VERSION ""

NS_ :

BS_:

BU_: LECU25 LECU23 LECU22 LECU21 LECU19 LECU20 LECU18 LECU17 LECU16 LECU15 LECU14 LECU12 LECU11 LECU10 LECU9 LECU8 LECU7 LECU6 LECU5 LECU4 LECU2 LECU31 LECU30 LECU29 LECU28 LECU27 LECU26 LECU24 LECU13 LECU3 LECU1 BMU Tester LECU32 Host IVT_Mod
VAL_TABLE_ Heating_OverTemperature_Flag 1 "High" 0 "Normal" ;
VAL_TABLE_ GeneralTrueFalse_Value_Table 1 "Error" 0 "Normal" ;
VAL_TABLE_ GeneralErr_Value_Table 3 "EPO" 2 "Alarm" 1 "Warning" 0 "Normal" ;
VAL_TABLE_ Balance_Control 1 "on" 0 "off" ;
VAL_TABLE_ Local_CAN_COM_SYN 1 "执行" 0 "停止" ;
VAL_TABLE_ Control_Code 1 "执行" 0 "停止" ;
VAL_TABLE_ ErrorCode_Tem_High 4 "一级" 3 "二级" 2 "三级" 1 "四级" 0 "正常" ;
VAL_TABLE_ ErrorCode_Voltage_High 4 "一级" 3 "二级" 2 "三级" 1 "四级" 0 "正常" ;
VAL_TABLE_ ErrorCode_Voltage_Low 3 "二级" 2 "三级" 1 "四级" 0 "正常" ;
VAL_TABLE_ LECU_ErrorCode 3284 "第12节电池电压差异较大" 3028 "第11节电池电压差异较大" 2772 "第10节电池电压差异较大" 2516 "第9节电池电压差异较大" 2260 "第8节电池电压差异较大" 2004 "第7节电池电压差异较大" 1748 "第6节电池电压差异较大" 1492 "第5节电池电压差异较大" 1236 "第4节电池电压差异较大" 980 "第3节电池电压差异较大" 724 "第2节电池电压差异较大" 468 "第1节电池电压差异较大" 3283 "第12节电池电压差异大" 3282 "第12节电池电压差异很大" 3252 "第12节电池电压较低" 3027 "第11节电池电压差异大" 3026 "第11节电池电压差异很大" 2996 "第11节电池电压较低" 2771 "第10节电池电压差异大" 2770 "第10节电池电压差异很大" 2740 "第10节电池电压较低" 2515 "第9节电池电压差异大" 2514 "第9节电池电压差异很大" 2484 "第9节电池电压较低" 2259 "第8节电池电压差异大" 2258 "第8节电池电压差异很大" 2228 "第8节电池电压较低" 2003 "第7节电池电压差异大" 2002 "第7节电池电压差异很大" 1972 "第7节电池电压较低" 1747 "第6节电池电压差异大" 1746 "第6节电池电压差异很大" 1716 "第6节电池电压较低" 1491 "第5节电池电压差异大" 1490 "第5节电池电压差异很大" 1460 "第5节电池电压较低" 1235 "第4节电池电压差异大" 1234 "第4节电池电压差异很大" 1204 "第4节电池电压较低" 979 "第3节电池电压差异大" 978 "第3节电池电压差异很大" 948 "第3节电池电压较低" 723 "第2节电池电压差异大" 722 "第2节电池电压差异很大" 692 "第2节电池电压较低" 467 "第1节电池电压差异大" 466 "第1节电池电压差异很大" 436 "第1节电池电压较低" 3251 "第12节电池电压低" 3250 "第12节电池电压很低" 3236 "第12节电池电压较高" 3235 "第12节电池电压高" 2995 "第11节电池电压低" 2994 "第11节电池电压很低" 2980 "第11节电池电压较高" 2979 "第11节电池电压高" 2739 "第10节电池电压低" 2738 "第10节电池电压很低" 2724 "第10节电池电压较高" 2723 "第10节电池电压高" 2483 "第9节电池电压低" 2482 "第9节电池电压很低" 2468 "第9节电池电压较高" 2467 "第9节电池电压高" 2227 "第8节电池电压低" 2226 "第8节电池电压很低" 2212 "第8节电池电压较高" 2211 "第8节电池电压高" 1971 "第7节电池电压低" 1970 "第7节电池电压很低" 1956 "第7节电池电压较高" 1955 "第7节电池电压高" 1715 "第6节电池电压低" 1714 "第6节电池电压很低" 1700 "第6节电池电压较高" 1699 "第6节电池电压高" 1459 "第5节电池电压低" 1458 "第5节电池电压很低" 1444 "第5节电池电压较高" 1443 "第5节电池电压高" 1203 "第4节电池电压低" 1202 "第4节电池电压很低" 1188 "第4节电池电压较高" 1187 "第4节电池电压高" 947 "第3节电池电压低" 946 "第3节电池电压很低" 932 "第3节电池电压较高" 931 "第3节电池电压高" 691 "第2节电池电压低" 690 "第2节电池电压很低" 676 "第2节电池电压较高" 675 "第2节电池电压高" 435 "第1节电池电压低" 434 "第1节电池电压很低" 420 "第1节电池电压较高" 419 "第1节电池电压高" 3234 "第12节电池电压很高" 3233 "第12节电池电压极高" 3188 "第12节电池温度较高" 3187 "第12节电池温度高" 3186 "第12节电池温度很高" 3185 "第12节电池温度极高" 3172 "第12节电池温度差异较大 " 2978 "第11节电池电压很高" 2977 "第11节电池电压极高" 2932 "第11节电池温度较高" 2931 "第11节电池温度高" 2930 "第11节电池温度很高" 2929 "第11节电池温度极高" 2916 "第11节电池温度差异较大 " 2722 "第10节电池电压很高" 2721 "第10节电池电压极高" 2676 "第10节电池温度较高" 2675 "第10节电池温度高" 2674 "第10节电池温度很高" 2673 "第10节电池温度极高" 2660 "第10节电池温度差异较大 " 2466 "第9节电池电压很高" 2465 "第9节电池电压极高" 2420 "第9节电池温度较高" 2419 "第9节电池温度高" 2418 "第9节电池温度很高" 2417 "第9节电池温度极高" 2404 "第9节电池温度差异较大 " 2210 "第8节电池电压很高" 2209 "第8节电池电压极高" 2164 "第8节电池温度较高" 2163 "第8节电池温度高" 2162 "第8节电池温度很高" 2161 "第8节电池温度极高" 2148 "第8节电池温度差异较大 " 1954 "第7节电池电压很高" 1953 "第7节电池电压极高" 1908 "第7节电池温度较高" 1907 "第7节电池温度高" 1906 "第7节电池温度很高" 1905 "第7节电池温度极高" 1892 "第7节电池温度差异较大 " 1698 "第6节电池电压很高" 1697 "第6节电池电压极高" 1652 "第6节电池温度较高" 1651 "第6节电池温度高" 1650 "第6节电池温度很高" 1649 "第6节电池温度极高" 1636 "第6节电池温度差异较大 " 1442 "第5节电池电压很高" 1441 "第5节电池电压极高" 1396 "第5节电池温度较高" 1395 "第5节电池温度高" 1394 "第5节电池温度很高" 1393 "第5节电池温度极高" 1380 "第5节电池温度差异较大 " 1186 "第4节电池电压很高" 1185 "第4节电池电压极高" 1140 "第4节电池温度较高" 1139 "第4节电池温度高" 1138 "第4节电池温度很高" 1137 "第4节电池温度极高" 1124 "第4节电池温度差异较大 " 930 "第3节电池电压很高" 929 "第3节电池电压极高" 884 "第3节电池温度较高" 883 "第3节电池温度高" 882 "第3节电池温度很高" 881 "第3节电池温度极高" 868 "第3节电池温度差异较大 " 674 "第2节电池电压很高" 673 "第2节电池电压极高" 628 "第2节电池温度较高" 627 "第2节电池温度高" 626 "第2节电池温度很高" 625 "第2节电池温度极高" 612 "第2节电池温度差异较大 " 418 "第1节电池电压很高" 417 "第1节电池电压极高" 372 "第1节电池温度较高" 371 "第1节电池温度高" 370 "第1节电池温度很高" 369 "第1节电池温度极高" 356 "第1节电池温度差异较大 " 3171 "第12节电池温度差异大 " 2915 "第11节电池温度差异大 " 2659 "第10节电池温度差异大 " 2403 "第9节电池温度差异大 " 2147 "第8节电池温度差异大 " 1891 "第7节电池温度差异大 " 1635 "第6节电池温度差异大 " 1379 "第5节电池温度差异大 " 1123 "第4节电池温度差异大 " 867 "第3节电池温度差异大 " 611 "第2节电池温度差异大 " 3170 "第12节电池温度差异很大" 3169 "第12节电池温度差异极大" 2914 "第11节电池温度差异很大" 2913 "第11节电池温度差异极大" 2658 "第10节电池温度差异很大" 2657 "第10节电池温度差异极大" 2402 "第9节电池温度差异很大" 2401 "第9节电池温度差异极大" 2146 "第8节电池温度差异很大" 2145 "第8节电池温度差异极大" 1890 "第7节电池温度差异很大" 1889 "第7节电池温度差异极大" 1634 "第6节电池温度差异很大" 1633 "第6节电池温度差异极大" 1378 "第5节电池温度差异很大" 1377 "第5节电池温度差异极大" 1122 "第4节电池温度差异很大" 1121 "第4节电池温度差异极大" 866 "第3节电池温度差异很大" 865 "第3节电池温度差异极大" 610 "第2节电池温度差异很大" 609 "第2节电池温度差异极大" 355 "第1节电池温度差异大 " 354 "第1节电池温度差异很大" 353 "第1节电池温度差异极大" ;

BO_ 3221225472 VECTOR__INDEPENDENT_SIG_MSG: 0 Vector__XXX
 SG_ Local_CtrFb_PosConnector : 0|1@0+ (1,0) [0|0] "" Vector__XXX
 SG_ Local_CtrFb_NegConnector : 0|1@0+ (1,0) [0|0] "" Vector__XXX
 SG_ Local_CtrFb_FcgConnector : 0|1@0+ (1,0) [0|0] "" Vector__XXX
 SG_ Local_CtrFb_ChgConnector : 0|1@0+ (1,0) [0|0] "" Vector__XXX
 SG_ Local_CtrFb_PreChgConnector : 0|1@0+ (1,0) [0|0] "" Vector__XXX
 SG_ Local_Res_IsolationPos : 0|16@0+ (1,0) [0|0] "KΩ" Vector__XXX
 SG_ Local_Res_IsolationNeg : 0|16@0+ (1,0) [0|0] "KΩ" Vector__XXX

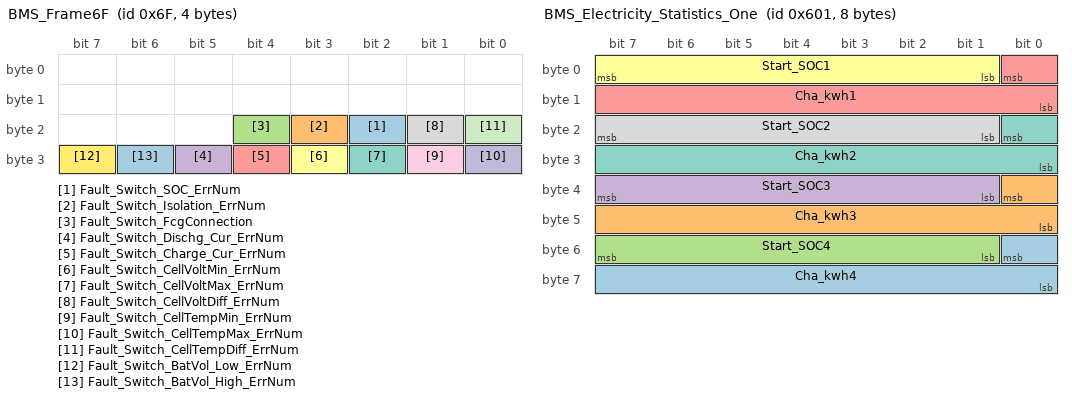
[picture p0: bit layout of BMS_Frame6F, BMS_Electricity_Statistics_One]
BO_ 111 BMS_Frame6F: 4 Vector__XXX
 SG_ Fault_Switch_SOC_ErrNum : 18|1@1+ (1,0) [0|0] "" Vector__XXX
 SG_ Fault_Switch_Isolation_ErrNum : 19|1@1+ (1,0) [0|0] "" Vector__XXX
 SG_ Fault_Switch_FcgConnection : 20|1@1+ (1,0) [0|0] "" Vector__XXX
 SG_ Fault_Switch_Dischg_Cur_ErrNum : 29|1@1+ (1,0) [0|0] "" Vector__XXX
 SG_ Fault_Switch_Charge_Cur_ErrNum : 28|1@1+ (1,0) [0|0] "" Vector__XXX
 SG_ Fault_Switch_CellVoltMin_ErrNum : 27|1@1+ (1,0) [0|0] "" Vector__XXX
 SG_ Fault_Switch_CellVoltMax_ErrNum : 26|1@1+ (1,0) [0|0] "" Vector__XXX
 SG_ Fault_Switch_CellVoltDiff_ErrNum : 17|1@1+ (1,0) [0|0] "" Vector__XXX
 SG_ Fault_Switch_CellTempMin_ErrNum : 25|1@1+ (1,0) [0|0] "" Vector__XXX
 SG_ Fault_Switch_CellTempMax_ErrNum : 24|1@1+ (1,0) [0|0] "" Vector__XXX
 SG_ Fault_Switch_CellTempDiff_ErrNum : 16|1@1+ (1,0) [0|0] "" Vector__XXX
 SG_ Fault_Switch_BatVol_Low_ErrNum : 31|1@1+ (1,0) [0|0] "" Vector__XXX
 SG_ Fault_Switch_BatVol_High_ErrNum : 30|1@1+ (1,0) [0|0] "" Vector__XXX

BO_ 101 BMS_Frame15: 8 Vector__XXX
 SG_ Local_Curr_Bus_Copy_3 : 39|16@0+ (0.1,-3200) [0|0] "A" Vector__XXX
 SG_ Local_Curr_Bus_Copy_2 : 23|16@0+ (0.1,-3200) [0|0] "A" Vector__XXX
 SG_ Local_Curr_Bus_Copy_1 : 7|16@0+ (0.1,-3200) [0|0] "A" Vector__XXX
 SG_ Local_Curr_Bus : 55|16@0+ (0.1,-3200) [0|0] "A" Vector__XXX

BO_ 100 BMS_Frame14: 8 Vector__XXX
 SG_ Local_Curr_Bus_Copy_3 : 39|16@0+ (0.1,-3200) [0|0] "A" Vector__XXX
 SG_ Local_Curr_Bus_Copy_2 : 23|16@0+ (0.1,-3200) [0|0] "A" Vector__XXX
 SG_ Local_Curr_Bus_Copy_1 : 7|16@0+ (0.1,-3200) [0|0] "A" Vector__XXX
 SG_ Local_Curr_Bus : 55|16@0+ (0.1,-3200) [0|0] "A" Vector__XXX

BO_ 261 BMS_External_Cmd: 8 Vector__XXX
 SG_ External_Sleep_Cmd : 15|8@0+ (1,0) [0|0] ""  BMU
 SG_ External_Fcg_Cmd : 7|8@0+ (1,0) [0|0] ""  BMU

BO_ 1520 Local_ShH_IsoMsg: 8 Vector__XXX
 SG_ Local_ShH_Volt : 31|16@0+ (1,0) [0|0] "V"  BMU
 SG_ Local_ShH_LifeSignal : 63|8@0+ (1,0) [0|0] ""  BMU
 SG_ Local_ShH_IsoResistance : 15|16@0+ (1,0) [0|0] "kΩ"  BMU
 SG_ Local_ShH_IsoMonitorState : 3|4@0+ (1,0) [0|0] ""  BMU
 SG_ Local_ShH_IsoFault : 5|2@0- (1,0) [0|0] ""  BMU

BO_ 1320 IVT_Msg_Result_Wh: 6 Vector__XXX
 SG_ IVT_Result_Wh : 23|32@0- (1,0) [0|0] "Wh"  BMU

BO_ 1316 IVT_Msg_Result_U3: 6 Vector__XXX
 SG_ IVT_Result_U3 : 23|32@0- (1,0) [0|0] "mV"  BMU

BO_ 1315 IVT_Msg_Result_U2: 6 Vector__XXX
 SG_ IVT_Result_U2 : 23|32@0- (1,0) [0|0] "mV"  BMU

BO_ 1314 IVT_Msg_Result_U1: 6 Vector__XXX
 SG_ IVT_Result_U1 : 23|32@0- (1,0) [0|0] "mV"  BMU

BO_ 1317 IVT_Msg_Result_T: 6 Vector__XXX
 SG_ IVT_Result_T : 23|32@0- (0.1,0) [0|0] "℃"  BMU

BO_ 1313 IVT_Msg_Result_I: 6 Vector__XXX
 SG_ IVT_Result_I : 23|32@0- (1,0) [0|0] "mA"  BMU

BO_ 260 BMS_LECUTemBlock: 8 Vector__XXX
 SG_ Block_peak2_TemCHN : 23|16@0+ (1,0) [0|0] "" Vector__XXX
 SG_ CellMoreThan5Temp : 34|6@0+ (1,0) [0|0] "" Vector__XXX
 SG_ BlockTemNUM : 39|4@0+ (1,0) [0|0] "" Vector__XXX
 SG_ Block_peak1_TemCHN : 7|16@0+ (1,0) [0|0] "" Vector__XXX

BO_ 259 BMS_Heating_CMD: 8 Vector__XXX
 SG_ DisCharge_Heating_cmd : 7|8@0+ (1,0) [0|0] ""  BMU
 SG_ Charge_Heating_cmd : 15|8@0+ (1,0) [0|0] ""  BMU

BO_ 258 BMS_Emergency_PowerON: 8 Vector__XXX
 SG_ Emergency_Running_Cmd : 15|8@0+ (1,0) [0|255] ""  BMU
 SG_ Emergency_PowerON_Cmd : 7|8@0+ (1,0) [0|0] ""  BMU

BO_ 1537 BMS_Electricity_Statistics_One: 8 BMU
 SG_ Cha_kwh4 : 48|9@0+ (1,0) [0|511] "kwh" Vector__XXX
 SG_ Cha_kwh3 : 32|9@0+ (1,0) [0|511] "kwh" Vector__XXX
 SG_ Start_SOC4 : 55|7@0+ (1,0) [0|127] "%" Vector__XXX
 SG_ Start_SOC3 : 39|7@0+ (1,0) [0|127] "%" Vector__XXX
 SG_ Cha_kwh1 : 0|9@0+ (1,0) [0|511] "kwh" Vector__XXX
 SG_ Start_SOC1 : 7|7@0+ (1,0) [0|127] "%" Vector__XXX
 SG_ Cha_kwh2 : 16|9@0+ (1,0) [0|511] "kwh" Vector__XXX
 SG_ Start_SOC2 : 23|7@0+ (1,0) [0|127] "%" Vector__XXX

BO_ 274 Lecu1MsgB: 8 Vector__XXX
 SG_ M1_Heating_OverTemp_Flag : 27|1@1+ (1,0) [0|0] ""  BMU
 SG_ M1_TempFault : 29|1@1+ (1,0) [0|0] ""  BMU
 SG_ M1_BatteryLost_Error : 28|1@1+ (1,0) [0|0] ""  BMU
 SG_ M1_JumperTemp_Max m1 : 48|11@1+ (0.1,-40) [0|0] "℃"  BMU
 SG_ M1_BalanceTemp_Max m0 : 48|11@1+ (0.1,-40) [0|0] "℃"  BMU
 SG_ M1_BalanceFailure : 30|1@1+ (1,0) [0|0] ""  BMU
 SG_ M1_Tem_Min_Num : 40|3@1+ (1,0) [0|0] ""  BMU
 SG_ M1_Tem_Max_Num : 32|3@1+ (1,0) [0|0] ""  BMU
 SG_ M1_CellVoltageMin_Num : 43|5@1+ (1,0) [0|31] ""  BMU
 SG_ M1_CellVoltageMax_Num : 35|5@1+ (1,0) [0|31] ""  BMU
 SG_ M1_JumperTemp_Max_Valid m1 : 63|1@1+ (1,0) [0|0] ""  BMU
 SG_ M1_BalanceTemp_Max_Valid m0 : 63|1@1+ (1,0) [0|0] ""  BMU
 SG_ M1_Temp_Choice M : 59|4@1+ (1,0) [0|0] ""  BMU
 SG_ M1_Tem_Mean_Valid : 31|1@1+ (1,0) [0|0] ""  BMU
 SG_ M1_CellVoltageMean_Valid : 15|1@1+ (1,0) [0|0] ""  BMU
 SG_ M1_Tem_Mean : 16|11@1+ (0.1,-40) [0|0] "℃"  BMU
 SG_ M1_CellVoltageMean : 0|15@1- (0.001,0) [0|0] "V"  BMU

BO_ 618 Lecu22MsgI: 8 Vector__XXX
 SG_ M22_Time_Cell1Balance : 0|16@1+ (0.5,0) [0|0] "Hour" Vector__XXX
 SG_ M22_Time_Cell2Balance : 16|16@1+ (0.5,0) [0|0] "Hour" Vector__XXX
 SG_ M22_Time_Cell3Balance : 32|16@1+ (0.5,0) [0|0] "Hour" Vector__XXX
 SG_ M22_Time_Cell4Balance : 48|16@1+ (0.5,0) [0|0] "Hour" Vector__XXX

BO_ 684 Lecu26MsgK: 8 Vector__XXX
 SG_ M26_Time_Cell10Balance : 16|16@1+ (0.5,0) [0|0] "Hour" Vector__XXX
 SG_ M26_Time_Cell11Balance : 32|16@1+ (0.5,0) [0|0] "Hour" Vector__XXX
 SG_ M26_Time_Cell12Balance : 48|16@1+ (0.5,0) [0|0] "Hour" Vector__XXX
 SG_ M26_Time_Cell9Balance : 0|16@1+ (0.5,0) [0|0] "Hour" Vector__XXX

BO_ 683 Lecu26MsgJ: 8 Vector__XXX
 SG_ M26_Time_Cell8Balance : 48|16@1+ (0.5,0) [0|0] "Hour" Vector__XXX
 SG_ M26_Time_Cell7Balance : 32|16@1+ (0.5,0) [0|0] "Hour" Vector__XXX
 SG_ M26_Time_Cell6Balance : 16|16@1+ (0.5,0) [0|0] "Hour" Vector__XXX
 SG_ M26_Time_Cell5Balance : 0|16@1+ (0.5,0) [0|0] "Hour" Vector__XXX

BO_ 730 Lecu29MsgI: 8 Vector__XXX
 SG_ M29_Time_Cell4Balance : 48|16@1+ (0.5,0) [0|0] "Hour" Vector__XXX
 SG_ M29_Time_Cell3Balance : 32|16@1+ (0.5,0) [0|0] "Hour" Vector__XXX
 SG_ M29_Time_Cell2Balance : 16|16@1+ (0.5,0) [0|0] "Hour" Vector__XXX
 SG_ M29_Time_Cell1Balance : 0|16@1+ (0.5,0) [0|0] "Hour" Vector__XXX

BO_ 668 Lecu25MsgK: 8 Vector__XXX
 SG_ M25_Time_Cell10Balance : 16|16@1+ (0.5,0) [0|0] "Hour" Vector__XXX
 SG_ M25_Time_Cell11Balance : 32|16@1+ (0.5,0) [0|0] "Hour" Vector__XXX
 SG_ M25_Time_Cell12Balance : 48|16@1+ (0.5,0) [0|0] "Hour" Vector__XXX
 SG_ M25_Time_Cell9Balance : 0|16@1+ (0.5,0) [0|0] "Hour" Vector__XXX

BO_ 667 Lecu25MsgJ: 8 Vector__XXX
 SG_ M25_Time_Cell8Balance : 48|16@1+ (0.5,0) [0|0] "Hour" Vector__XXX
 SG_ M25_Time_Cell7Balance : 32|16@1+ (0.5,0) [0|0] "Hour" Vector__XXX
 SG_ M25_Time_Cell6Balance : 16|16@1+ (0.5,0) [0|0] "Hour" Vector__XXX
 SG_ M25_Time_Cell5Balance : 0|16@1+ (0.5,0) [0|0] "Hour" Vector__XXX

BO_ 746 Lecu30MsgI: 8 Vector__XXX
 SG_ M30_Time_Cell4Balance : 48|16@1+ (0.5,0) [0|0] "Hour" Vector__XXX
 SG_ M30_Time_Cell3Balance : 32|16@1+ (0.5,0) [0|0] "Hour" Vector__XXX
 SG_ M30_Time_Cell2Balance : 16|16@1+ (0.5,0) [0|0] "Hour" Vector__XXX
 SG_ M30_Time_Cell1Balance : 0|16@1+ (0.5,0) [0|0] "Hour" Vector__XXX

BO_ 636 Lecu23MsgK: 8 Vector__XXX
 SG_ M23_Time_Cell10Balance : 16|16@1+ (0.5,0) [0|0] "Hour" Vector__XXX
 SG_ M23_Time_Cell11Balance : 32|16@1+ (0.5,0) [0|0] "Hour" Vector__XXX
 SG_ M23_Time_Cell12Balance : 48|16@1+ (0.5,0) [0|0] "Hour" Vector__XXX
 SG_ M23_Time_Cell9Balance : 0|16@1+ (0.5,0) [0|0] "Hour" Vector__XXX

BO_ 635 Lecu23MsgJ: 8 Vector__XXX
 SG_ M23_Time_Cell8Balance : 48|16@1+ (0.5,0) [0|0] "Hour" Vector__XXX
 SG_ M23_Time_Cell7Balance : 32|16@1+ (0.5,0) [0|0] "Hour" Vector__XXX
 SG_ M23_Time_Cell6Balance : 16|16@1+ (0.5,0) [0|0] "Hour" Vector__XXX
 SG_ M23_Time_Cell5Balance : 0|16@1+ (0.5,0) [0|0] "Hour" Vector__XXX

BO_ 778 Lecu32MsgI: 8 Vector__XXX
 SG_ M32_Time_Cell4Balance : 48|16@1+ (0.5,0) [0|0] "Hour" Vector__XXX
 SG_ M32_Time_Cell3Balance : 32|16@1+ (0.5,0) [0|0] "Hour" Vector__XXX
 SG_ M32_Time_Cell2Balance : 16|16@1+ (0.5,0) [0|0] "Hour" Vector__XXX
 SG_ M32_Time_Cell1Balance : 0|16@1+ (0.5,0) [0|0] "Hour" Vector__XXX

BO_ 620 Lecu22MsgK: 8 Vector__XXX
 SG_ M22_Time_Cell10Balance : 16|16@1+ (0.5,0) [0|0] "Hour" Vector__XXX
 SG_ M22_Time_Cell11Balance : 32|16@1+ (0.5,0) [0|0] "Hour" Vector__XXX
 SG_ M22_Time_Cell12Balance : 48|16@1+ (0.5,0) [0|0] "Hour" Vector__XXX
 SG_ M22_Time_Cell9Balance : 0|16@1+ (0.5,0) [0|0] "Hour" Vector__XXX

BO_ 619 Lecu22MsgJ: 8 Vector__XXX
 SG_ M22_Time_Cell8Balance : 48|16@1+ (0.5,0) [0|0] "Hour" Vector__XXX
 SG_ M22_Time_Cell7Balance : 32|16@1+ (0.5,0) [0|0] "Hour" Vector__XXX
 SG_ M22_Time_Cell6Balance : 16|16@1+ (0.5,0) [0|0] "Hour" Vector__XXX
 SG_ M22_Time_Cell5Balance : 0|16@1+ (0.5,0) [0|0] "Hour" Vector__XXX

BO_ 602 Lecu21MsgI: 8 Vector__XXX
 SG_ M21_Time_Cell4Balance : 48|16@1+ (0.5,0) [0|0] "Hour" Vector__XXX
 SG_ M21_Time_Cell3Balance : 32|16@1+ (0.5,0) [0|0] "Hour" Vector__XXX
 SG_ M21_Time_Cell2Balance : 16|16@1+ (0.5,0) [0|0] "Hour" Vector__XXX
 SG_ M21_Time_Cell1Balance : 0|16@1+ (0.5,0) [0|0] "Hour" Vector__XXX

BO_ 604 Lecu21MsgK: 8 Vector__XXX
 SG_ M21_Time_Cell10Balance : 16|16@1+ (0.5,0) [0|0] "Hour" Vector__XXX
 SG_ M21_Time_Cell11Balance : 32|16@1+ (0.5,0) [0|0] "Hour" Vector__XXX
 SG_ M21_Time_Cell12Balance : 48|16@1+ (0.5,0) [0|0] "Hour" Vector__XXX
 SG_ M21_Time_Cell9Balance : 0|16@1+ (0.5,0) [0|0] "Hour" Vector__XXX

BO_ 603 Lecu21MsgJ: 8 Vector__XXX
 SG_ M21_Time_Cell8Balance : 48|16@1+ (0.5,0) [0|0] "Hour" Vector__XXX
 SG_ M21_Time_Cell7Balance : 32|16@1+ (0.5,0) [0|0] "Hour" Vector__XXX
 SG_ M21_Time_Cell6Balance : 16|16@1+ (0.5,0) [0|0] "Hour" Vector__XXX
 SG_ M21_Time_Cell5Balance : 0|16@1+ (0.5,0) [0|0] "Hour" Vector__XXX

BO_ 586 Lecu20MsgI: 8 Vector__XXX
 SG_ M20_Time_Cell4Balance : 48|16@1+ (0.5,0) [0|0] "Hour" Vector__XXX
 SG_ M20_Time_Cell3Balance : 32|16@1+ (0.5,0) [0|0] "Hour" Vector__XXX
 SG_ M20_Time_Cell2Balance : 16|16@1+ (0.5,0) [0|0] "Hour" Vector__XXX
 SG_ M20_Time_Cell1Balance : 0|16@1+ (0.5,0) [0|0] "Hour" Vector__XXX

BO_ 588 Lecu20MsgK: 8 Vector__XXX
 SG_ M20_Time_Cell10Balance : 16|16@1+ (0.5,0) [0|0] "Hour" Vector__XXX
 SG_ M20_Time_Cell11Balance : 32|16@1+ (0.5,0) [0|0] "Hour" Vector__XXX
 SG_ M20_Time_Cell12Balance : 48|16@1+ (0.5,0) [0|0] "Hour" Vector__XXX
 SG_ M20_Time_Cell9Balance : 0|16@1+ (0.5,0) [0|0] "Hour" Vector__XXX

BO_ 587 Lecu20MsgJ: 8 Vector__XXX
 SG_ M20_Time_Cell8Balance : 48|16@1+ (0.5,0) [0|0] "Hour" Vector__XXX
 SG_ M20_Time_Cell7Balance : 32|16@1+ (0.5,0) [0|0] "Hour" Vector__XXX
 SG_ M20_Time_Cell6Balance : 16|16@1+ (0.5,0) [0|0] "Hour" Vector__XXX
 SG_ M20_Time_Cell5Balance : 0|16@1+ (0.5,0) [0|0] "Hour" Vector__XXX

BO_ 570 Lecu19MsgI: 8 Vector__XXX
 SG_ M19_Time_Cell4Balance : 48|16@1+ (0.5,0) [0|0] "Hour" Vector__XXX
 SG_ M19_Time_Cell3Balance : 32|16@1+ (0.5,0) [0|0] "Hour" Vector__XXX
 SG_ M19_Time_Cell2Balance : 16|16@1+ (0.5,0) [0|0] "Hour" Vector__XXX
 SG_ M19_Time_Cell1Balance : 0|16@1+ (0.5,0) [0|0] "Hour" Vector__XXX

BO_ 572 Lecu19MsgK: 8 Vector__XXX
 SG_ M19_Time_Cell10Balance : 16|16@1+ (0.5,0) [0|0] "Hour" Vector__XXX
 SG_ M19_Time_Cell11Balance : 32|16@1+ (0.5,0) [0|0] "Hour" Vector__XXX
 SG_ M19_Time_Cell12Balance : 48|16@1+ (0.5,0) [0|0] "Hour" Vector__XXX
 SG_ M19_Time_Cell9Balance : 0|16@1+ (0.5,0) [0|0] "Hour" Vector__XXX

BO_ 571 Lecu19MsgJ: 8 Vector__XXX
 SG_ M19_Time_Cell8Balance : 48|16@1+ (0.5,0) [0|0] "Hour" Vector__XXX
 SG_ M19_Time_Cell7Balance : 32|16@1+ (0.5,0) [0|0] "Hour" Vector__XXX
 SG_ M19_Time_Cell6Balance : 16|16@1+ (0.5,0) [0|0] "Hour" Vector__XXX
 SG_ M19_Time_Cell5Balance : 0|16@1+ (0.5,0) [0|0] "Hour" Vector__XXX

BO_ 554 Lecu18MsgI: 8 Vector__XXX
 SG_ M18_Time_Cell4Balance : 48|16@1+ (0.5,0) [0|0] "Hour" Vector__XXX
 SG_ M18_Time_Cell3Balance : 32|16@1+ (0.5,0) [0|0] "Hour" Vector__XXX
 SG_ M18_Time_Cell2Balance : 16|16@1+ (0.5,0) [0|0] "Hour" Vector__XXX
 SG_ M18_Time_Cell1Balance : 0|16@1+ (0.5,0) [0|0] "Hour" Vector__XXX

BO_ 556 Lecu18MsgK: 8 Vector__XXX
 SG_ M18_Time_Cell10Balance : 16|16@1+ (0.5,0) [0|0] "Hour" Vector__XXX
 SG_ M18_Time_Cell11Balance : 32|16@1+ (0.5,0) [0|0] "Hour" Vector__XXX
 SG_ M18_Time_Cell12Balance : 48|16@1+ (0.5,0) [0|0] "Hour" Vector__XXX
 SG_ M18_Time_Cell9Balance : 0|16@1+ (0.5,0) [0|0] "Hour" Vector__XXX

BO_ 555 Lecu18MsgJ: 8 Vector__XXX
 SG_ M18_Time_Cell8Balance : 48|16@1+ (0.5,0) [0|0] "Hour" Vector__XXX
 SG_ M18_Time_Cell7Balance : 32|16@1+ (0.5,0) [0|0] "Hour" Vector__XXX
 SG_ M18_Time_Cell6Balance : 16|16@1+ (0.5,0) [0|0] "Hour" Vector__XXX
 SG_ M18_Time_Cell5Balance : 0|16@1+ (0.5,0) [0|0] "Hour" Vector__XXX

BO_ 538 Lecu17MsgI: 8 Vector__XXX
 SG_ M17_Time_Cell4Balance : 48|16@1+ (0.5,0) [0|0] "Hour" Vector__XXX
 SG_ M17_Time_Cell3Balance : 32|16@1+ (0.5,0) [0|0] "Hour" Vector__XXX
 SG_ M17_Time_Cell2Balance : 16|16@1+ (0.5,0) [0|0] "Hour" Vector__XXX
 SG_ M17_Time_Cell1Balance : 0|16@1+ (0.5,0) [0|0] "Hour" Vector__XXX

BO_ 540 Lecu17MsgK: 8 Vector__XXX
 SG_ M17_Time_Cell10Balance : 16|16@1+ (0.5,0) [0|0] "Hour" Vector__XXX
 SG_ M17_Time_Cell11Balance : 32|16@1+ (0.5,0) [0|0] "Hour" Vector__XXX
 SG_ M17_Time_Cell12Balance : 48|16@1+ (0.5,0) [0|0] "Hour" Vector__XXX
 SG_ M17_Time_Cell9Balance : 0|16@1+ (0.5,0) [0|0] "Hour" Vector__XXX

BO_ 539 Lecu17MsgJ: 8 Vector__XXX
 SG_ M17_Time_Cell8Balance : 48|16@1+ (0.5,0) [0|0] "Hour" Vector__XXX
 SG_ M17_Time_Cell7Balance : 32|16@1+ (0.5,0) [0|0] "Hour" Vector__XXX
 SG_ M17_Time_Cell6Balance : 16|16@1+ (0.5,0) [0|0] "Hour" Vector__XXX
 SG_ M17_Time_Cell5Balance : 0|16@1+ (0.5,0) [0|0] "Hour" Vector__XXX

BO_ 522 Lecu16MsgI: 8 Vector__XXX
 SG_ M16_Time_Cell4Balance : 48|16@1+ (0.5,0) [0|0] "Hour" Vector__XXX
 SG_ M16_Time_Cell3Balance : 32|16@1+ (0.5,0) [0|0] "Hour" Vector__XXX
 SG_ M16_Time_Cell2Balance : 16|16@1+ (0.5,0) [0|0] "Hour" Vector__XXX
 SG_ M16_Time_Cell1Balance : 0|16@1+ (0.5,0) [0|0] "Hour" Vector__XXX

BO_ 524 Lecu16MsgK: 8 Vector__XXX
 SG_ M16_Time_Cell10Balance : 16|16@1+ (0.5,0) [0|0] "Hour" Vector__XXX
 SG_ M16_Time_Cell11Balance : 32|16@1+ (0.5,0) [0|0] "Hour" Vector__XXX
 SG_ M16_Time_Cell12Balance : 48|16@1+ (0.5,0) [0|0] "Hour" Vector__XXX
 SG_ M16_Time_Cell9Balance : 0|16@1+ (0.5,0) [0|0] "Hour" Vector__XXX

BO_ 523 Lecu16MsgJ: 8 Vector__XXX
 SG_ M16_Time_Cell8Balance : 48|16@1+ (0.5,0) [0|0] "Hour" Vector__XXX
 SG_ M16_Time_Cell7Balance : 32|16@1+ (0.5,0) [0|0] "Hour" Vector__XXX
 SG_ M16_Time_Cell6Balance : 16|16@1+ (0.5,0) [0|0] "Hour" Vector__XXX
 SG_ M16_Time_Cell5Balance : 0|16@1+ (0.5,0) [0|0] "Hour" Vector__XXX

BO_ 506 Lecu15MsgI: 8 Vector__XXX
 SG_ M15_Time_Cell4Balance : 48|16@1+ (0.5,0) [0|0] "Hour" Vector__XXX
 SG_ M15_Time_Cell3Balance : 32|16@1+ (0.5,0) [0|0] "Hour" Vector__XXX
 SG_ M15_Time_Cell2Balance : 16|16@1+ (0.5,0) [0|0] "Hour" Vector__XXX
 SG_ M15_Time_Cell1Balance : 0|16@1+ (0.5,0) [0|0] "Hour" Vector__XXX

BO_ 508 Lecu15MsgK: 8 Vector__XXX
 SG_ M15_Time_Cell10Balance : 16|16@1+ (0.5,0) [0|0] "Hour" Vector__XXX
 SG_ M15_Time_Cell11Balance : 32|16@1+ (0.5,0) [0|0] "Hour" Vector__XXX
 SG_ M15_Time_Cell12Balance : 48|16@1+ (0.5,0) [0|0] "Hour" Vector__XXX
 SG_ M15_Time_Cell9Balance : 0|16@1+ (0.5,0) [0|0] "Hour" Vector__XXX

BO_ 507 Lecu15MsgJ: 8 Vector__XXX
 SG_ M15_Time_Cell8Balance : 48|16@1+ (0.5,0) [0|0] "Hour" Vector__XXX
 SG_ M15_Time_Cell7Balance : 32|16@1+ (0.5,0) [0|0] "Hour" Vector__XXX
 SG_ M15_Time_Cell6Balance : 16|16@1+ (0.5,0) [0|0] "Hour" Vector__XXX
 SG_ M15_Time_Cell5Balance : 0|16@1+ (0.5,0) [0|0] "Hour" Vector__XXX

BO_ 490 Lecu14MsgI: 8 Vector__XXX
 SG_ M14_Time_Cell4Balance : 48|16@1+ (0.5,0) [0|0] "Hour" Vector__XXX
 SG_ M14_Time_Cell3Balance : 32|16@1+ (0.5,0) [0|0] "Hour" Vector__XXX
 SG_ M14_Time_Cell2Balance : 16|16@1+ (0.5,0) [0|0] "Hour" Vector__XXX
 SG_ M14_Time_Cell1Balance : 0|16@1+ (0.5,0) [0|0] "Hour" Vector__XXX

BO_ 492 Lecu14MsgK: 8 Vector__XXX
 SG_ M14_Time_Cell10Balance : 16|16@1+ (0.5,0) [0|0] "Hour" Vector__XXX
 SG_ M14_Time_Cell11Balance : 32|16@1+ (0.5,0) [0|0] "Hour" Vector__XXX
 SG_ M14_Time_Cell12Balance : 48|16@1+ (0.5,0) [0|0] "Hour" Vector__XXX
 SG_ M14_Time_Cell9Balance : 0|16@1+ (0.5,0) [0|0] "Hour" Vector__XXX

BO_ 491 Lecu14MsgJ: 8 Vector__XXX
 SG_ M14_Time_Cell8Balance : 48|16@1+ (0.5,0) [0|0] "Hour" Vector__XXX
 SG_ M14_Time_Cell7Balance : 32|16@1+ (0.5,0) [0|0] "Hour" Vector__XXX
 SG_ M14_Time_Cell6Balance : 16|16@1+ (0.5,0) [0|0] "Hour" Vector__XXX
 SG_ M14_Time_Cell5Balance : 0|16@1+ (0.5,0) [0|0] "Hour" Vector__XXX

BO_ 474 Lecu13MsgI: 8 Vector__XXX
 SG_ M13_Time_Cell4Balance : 48|16@1+ (0.5,0) [0|0] "Hour" Vector__XXX
 SG_ M13_Time_Cell3Balance : 32|16@1+ (0.5,0) [0|0] "Hour" Vector__XXX
 SG_ M13_Time_Cell2Balance : 16|16@1+ (0.5,0) [0|0] "Hour" Vector__XXX
 SG_ M13_Time_Cell1Balance : 0|16@1+ (0.5,0) [0|0] "Hour" Vector__XXX

BO_ 460 Lecu12MsgK: 8 Vector__XXX
 SG_ M12_Time_Cell10Balance : 16|16@1+ (0.5,0) [0|0] "Hour" Vector__XXX
 SG_ M12_Time_Cell11Balance : 32|16@1+ (0.5,0) [0|0] "Hour" Vector__XXX
 SG_ M12_Time_Cell12Balance : 48|16@1+ (0.5,0) [0|0] "Hour" Vector__XXX
 SG_ M12_Time_Cell9Balance : 0|16@1+ (0.5,0) [0|0] "Hour" Vector__XXX

BO_ 459 Lecu12MsgJ: 8 Vector__XXX
 SG_ M12_Time_Cell8Balance : 48|16@1+ (0.5,0) [0|0] "Hour" Vector__XXX
 SG_ M12_Time_Cell7Balance : 32|16@1+ (0.5,0) [0|0] "Hour" Vector__XXX
 SG_ M12_Time_Cell6Balance : 16|16@1+ (0.5,0) [0|0] "Hour" Vector__XXX
 SG_ M12_Time_Cell5Balance : 0|16@1+ (0.5,0) [0|0] "Hour" Vector__XXX

BO_ 442 Lecu11MsgI: 8 Vector__XXX
 SG_ M11_Time_Cell4Balance : 48|16@1+ (0.5,0) [0|0] "Hour" Vector__XXX
 SG_ M11_Time_Cell3Balance : 32|16@1+ (0.5,0) [0|0] "Hour" Vector__XXX
 SG_ M11_Time_Cell2Balance : 16|16@1+ (0.5,0) [0|0] "Hour" Vector__XXX
 SG_ M11_Time_Cell1Balance : 0|16@1+ (0.5,0) [0|0] "Hour" Vector__XXX

BO_ 444 Lecu11MsgK: 8 Vector__XXX
 SG_ M11_Time_Cell10Balance : 16|16@1+ (0.5,0) [0|0] "Hour" Vector__XXX
 SG_ M11_Time_Cell11Balance : 32|16@1+ (0.5,0) [0|0] "Hour" Vector__XXX
 SG_ M11_Time_Cell12Balance : 48|16@1+ (0.5,0) [0|0] "Hour" Vector__XXX
 SG_ M11_Time_Cell9Balance : 0|16@1+ (0.5,0) [0|0] "Hour" Vector__XXX

BO_ 443 Lecu11MsgJ: 8 Vector__XXX
 SG_ M11_Time_Cell8Balance : 48|16@1+ (0.5,0) [0|0] "Hour" Vector__XXX
 SG_ M11_Time_Cell7Balance : 32|16@1+ (0.5,0) [0|0] "Hour" Vector__XXX
 SG_ M11_Time_Cell6Balance : 16|16@1+ (0.5,0) [0|0] "Hour" Vector__XXX
 SG_ M11_Time_Cell5Balance : 0|16@1+ (0.5,0) [0|0] "Hour" Vector__XXX

BO_ 426 Lecu10MsgI: 8 Vector__XXX
 SG_ M10_Time_Cell4Balance : 48|16@1+ (0.5,0) [0|0] "Hour" Vector__XXX
 SG_ M10_Time_Cell3Balance : 32|16@1+ (0.5,0) [0|0] "Hour" Vector__XXX
 SG_ M10_Time_Cell2Balance : 16|16@1+ (0.5,0) [0|0] "Hour" Vector__XXX
 SG_ M10_Time_Cell1Balance : 0|16@1+ (0.5,0) [0|0] "Hour" Vector__XXX

BO_ 428 Lecu10MsgK: 8 Vector__XXX
 SG_ M10_Time_Cell10Balance : 16|16@1+ (0.5,0) [0|0] "Hour" Vector__XXX
 SG_ M10_Time_Cell11Balance : 32|16@1+ (0.5,0) [0|0] "Hour" Vector__XXX
 SG_ M10_Time_Cell12Balance : 48|16@1+ (0.5,0) [0|0] "Hour" Vector__XXX
 SG_ M10_Time_Cell9Balance : 0|16@1+ (0.5,0) [0|0] "Hour" Vector__XXX

BO_ 427 Lecu10MsgJ: 8 Vector__XXX
 SG_ M10_Time_Cell8Balance : 48|16@1+ (0.5,0) [0|0] "Hour" Vector__XXX
 SG_ M10_Time_Cell7Balance : 32|16@1+ (0.5,0) [0|0] "Hour" Vector__XXX
 SG_ M10_Time_Cell6Balance : 16|16@1+ (0.5,0) [0|0] "Hour" Vector__XXX
 SG_ M10_Time_Cell5Balance : 0|16@1+ (0.5,0) [0|0] "Hour" Vector__XXX

BO_ 412 Lecu9MsgK: 8 Vector__XXX
 SG_ M9_Time_Cell10Balance : 16|16@1+ (0.5,0) [0|0] "Hour" Vector__XXX
 SG_ M9_Time_Cell11Balance : 32|16@1+ (0.5,0) [0|0] "Hour" Vector__XXX
 SG_ M9_Time_Cell12Balance : 48|16@1+ (0.5,0) [0|0] "Hour" Vector__XXX
 SG_ M9_Time_Cell9Balance : 0|16@1+ (0.5,0) [0|0] "Hour" Vector__XXX

BO_ 411 Lecu9MsgJ: 8 Vector__XXX
 SG_ M9_Time_Cell8Balance : 48|16@1+ (0.5,0) [0|0] "Hour" Vector__XXX
 SG_ M9_Time_Cell7Balance : 32|16@1+ (0.5,0) [0|0] "Hour" Vector__XXX
 SG_ M9_Time_Cell6Balance : 16|16@1+ (0.5,0) [0|0] "Hour" Vector__XXX
 SG_ M9_Time_Cell5Balance : 0|16@1+ (0.5,0) [0|0] "Hour" Vector__XXX

BO_ 410 Lecu9MsgI: 8 Vector__XXX
 SG_ M9_Time_Cell4Balance : 48|16@1+ (0.5,0) [0|0] "Hour" Vector__XXX
 SG_ M9_Time_Cell3Balance : 32|16@1+ (0.5,0) [0|0] "Hour" Vector__XXX
 SG_ M9_Time_Cell2Balance : 16|16@1+ (0.5,0) [0|0] "Hour" Vector__XXX
 SG_ M9_Time_Cell1Balance : 0|16@1+ (0.5,0) [0|0] "Hour" Vector__XXX

BO_ 396 Lecu8MsgK: 8 Vector__XXX
 SG_ M8_Time_Cell10Balance : 16|16@1+ (0.5,0) [0|0] "Hour" Vector__XXX
 SG_ M8_Time_Cell11Balance : 32|16@1+ (0.5,0) [0|0] "Hour" Vector__XXX
 SG_ M8_Time_Cell12Balance : 48|16@1+ (0.5,0) [0|0] "Hour" Vector__XXX
 SG_ M8_Time_Cell9Balance : 0|16@1+ (0.5,0) [0|0] "Hour" Vector__XXX

BO_ 395 Lecu8MsgJ: 8 Vector__XXX
 SG_ M8_Time_Cell8Balance : 48|16@1+ (0.5,0) [0|0] "Hour" Vector__XXX
 SG_ M8_Time_Cell7Balance : 32|16@1+ (0.5,0) [0|0] "Hour" Vector__XXX
 SG_ M8_Time_Cell6Balance : 16|16@1+ (0.5,0) [0|0] "Hour" Vector__XXX
 SG_ M8_Time_Cell5Balance : 0|16@1+ (0.5,0) [0|0] "Hour" Vector__XXX

BO_ 394 Lecu8MsgI: 8 Vector__XXX
 SG_ M8_Time_Cell4Balance : 48|16@1+ (0.5,0) [0|0] "Hour" Vector__XXX
 SG_ M8_Time_Cell3Balance : 32|16@1+ (0.5,0) [0|0] "Hour" Vector__XXX
 SG_ M8_Time_Cell2Balance : 16|16@1+ (0.5,0) [0|0] "Hour" Vector__XXX
 SG_ M8_Time_Cell1Balance : 0|16@1+ (0.5,0) [0|0] "Hour" Vector__XXX

BO_ 380 Lecu7MsgK: 8 Vector__XXX
 SG_ M7_Time_Cell10Balance : 16|16@1+ (0.5,0) [0|0] "Hour" Vector__XXX
 SG_ M7_Time_Cell11Balance : 32|16@1+ (0.5,0) [0|0] "Hour" Vector__XXX
 SG_ M7_Time_Cell12Balance : 48|16@1+ (0.5,0) [0|0] "Hour" Vector__XXX
 SG_ M7_Time_Cell9Balance : 0|16@1+ (0.5,0) [0|0] "Hour" Vector__XXX

BO_ 379 Lecu7MsgJ: 8 Vector__XXX
 SG_ M7_Time_Cell8Balance : 48|16@1+ (0.5,0) [0|0] "Hour" Vector__XXX
 SG_ M7_Time_Cell7Balance : 32|16@1+ (0.5,0) [0|0] "Hour" Vector__XXX
 SG_ M7_Time_Cell6Balance : 16|16@1+ (0.5,0) [0|0] "Hour" Vector__XXX
 SG_ M7_Time_Cell5Balance : 0|16@1+ (0.5,0) [0|0] "Hour" Vector__XXX

BO_ 378 Lecu7MsgI: 8 Vector__XXX
 SG_ M7_Time_Cell4Balance : 48|16@1+ (0.5,0) [0|0] "Hour" Vector__XXX
 SG_ M7_Time_Cell3Balance : 32|16@1+ (0.5,0) [0|0] "Hour" Vector__XXX
 SG_ M7_Time_Cell2Balance : 16|16@1+ (0.5,0) [0|0] "Hour" Vector__XXX
 SG_ M7_Time_Cell1Balance : 0|16@1+ (0.5,0) [0|0] "Hour" Vector__XXX

BO_ 364 Lecu6MsgK: 8 Vector__XXX
 SG_ M6_Time_Cell10Balance : 16|16@1+ (0.5,0) [0|0] "Hour" Vector__XXX
 SG_ M6_Time_Cell11Balance : 32|16@1+ (0.5,0) [0|0] "Hour" Vector__XXX
 SG_ M6_Time_Cell12Balance : 48|16@1+ (0.5,0) [0|0] "Hour" Vector__XXX
 SG_ M6_Time_Cell9Balance : 0|16@1+ (0.5,0) [0|0] "Hour" Vector__XXX

BO_ 363 Lecu6MsgJ: 8 Vector__XXX
 SG_ M6_Time_Cell8Balance : 48|16@1+ (0.5,0) [0|0] "Hour" Vector__XXX
 SG_ M6_Time_Cell7Balance : 32|16@1+ (0.5,0) [0|0] "Hour" Vector__XXX
 SG_ M6_Time_Cell6Balance : 16|16@1+ (0.5,0) [0|0] "Hour" Vector__XXX
 SG_ M6_Time_Cell5Balance : 0|16@1+ (0.5,0) [0|0] "Hour" Vector__XXX

BO_ 362 Lecu6MsgI: 8 Vector__XXX
 SG_ M6_Time_Cell4Balance : 48|16@1+ (0.5,0) [0|0] "Hour" Vector__XXX
 SG_ M6_Time_Cell3Balance : 32|16@1+ (0.5,0) [0|0] "Hour" Vector__XXX
 SG_ M6_Time_Cell2Balance : 16|16@1+ (0.5,0) [0|0] "Hour" Vector__XXX
 SG_ M6_Time_Cell1Balance : 0|16@1+ (0.5,0) [0|0] "Hour" Vector__XXX

BO_ 348 Lecu5MsgK: 8 Vector__XXX
 SG_ M5_Time_Cell10Balance : 16|16@1+ (0.5,0) [0|0] "Hour" Vector__XXX
 SG_ M5_Time_Cell11Balance : 32|16@1+ (0.5,0) [0|0] "Hour" Vector__XXX
 SG_ M5_Time_Cell12Balance : 48|16@1+ (0.5,0) [0|0] "Hour" Vector__XXX
 SG_ M5_Time_Cell9Balance : 0|16@1+ (0.5,0) [0|0] "Hour" Vector__XXX

BO_ 347 Lecu5MsgJ: 8 Vector__XXX
 SG_ M5_Time_Cell8Balance : 48|16@1+ (0.5,0) [0|0] "Hour" Vector__XXX
 SG_ M5_Time_Cell7Balance : 32|16@1+ (0.5,0) [0|0] "Hour" Vector__XXX
 SG_ M5_Time_Cell6Balance : 16|16@1+ (0.5,0) [0|0] "Hour" Vector__XXX
 SG_ M5_Time_Cell5Balance : 0|16@1+ (0.5,0) [0|0] "Hour" Vector__XXX

BO_ 346 Lecu5MsgI: 8 Vector__XXX
 SG_ M5_Time_Cell4Balance : 48|16@1+ (0.5,0) [0|0] "Hour" Vector__XXX
 SG_ M5_Time_Cell3Balance : 32|16@1+ (0.5,0) [0|0] "Hour" Vector__XXX
 SG_ M5_Time_Cell2Balance : 16|16@1+ (0.5,0) [0|0] "Hour" Vector__XXX
 SG_ M5_Time_Cell1Balance : 0|16@1+ (0.5,0) [0|0] "Hour" Vector__XXX

BO_ 332 Lecu4MsgK: 8 Vector__XXX
 SG_ M4_Time_Cell10Balance : 16|16@1+ (0.5,0) [0|0] "Hour" Vector__XXX
 SG_ M4_Time_Cell11Balance : 32|16@1+ (0.5,0) [0|0] "Hour" Vector__XXX
 SG_ M4_Time_Cell12Balance : 48|16@1+ (0.5,0) [0|0] "Hour" Vector__XXX
 SG_ M4_Time_Cell9Balance : 0|16@1+ (0.5,0) [0|0] "Hour" Vector__XXX

BO_ 331 Lecu4MsgJ: 8 Vector__XXX
 SG_ M4_Time_Cell8Balance : 48|16@1+ (0.5,0) [0|0] "Hour" Vector__XXX
 SG_ M4_Time_Cell7Balance : 32|16@1+ (0.5,0) [0|0] "Hour" Vector__XXX
 SG_ M4_Time_Cell6Balance : 16|16@1+ (0.5,0) [0|0] "Hour" Vector__XXX
 SG_ M4_Time_Cell5Balance : 0|16@1+ (0.5,0) [0|0] "Hour" Vector__XXX

BO_ 330 Lecu4MsgI: 8 Vector__XXX
 SG_ M4_Time_Cell4Balance : 48|16@1+ (0.5,0) [0|0] "Hour" Vector__XXX
 SG_ M4_Time_Cell3Balance : 32|16@1+ (0.5,0) [0|0] "Hour" Vector__XXX
 SG_ M4_Time_Cell2Balance : 16|16@1+ (0.5,0) [0|0] "Hour" Vector__XXX
 SG_ M4_Time_Cell1Balance : 0|16@1+ (0.5,0) [0|0] "Hour" Vector__XXX

BO_ 316 Lecu3MsgK: 8 Vector__XXX
 SG_ M3_Time_Cell10Balance : 16|16@1+ (0.5,0) [0|0] "Hour" Vector__XXX
 SG_ M3_Time_Cell11Balance : 32|16@1+ (0.5,0) [0|0] "Hour" Vector__XXX
 SG_ M3_Time_Cell12Balance : 48|16@1+ (0.5,0) [0|0] "Hour" Vector__XXX
 SG_ M3_Time_Cell9Balance : 0|16@1+ (0.5,0) [0|0] "Hour" Vector__XXX

BO_ 315 Lecu3MsgJ: 8 Vector__XXX
 SG_ M3_Time_Cell8Balance : 48|16@1+ (0.5,0) [0|0] "Hour" Vector__XXX
 SG_ M3_Time_Cell7Balance : 32|16@1+ (0.5,0) [0|0] "Hour" Vector__XXX
 SG_ M3_Time_Cell6Balance : 16|16@1+ (0.5,0) [0|0] "Hour" Vector__XXX
 SG_ M3_Time_Cell5Balance : 0|16@1+ (0.5,0) [0|0] "Hour" Vector__XXX

BO_ 314 Lecu3MsgI: 8 Vector__XXX
 SG_ M3_Time_Cell4Balance : 48|16@1+ (0.5,0) [0|0] "Hour" Vector__XXX
 SG_ M3_Time_Cell3Balance : 32|16@1+ (0.5,0) [0|0] "Hour" Vector__XXX
 SG_ M3_Time_Cell2Balance : 16|16@1+ (0.5,0) [0|0] "Hour" Vector__XXX
 SG_ M3_Time_Cell1Balance : 0|16@1+ (0.5,0) [0|0] "Hour" Vector__XXX

BO_ 700 Lecu27MsgK: 8 Vector__XXX
 SG_ M27_Time_Cell10Balance : 16|16@1+ (0.5,0) [0|0] "Hour" Vector__XXX
 SG_ M27_Time_Cell11Balance : 32|16@1+ (0.5,0) [0|0] "Hour" Vector__XXX
 SG_ M27_Time_Cell12Balance : 48|16@1+ (0.5,0) [0|0] "Hour" Vector__XXX
 SG_ M27_Time_Cell9Balance : 0|16@1+ (0.5,0) [0|0] "Hour" Vector__XXX

BO_ 699 Lecu27MsgJ: 8 Vector__XXX
 SG_ M27_Time_Cell8Balance : 48|16@1+ (0.5,0) [0|0] "Hour" Vector__XXX
 SG_ M27_Time_Cell7Balance : 32|16@1+ (0.5,0) [0|0] "Hour" Vector__XXX
 SG_ M27_Time_Cell6Balance : 16|16@1+ (0.5,0) [0|0] "Hour" Vector__XXX
 SG_ M27_Time_Cell5Balance : 0|16@1+ (0.5,0) [0|0] "Hour" Vector__XXX

BO_ 634 Lecu23MsgI: 8 Vector__XXX
 SG_ M23_Time_Cell4Balance : 48|16@1+ (0.5,0) [0|0] "Hour" Vector__XXX
 SG_ M23_Time_Cell3Balance : 32|16@1+ (0.5,0) [0|0] "Hour" Vector__XXX
 SG_ M23_Time_Cell2Balance : 16|16@1+ (0.5,0) [0|0] "Hour" Vector__XXX
 SG_ M23_Time_Cell1Balance : 0|16@1+ (0.5,0) [0|0] "Hour" Vector__XXX

BO_ 716 Lecu28MsgK: 8 Vector__XXX
 SG_ M28_Time_Cell10Balance : 16|16@1+ (0.5,0) [0|0] "Hour" Vector__XXX
 SG_ M28_Time_Cell11Balance : 32|16@1+ (0.5,0) [0|0] "Hour" Vector__XXX
 SG_ M28_Time_Cell12Balance : 48|16@1+ (0.5,0) [0|0] "Hour" Vector__XXX
 SG_ M28_Time_Cell9Balance : 0|16@1+ (0.5,0) [0|0] "Hour" Vector__XXX

BO_ 715 Lecu28MsgJ: 8 Vector__XXX
 SG_ M28_Time_Cell8Balance : 48|16@1+ (0.5,0) [0|0] "Hour" Vector__XXX
 SG_ M28_Time_Cell7Balance : 32|16@1+ (0.5,0) [0|0] "Hour" Vector__XXX
 SG_ M28_Time_Cell6Balance : 16|16@1+ (0.5,0) [0|0] "Hour" Vector__XXX
 SG_ M28_Time_Cell5Balance : 0|16@1+ (0.5,0) [0|0] "Hour" Vector__XXX

BO_ 650 Lecu24MsgI: 8 Vector__XXX
 SG_ M24_Time_Cell4Balance : 48|16@1+ (0.5,0) [0|0] "Hour" Vector__XXX
 SG_ M24_Time_Cell3Balance : 32|16@1+ (0.5,0) [0|0] "Hour" Vector__XXX
 SG_ M24_Time_Cell2Balance : 16|16@1+ (0.5,0) [0|0] "Hour" Vector__XXX
 SG_ M24_Time_Cell1Balance : 0|16@1+ (0.5,0) [0|0] "Hour" Vector__XXX

BO_ 732 Lecu29MsgK: 8 Vector__XXX
 SG_ M29_Time_Cell10Balance : 16|16@1+ (0.5,0) [0|0] "Hour" Vector__XXX
 SG_ M29_Time_Cell11Balance : 32|16@1+ (0.5,0) [0|0] "Hour" Vector__XXX
 SG_ M29_Time_Cell12Balance : 48|16@1+ (0.5,0) [0|0] "Hour" Vector__XXX
 SG_ M29_Time_Cell9Balance : 0|16@1+ (0.5,0) [0|0] "Hour" Vector__XXX

BO_ 731 Lecu29MsgJ: 8 Vector__XXX
 SG_ M29_Time_Cell8Balance : 48|16@1+ (0.5,0) [0|0] "Hour" Vector__XXX
 SG_ M29_Time_Cell7Balance : 32|16@1+ (0.5,0) [0|0] "Hour" Vector__XXX
 SG_ M29_Time_Cell6Balance : 16|16@1+ (0.5,0) [0|0] "Hour" Vector__XXX
 SG_ M29_Time_Cell5Balance : 0|16@1+ (0.5,0) [0|0] "Hour" Vector__XXX

BO_ 666 Lecu25MsgI: 8 Vector__XXX
 SG_ M25_Time_Cell4Balance : 48|16@1+ (0.5,0) [0|0] "Hour" Vector__XXX
 SG_ M25_Time_Cell3Balance : 32|16@1+ (0.5,0) [0|0] "Hour" Vector__XXX
 SG_ M25_Time_Cell2Balance : 16|16@1+ (0.5,0) [0|0] "Hour" Vector__XXX
 SG_ M25_Time_Cell1Balance : 0|16@1+ (0.5,0) [0|0] "Hour" Vector__XXX

BO_ 748 Lecu30MsgK: 8 Vector__XXX
 SG_ M30_Time_Cell10Balance : 16|16@1+ (0.5,0) [0|0] "Hour" Vector__XXX
 SG_ M30_Time_Cell11Balance : 32|16@1+ (0.5,0) [0|0] "Hour" Vector__XXX
 SG_ M30_Time_Cell12Balance : 48|16@1+ (0.5,0) [0|0] "Hour" Vector__XXX
 SG_ M30_Time_Cell9Balance : 0|16@1+ (0.5,0) [0|0] "Hour" Vector__XXX

BO_ 747 Lecu30MsgJ: 8 Vector__XXX
 SG_ M30_Time_Cell8Balance : 48|16@1+ (0.5,0) [0|0] "Hour" Vector__XXX
 SG_ M30_Time_Cell7Balance : 32|16@1+ (0.5,0) [0|0] "Hour" Vector__XXX
 SG_ M30_Time_Cell6Balance : 16|16@1+ (0.5,0) [0|0] "Hour" Vector__XXX
 SG_ M30_Time_Cell5Balance : 0|16@1+ (0.5,0) [0|0] "Hour" Vector__XXX

BO_ 682 Lecu26MsgI: 8 Vector__XXX
 SG_ M26_Time_Cell4Balance : 48|16@1+ (0.5,0) [0|0] "Hour" Vector__XXX
 SG_ M26_Time_Cell3Balance : 32|16@1+ (0.5,0) [0|0] "Hour" Vector__XXX
 SG_ M26_Time_Cell2Balance : 16|16@1+ (0.5,0) [0|0] "Hour" Vector__XXX
 SG_ M26_Time_Cell1Balance : 0|16@1+ (0.5,0) [0|0] "Hour" Vector__XXX

BO_ 764 Lecu31MsgK: 8 Vector__XXX
 SG_ M31_Time_Cell10Balance : 16|16@1+ (0.5,0) [0|0] "Hour" Vector__XXX
 SG_ M31_Time_Cell11Balance : 32|16@1+ (0.5,0) [0|0] "Hour" Vector__XXX
 SG_ M31_Time_Cell12Balance : 48|16@1+ (0.5,0) [0|0] "Hour" Vector__XXX
 SG_ M31_Time_Cell9Balance : 0|16@1+ (0.5,0) [0|0] "Hour" Vector__XXX

BO_ 763 Lecu31MsgJ: 8 Vector__XXX
 SG_ M31_Time_Cell8Balance : 48|16@1+ (0.5,0) [0|0] "Hour" Vector__XXX
 SG_ M31_Time_Cell7Balance : 32|16@1+ (0.5,0) [0|0] "Hour" Vector__XXX
 SG_ M31_Time_Cell6Balance : 16|16@1+ (0.5,0) [0|0] "Hour" Vector__XXX
 SG_ M31_Time_Cell5Balance : 0|16@1+ (0.5,0) [0|0] "Hour" Vector__XXX

BO_ 698 Lecu27MsgI: 8 Vector__XXX
 SG_ M27_Time_Cell4Balance : 48|16@1+ (0.5,0) [0|0] "Hour" Vector__XXX
 SG_ M27_Time_Cell3Balance : 32|16@1+ (0.5,0) [0|0] "Hour" Vector__XXX
 SG_ M27_Time_Cell2Balance : 16|16@1+ (0.5,0) [0|0] "Hour" Vector__XXX
 SG_ M27_Time_Cell1Balance : 0|16@1+ (0.5,0) [0|0] "Hour" Vector__XXX

BO_ 780 Lecu32MsgK: 8 Vector__XXX
 SG_ M32_Time_Cell10Balance : 16|16@1+ (0.5,0) [0|0] "Hour" Vector__XXX
 SG_ M32_Time_Cell11Balance : 32|16@1+ (0.5,0) [0|0] "Hour" Vector__XXX
 SG_ M32_Time_Cell12Balance : 48|16@1+ (0.5,0) [0|0] "Hour" Vector__XXX
 SG_ M32_Time_Cell9Balance : 0|16@1+ (0.5,0) [0|0] "Hour" Vector__XXX

BO_ 779 Lecu32MsgJ: 8 Vector__XXX
 SG_ M32_Time_Cell8Balance : 48|16@1+ (0.5,0) [0|0] "Hour" Vector__XXX
 SG_ M32_Time_Cell7Balance : 32|16@1+ (0.5,0) [0|0] "Hour" Vector__XXX
 SG_ M32_Time_Cell6Balance : 16|16@1+ (0.5,0) [0|0] "Hour" Vector__XXX
 SG_ M32_Time_Cell5Balance : 0|16@1+ (0.5,0) [0|0] "Hour" Vector__XXX

BO_ 714 Lecu28MsgI: 8 Vector__XXX
 SG_ M28_Time_Cell4Balance : 48|16@1+ (0.5,0) [0|0] "Hour" Vector__XXX
 SG_ M28_Time_Cell3Balance : 32|16@1+ (0.5,0) [0|0] "Hour" Vector__XXX
 SG_ M28_Time_Cell2Balance : 16|16@1+ (0.5,0) [0|0] "Hour" Vector__XXX
 SG_ M28_Time_Cell1Balance : 0|16@1+ (0.5,0) [0|0] "Hour" Vector__XXX

BO_ 652 Lecu24MsgK: 8 Vector__XXX
 SG_ M24_Time_Cell10Balance : 16|16@1+ (0.5,0) [0|0] "Hour" Vector__XXX
 SG_ M24_Time_Cell11Balance : 32|16@1+ (0.5,0) [0|0] "Hour" Vector__XXX
 SG_ M24_Time_Cell12Balance : 48|16@1+ (0.5,0) [0|0] "Hour" Vector__XXX
 SG_ M24_Time_Cell9Balance : 0|16@1+ (0.5,0) [0|0] "Hour" Vector__XXX

BO_ 651 Lecu24MsgJ: 8 Vector__XXX
 SG_ M24_Time_Cell8Balance : 48|16@1+ (0.5,0) [0|0] "Hour" Vector__XXX
 SG_ M24_Time_Cell7Balance : 32|16@1+ (0.5,0) [0|0] "Hour" Vector__XXX
 SG_ M24_Time_Cell6Balance : 16|16@1+ (0.5,0) [0|0] "Hour" Vector__XXX
 SG_ M24_Time_Cell5Balance : 0|16@1+ (0.5,0) [0|0] "Hour" Vector__XXX

BO_ 762 Lecu31MsgI: 8 Vector__XXX
 SG_ M31_Time_Cell4Balance : 48|16@1+ (0.5,0) [0|0] "Hour" Vector__XXX
 SG_ M31_Time_Cell3Balance : 32|16@1+ (0.5,0) [0|0] "Hour" Vector__XXX
 SG_ M31_Time_Cell2Balance : 16|16@1+ (0.5,0) [0|0] "Hour" Vector__XXX
 SG_ M31_Time_Cell1Balance : 0|16@1+ (0.5,0) [0|0] "Hour" Vector__XXX

BO_ 476 Lecu13MsgK: 8 Vector__XXX
 SG_ M13_Time_Cell10Balance : 16|16@1+ (0.5,0) [0|0] "Hour" Vector__XXX
 SG_ M13_Time_Cell11Balance : 32|16@1+ (0.5,0) [0|0] "Hour" Vector__XXX
 SG_ M13_Time_Cell12Balance : 48|16@1+ (0.5,0) [0|0] "Hour" Vector__XXX
 SG_ M13_Time_Cell9Balance : 0|16@1+ (0.5,0) [0|0] "Hour" Vector__XXX

BO_ 475 Lecu13MsgJ: 8 Vector__XXX
 SG_ M13_Time_Cell8Balance : 48|16@1+ (0.5,0) [0|0] "Hour" Vector__XXX
 SG_ M13_Time_Cell7Balance : 32|16@1+ (0.5,0) [0|0] "Hour" Vector__XXX
 SG_ M13_Time_Cell6Balance : 16|16@1+ (0.5,0) [0|0] "Hour" Vector__XXX
 SG_ M13_Time_Cell5Balance : 0|16@1+ (0.5,0) [0|0] "Hour" Vector__XXX

BO_ 458 Lecu12MsgI: 8 Vector__XXX
 SG_ M12_Time_Cell4Balance : 48|16@1+ (0.5,0) [0|0] "Hour" Vector__XXX
 SG_ M12_Time_Cell3Balance : 32|16@1+ (0.5,0) [0|0] "Hour" Vector__XXX
 SG_ M12_Time_Cell2Balance : 16|16@1+ (0.5,0) [0|0] "Hour" Vector__XXX
 SG_ M12_Time_Cell1Balance : 0|16@1+ (0.5,0) [0|0] "Hour" Vector__XXX

BO_ 300 Lecu2MsgK: 8 Vector__XXX
 SG_ M2_Time_Cell10Balance : 16|16@1+ (0.5,0) [0|0] "Hour" Vector__XXX
 SG_ M2_Time_Cell11Balance : 32|16@1+ (0.5,0) [0|0] "Hour" Vector__XXX
 SG_ M2_Time_Cell12Balance : 48|16@1+ (0.5,0) [0|0] "Hour" Vector__XXX
 SG_ M2_Time_Cell9Balance : 0|16@1+ (0.5,0) [0|0] "Hour" Vector__XXX

BO_ 299 Lecu2MsgJ: 8 Vector__XXX
 SG_ M2_Time_Cell8Balance : 48|16@1+ (0.5,0) [0|0] "Hour" Vector__XXX
 SG_ M2_Time_Cell7Balance : 32|16@1+ (0.5,0) [0|0] "Hour" Vector__XXX
 SG_ M2_Time_Cell6Balance : 16|16@1+ (0.5,0) [0|0] "Hour" Vector__XXX
 SG_ M2_Time_Cell5Balance : 0|16@1+ (0.5,0) [0|0] "Hour" Vector__XXX

BO_ 298 Lecu2MsgI: 8 Vector__XXX
 SG_ M2_Time_Cell4Balance : 48|16@1+ (0.5,0) [0|0] "Hour" Vector__XXX
 SG_ M2_Time_Cell3Balance : 32|16@1+ (0.5,0) [0|0] "Hour" Vector__XXX
 SG_ M2_Time_Cell2Balance : 16|16@1+ (0.5,0) [0|0] "Hour" Vector__XXX
 SG_ M2_Time_Cell1Balance : 0|16@1+ (0.5,0) [0|0] "Hour" Vector__XXX

BO_ 770 Lecu32MsgB: 8 Vector__XXX
 SG_ M32_Heating_OverTemp_Flag : 27|1@1+ (1,0) [0|0] ""  BMU
 SG_ M32_TempFault : 29|1@1+ (1,0) [0|0] ""  BMU
 SG_ M32_BatteryLost_Error : 28|1@1+ (1,0) [0|0] ""  BMU
 SG_ M32_JumperTemp_Max m1 : 48|11@1+ (0.1,-40) [0|0] "℃"  BMU
 SG_ M32_BalanceTemp_Max m0 : 48|11@1+ (0.1,-40) [0|0] "℃"  BMU
 SG_ M32_BalanceFailure : 30|1@1+ (1,0) [0|0] ""  BMU
 SG_ M32_Tem_Min_Num : 40|3@1+ (1,0) [0|0] ""  BMU
 SG_ M32_Tem_Max_Num : 32|3@1+ (1,0) [0|0] ""  BMU
 SG_ M32_CellVoltageMin_Num : 43|5@1+ (1,0) [0|31] ""  BMU
 SG_ M32_CellVoltageMax_Num : 35|5@1+ (1,0) [0|31] ""  BMU
 SG_ M32_JumperTemp_Max_Valid m1 : 63|1@1+ (1,0) [0|0] ""  BMU
 SG_ M32_BalanceTemp_Max_Valid m0 : 63|1@1+ (1,0) [0|0] ""  BMU
 SG_ M32_Temp_Choice M : 59|4@1+ (1,0) [0|0] ""  BMU
 SG_ M32_Tem_Mean_Valid : 31|1@1+ (1,0) [0|0] ""  BMU
 SG_ M32_CellVoltageMean_Valid : 15|1@1+ (1,0) [0|0] ""  BMU
 SG_ M32_Tem_Mean : 16|11@1+ (0.1,-40) [0|0] "℃"  BMU
 SG_ M32_CellVoltageMean : 0|15@1- (0.001,0) [0|0] "V"  BMU

BO_ 754 Lecu31MsgB: 8 Vector__XXX
 SG_ M31_Heating_OverTemp_Flag : 27|1@1+ (1,0) [0|0] ""  BMU
 SG_ M31_TempFault : 29|1@1+ (1,0) [0|0] ""  BMU
 SG_ M31_BatteryLost_Error : 28|1@1+ (1,0) [0|0] ""  BMU
 SG_ M31_JumperTemp_Max m1 : 48|11@1+ (0.1,-40) [0|0] "℃"  BMU
 SG_ M31_BalanceTemp_Max m0 : 48|11@1+ (0.1,-40) [0|0] "℃"  BMU
 SG_ M31_BalanceFailure : 30|1@1+ (1,0) [0|0] ""  BMU
 SG_ M31_Tem_Min_Num : 40|3@1+ (1,0) [0|0] ""  BMU
 SG_ M31_Tem_Max_Num : 32|3@1+ (1,0) [0|0] ""  BMU
 SG_ M31_CellVoltageMin_Num : 43|5@1+ (1,0) [0|31] ""  BMU
 SG_ M31_CellVoltageMax_Num : 35|5@1+ (1,0) [0|31] ""  BMU
 SG_ M31_JumperTemp_Max_Valid m1 : 63|1@1+ (1,0) [0|0] ""  BMU
 SG_ M31_BalanceTemp_Max_Valid m0 : 63|1@1+ (1,0) [0|0] ""  BMU
 SG_ M31_Temp_Choice M : 59|4@1+ (1,0) [0|0] ""  BMU
 SG_ M31_Tem_Mean_Valid : 31|1@1+ (1,0) [0|0] ""  BMU
 SG_ M31_CellVoltageMean_Valid : 15|1@1+ (1,0) [0|0] ""  BMU
 SG_ M31_Tem_Mean : 16|11@1+ (0.1,-40) [0|0] "℃"  BMU
 SG_ M31_CellVoltageMean : 0|15@1- (0.001,0) [0|0] "V"  BMU

BO_ 738 Lecu30MsgB: 8 Vector__XXX
 SG_ M30_Heating_OverTemp_Flag : 27|1@1+ (1,0) [0|0] ""  BMU
 SG_ M30_TempFault : 29|1@1+ (1,0) [0|0] ""  BMU
 SG_ M30_BatteryLost_Error : 28|1@1+ (1,0) [0|0] ""  BMU
 SG_ M30_JumperTemp_Max m1 : 48|11@1+ (0.1,-40) [0|0] "℃"  BMU
 SG_ M30_BalanceTemp_Max m0 : 48|11@1+ (0.1,-40) [0|0] "℃"  BMU
 SG_ M30_BalanceFailure : 30|1@1+ (1,0) [0|0] ""  BMU
 SG_ M30_Tem_Min_Num : 40|3@1+ (1,0) [0|0] ""  BMU
 SG_ M30_Tem_Max_Num : 32|3@1+ (1,0) [0|0] ""  BMU
 SG_ M30_CellVoltageMin_Num : 43|5@1+ (1,0) [0|31] ""  BMU
 SG_ M30_CellVoltageMax_Num : 35|5@1+ (1,0) [0|31] ""  BMU
 SG_ M30_JumperTemp_Max_Valid m1 : 63|1@1+ (1,0) [0|0] ""  BMU
 SG_ M30_BalanceTemp_Max_Valid m0 : 63|1@1+ (1,0) [0|0] ""  BMU
 SG_ M30_Temp_Choice M : 59|4@1+ (1,0) [0|0] ""  BMU
 SG_ M30_Tem_Mean_Valid : 31|1@1+ (1,0) [0|0] ""  BMU
 SG_ M30_CellVoltageMean_Valid : 15|1@1+ (1,0) [0|0] ""  BMU
 SG_ M30_Tem_Mean : 16|11@1+ (0.1,-40) [0|0] "℃"  BMU
 SG_ M30_CellVoltageMean : 0|15@1- (0.001,0) [0|0] "V"  BMU

BO_ 722 Lecu29MsgB: 8 Vector__XXX
 SG_ M29_Heating_OverTemp_Flag : 27|1@1+ (1,0) [0|0] ""  BMU
 SG_ M29_TempFault : 29|1@1+ (1,0) [0|0] ""  BMU
 SG_ M29_BatteryLost_Error : 28|1@1+ (1,0) [0|0] ""  BMU
 SG_ M29_JumperTemp_Max m1 : 48|11@1+ (0.1,-40) [0|0] "℃"  BMU
 SG_ M29_BalanceTemp_Max m0 : 48|11@1+ (0.1,-40) [0|0] "℃"  BMU
 SG_ M29_BalanceFailure : 30|1@1+ (1,0) [0|0] ""  BMU
 SG_ M29_Tem_Min_Num : 40|3@1+ (1,0) [0|0] ""  BMU
 SG_ M29_Tem_Max_Num : 32|3@1+ (1,0) [0|0] ""  BMU
 SG_ M29_CellVoltageMin_Num : 43|5@1+ (1,0) [0|31] ""  BMU
 SG_ M29_CellVoltageMax_Num : 35|5@1+ (1,0) [0|31] ""  BMU
 SG_ M29_JumperTemp_Max_Valid m1 : 63|1@1+ (1,0) [0|0] ""  BMU
 SG_ M29_BalanceTemp_Max_Valid m0 : 63|1@1+ (1,0) [0|0] ""  BMU
 SG_ M29_Temp_Choice M : 59|4@1+ (1,0) [0|0] ""  BMU
 SG_ M29_Tem_Mean_Valid : 31|1@1+ (1,0) [0|0] ""  BMU
 SG_ M29_CellVoltageMean_Valid : 15|1@1+ (1,0) [0|0] ""  BMU
 SG_ M29_Tem_Mean : 16|11@1+ (0.1,-40) [0|0] "℃"  BMU
 SG_ M29_CellVoltageMean : 0|15@1- (0.001,0) [0|0] "V"  BMU

BO_ 706 Lecu28MsgB: 8 Vector__XXX
 SG_ M28_Heating_OverTemp_Flag : 27|1@1+ (1,0) [0|0] ""  BMU
 SG_ M28_TempFault : 29|1@1+ (1,0) [0|0] ""  BMU
 SG_ M28_BatteryLost_Error : 28|1@1+ (1,0) [0|0] ""  BMU
 SG_ M28_JumperTemp_Max m1 : 48|11@1+ (0.1,-40) [0|0] "℃"  BMU
 SG_ M28_BalanceTemp_Max m0 : 48|11@1+ (0.1,-40) [0|0] "℃"  BMU
 SG_ M28_BalanceFailure : 30|1@1+ (1,0) [0|0] ""  BMU
 SG_ M28_Tem_Min_Num : 40|3@1+ (1,0) [0|0] ""  BMU
 SG_ M28_Tem_Max_Num : 32|3@1+ (1,0) [0|0] ""  BMU
 SG_ M28_CellVoltageMin_Num : 43|5@1+ (1,0) [0|31] ""  BMU
 SG_ M28_CellVoltageMax_Num : 35|5@1+ (1,0) [0|31] ""  BMU
 SG_ M28_JumperTemp_Max_Valid m1 : 63|1@1+ (1,0) [0|0] ""  BMU
 SG_ M28_BalanceTemp_Max_Valid m0 : 63|1@1+ (1,0) [0|0] ""  BMU
 SG_ M28_Temp_Choice M : 59|4@1+ (1,0) [0|0] ""  BMU
 SG_ M28_Tem_Mean_Valid : 31|1@1+ (1,0) [0|0] ""  BMU
 SG_ M28_CellVoltageMean_Valid : 15|1@1+ (1,0) [0|0] ""  BMU
 SG_ M28_Tem_Mean : 16|11@1+ (0.1,-40) [0|0] "℃"  BMU
 SG_ M28_CellVoltageMean : 0|15@1- (0.001,0) [0|0] "V"  BMU

BO_ 690 Lecu27MsgB: 8 Vector__XXX
 SG_ M27_Heating_OverTemp_Flag : 27|1@1+ (1,0) [0|0] ""  BMU
 SG_ M27_TempFault : 29|1@1+ (1,0) [0|0] ""  BMU
 SG_ M27_BatteryLost_Error : 28|1@1+ (1,0) [0|0] ""  BMU
 SG_ M27_JumperTemp_Max m1 : 48|11@1+ (0.1,-40) [0|0] "℃"  BMU
 SG_ M27_BalanceTemp_Max m0 : 48|11@1+ (0.1,-40) [0|0] "℃"  BMU
 SG_ M27_BalanceFailure : 30|1@1+ (1,0) [0|0] ""  BMU
 SG_ M27_Tem_Min_Num : 40|3@1+ (1,0) [0|0] ""  BMU
 SG_ M27_Tem_Max_Num : 32|3@1+ (1,0) [0|0] ""  BMU
 SG_ M27_CellVoltageMin_Num : 43|5@1+ (1,0) [0|31] ""  BMU
 SG_ M27_CellVoltageMax_Num : 35|5@1+ (1,0) [0|31] ""  BMU
 SG_ M27_JumperTemp_Max_Valid m1 : 63|1@1+ (1,0) [0|0] ""  BMU
 SG_ M27_BalanceTemp_Max_Valid m0 : 63|1@1+ (1,0) [0|0] ""  BMU
 SG_ M27_Temp_Choice M : 59|4@1+ (1,0) [0|0] ""  BMU
 SG_ M27_Tem_Mean_Valid : 31|1@1+ (1,0) [0|0] ""  BMU
 SG_ M27_CellVoltageMean_Valid : 15|1@1+ (1,0) [0|0] ""  BMU
 SG_ M27_Tem_Mean : 16|11@1+ (0.1,-40) [0|0] "℃"  BMU
 SG_ M27_CellVoltageMean : 0|15@1- (0.001,0) [0|0] "V"  BMU

BO_ 674 Lecu26MsgB: 8 Vector__XXX
 SG_ M26_Heating_OverTemp_Flag : 27|1@1+ (1,0) [0|0] ""  BMU
 SG_ M26_TempFault : 29|1@1+ (1,0) [0|0] ""  BMU
 SG_ M26_BatteryLost_Error : 28|1@1+ (1,0) [0|0] ""  BMU
 SG_ M26_JumperTemp_Max m1 : 48|11@1+ (0.1,-40) [0|0] "℃"  BMU
 SG_ M26_BalanceTemp_Max m0 : 48|11@1+ (0.1,-40) [0|0] "℃"  BMU
 SG_ M26_BalanceFailure : 30|1@1+ (1,0) [0|0] ""  BMU
 SG_ M26_Tem_Min_Num : 40|3@1+ (1,0) [0|0] ""  BMU
 SG_ M26_Tem_Max_Num : 32|3@1+ (1,0) [0|0] ""  BMU
 SG_ M26_CellVoltageMin_Num : 43|5@1+ (1,0) [0|31] ""  BMU
 SG_ M26_CellVoltageMax_Num : 35|5@1+ (1,0) [0|31] ""  BMU
 SG_ M26_JumperTemp_Max_Valid m1 : 63|1@1+ (1,0) [0|0] ""  BMU
 SG_ M26_BalanceTemp_Max_Valid m0 : 63|1@1+ (1,0) [0|0] ""  BMU
 SG_ M26_Temp_Choice M : 59|4@1+ (1,0) [0|0] ""  BMU
 SG_ M26_Tem_Mean_Valid : 31|1@1+ (1,0) [0|0] ""  BMU
 SG_ M26_CellVoltageMean_Valid : 15|1@1+ (1,0) [0|0] ""  BMU
 SG_ M26_Tem_Mean : 16|11@1+ (0.1,-40) [0|0] "℃"  BMU
 SG_ M26_CellVoltageMean : 0|15@1- (0.001,0) [0|0] "V"  BMU

BO_ 658 Lecu25MsgB: 8 Vector__XXX
 SG_ M25_Heating_OverTemp_Flag : 27|1@1+ (1,0) [0|0] ""  BMU
 SG_ M25_TempFault : 29|1@1+ (1,0) [0|0] ""  BMU
 SG_ M25_BatteryLost_Error : 28|1@1+ (1,0) [0|0] ""  BMU
 SG_ M25_JumperTemp_Max m1 : 48|11@1+ (0.1,-40) [0|0] "℃"  BMU
 SG_ M25_BalanceTemp_Max m0 : 48|11@1+ (0.1,-40) [0|0] "℃"  BMU
 SG_ M25_BalanceFailure : 30|1@1+ (1,0) [0|0] ""  BMU
 SG_ M25_Tem_Min_Num : 40|3@1+ (1,0) [0|0] ""  BMU
 SG_ M25_Tem_Max_Num : 32|3@1+ (1,0) [0|0] ""  BMU
 SG_ M25_CellVoltageMin_Num : 43|5@1+ (1,0) [0|31] ""  BMU
 SG_ M25_CellVoltageMax_Num : 35|5@1+ (1,0) [0|31] ""  BMU
 SG_ M25_JumperTemp_Max_Valid m1 : 63|1@1+ (1,0) [0|0] ""  BMU
 SG_ M25_BalanceTemp_Max_Valid m0 : 63|1@1+ (1,0) [0|0] ""  BMU
 SG_ M25_Temp_Choice M : 59|4@1+ (1,0) [0|0] ""  BMU
 SG_ M25_Tem_Mean_Valid : 31|1@1+ (1,0) [0|0] ""  BMU
 SG_ M25_CellVoltageMean_Valid : 15|1@1+ (1,0) [0|0] ""  BMU
 SG_ M25_Tem_Mean : 16|11@1+ (0.1,-40) [0|0] "℃"  BMU
 SG_ M25_CellVoltageMean : 0|15@1- (0.001,0) [0|0] "V"  BMU

BO_ 642 Lecu24MsgB: 8 Vector__XXX
 SG_ M24_Heating_OverTemp_Flag : 27|1@1+ (1,0) [0|0] ""  BMU
 SG_ M24_TempFault : 29|1@1+ (1,0) [0|0] ""  BMU
 SG_ M24_BatteryLost_Error : 28|1@1+ (1,0) [0|0] ""  BMU
 SG_ M24_JumperTemp_Max m1 : 48|11@1+ (0.1,-40) [0|0] "℃"  BMU
 SG_ M24_BalanceTemp_Max m0 : 48|11@1+ (0.1,-40) [0|0] "℃"  BMU
 SG_ M24_BalanceFailure : 30|1@1+ (1,0) [0|0] ""  BMU
 SG_ M24_Tem_Min_Num : 40|3@1+ (1,0) [0|0] ""  BMU
 SG_ M24_Tem_Max_Num : 32|3@1+ (1,0) [0|0] ""  BMU
 SG_ M24_CellVoltageMin_Num : 43|5@1+ (1,0) [0|31] ""  BMU
 SG_ M24_CellVoltageMax_Num : 35|5@1+ (1,0) [0|31] ""  BMU
 SG_ M24_JumperTemp_Max_Valid m1 : 63|1@1+ (1,0) [0|0] ""  BMU
 SG_ M24_BalanceTemp_Max_Valid m0 : 63|1@1+ (1,0) [0|0] ""  BMU
 SG_ M24_Temp_Choice M : 59|4@1+ (1,0) [0|0] ""  BMU
 SG_ M24_Tem_Mean_Valid : 31|1@1+ (1,0) [0|0] ""  BMU
 SG_ M24_CellVoltageMean_Valid : 15|1@1+ (1,0) [0|0] ""  BMU
 SG_ M24_Tem_Mean : 16|11@1+ (0.1,-40) [0|0] "℃"  BMU
 SG_ M24_CellVoltageMean : 0|15@1- (0.001,0) [0|0] "V"  BMU

BO_ 626 Lecu23MsgB: 8 Vector__XXX
 SG_ M23_Heating_OverTemp_Flag : 27|1@1+ (1,0) [0|0] ""  BMU
 SG_ M23_TempFault : 29|1@1+ (1,0) [0|0] ""  BMU
 SG_ M23_BatteryLost_Error : 28|1@1+ (1,0) [0|0] ""  BMU
 SG_ M23_JumperTemp_Max m1 : 48|11@1+ (0.1,-40) [0|0] "℃"  BMU
 SG_ M23_BalanceTemp_Max m0 : 48|11@1+ (0.1,-40) [0|0] "℃"  BMU
 SG_ M23_BalanceFailure : 30|1@1+ (1,0) [0|0] ""  BMU
 SG_ M23_Tem_Min_Num : 40|3@1+ (1,0) [0|0] ""  BMU
 SG_ M23_Tem_Max_Num : 32|3@1+ (1,0) [0|0] ""  BMU
 SG_ M23_CellVoltageMin_Num : 43|5@1+ (1,0) [0|31] ""  BMU
 SG_ M23_CellVoltageMax_Num : 35|5@1+ (1,0) [0|31] ""  BMU
 SG_ M23_JumperTemp_Max_Valid m1 : 63|1@1+ (1,0) [0|0] ""  BMU
 SG_ M23_BalanceTemp_Max_Valid m0 : 63|1@1+ (1,0) [0|0] ""  BMU
 SG_ M23_Temp_Choice M : 59|4@1+ (1,0) [0|0] ""  BMU
 SG_ M23_Tem_Mean_Valid : 31|1@1+ (1,0) [0|0] ""  BMU
 SG_ M23_CellVoltageMean_Valid : 15|1@1+ (1,0) [0|0] ""  BMU
 SG_ M23_Tem_Mean : 16|11@1+ (0.1,-40) [0|0] "℃"  BMU
 SG_ M23_CellVoltageMean : 0|15@1- (0.001,0) [0|0] "V"  BMU

BO_ 610 Lecu22MsgB: 8 Vector__XXX
 SG_ M22_Heating_OverTemp_Flag : 27|1@1+ (1,0) [0|0] ""  BMU
 SG_ M22_TempFault : 29|1@1+ (1,0) [0|0] ""  BMU
 SG_ M22_BatteryLost_Error : 28|1@1+ (1,0) [0|0] ""  BMU
 SG_ M22_JumperTemp_Max m1 : 48|11@1+ (0.1,-40) [0|0] "℃"  BMU
 SG_ M22_BalanceTemp_Max m0 : 48|11@1+ (0.1,-40) [0|0] "℃"  BMU
 SG_ M22_BalanceFailure : 30|1@1+ (1,0) [0|0] ""  BMU
 SG_ M22_Tem_Min_Num : 40|3@1+ (1,0) [0|0] ""  BMU
 SG_ M22_Tem_Max_Num : 32|3@1+ (1,0) [0|0] ""  BMU
 SG_ M22_CellVoltageMin_Num : 43|5@1+ (1,0) [0|31] ""  BMU
 SG_ M22_CellVoltageMax_Num : 35|5@1+ (1,0) [0|31] ""  BMU
 SG_ M22_JumperTemp_Max_Valid m1 : 63|1@1+ (1,0) [0|0] ""  BMU
 SG_ M22_BalanceTemp_Max_Valid m0 : 63|1@1+ (1,0) [0|0] ""  BMU
 SG_ M22_Temp_Choice M : 59|4@1+ (1,0) [0|0] ""  BMU
 SG_ M22_Tem_Mean_Valid : 31|1@1+ (1,0) [0|0] ""  BMU
 SG_ M22_CellVoltageMean_Valid : 15|1@1+ (1,0) [0|0] ""  BMU
 SG_ M22_Tem_Mean : 16|11@1+ (0.1,-40) [0|0] "℃"  BMU
 SG_ M22_CellVoltageMean : 0|15@1- (0.001,0) [0|0] "V"  BMU

BO_ 594 Lecu21MsgB: 8 Vector__XXX
 SG_ M21_Heating_OverTemp_Flag : 27|1@1+ (1,0) [0|0] ""  BMU
 SG_ M21_TempFault : 29|1@1+ (1,0) [0|0] ""  BMU
 SG_ M21_BatteryLost_Error : 28|1@1+ (1,0) [0|0] ""  BMU
 SG_ M21_JumperTemp_Max m1 : 48|11@1+ (0.1,-40) [0|0] "℃"  BMU
 SG_ M21_BalanceTemp_Max m0 : 48|11@1+ (0.1,-40) [0|0] "℃"  BMU
 SG_ M21_BalanceFailure : 30|1@1+ (1,0) [0|0] ""  BMU
 SG_ M21_Tem_Min_Num : 40|3@1+ (1,0) [0|0] ""  BMU
 SG_ M21_Tem_Max_Num : 32|3@1+ (1,0) [0|0] ""  BMU
 SG_ M21_CellVoltageMin_Num : 43|5@1+ (1,0) [0|31] ""  BMU
 SG_ M21_CellVoltageMax_Num : 35|5@1+ (1,0) [0|31] ""  BMU
 SG_ M21_JumperTemp_Max_Valid m1 : 63|1@1+ (1,0) [0|0] ""  BMU
 SG_ M21_BalanceTemp_Max_Valid m0 : 63|1@1+ (1,0) [0|0] ""  BMU
 SG_ M21_Temp_Choice M : 59|4@1+ (1,0) [0|0] ""  BMU
 SG_ M21_Tem_Mean_Valid : 31|1@1+ (1,0) [0|0] ""  BMU
 SG_ M21_CellVoltageMean_Valid : 15|1@1+ (1,0) [0|0] ""  BMU
 SG_ M21_Tem_Mean : 16|11@1+ (0.1,-40) [0|0] "℃"  BMU
 SG_ M21_CellVoltageMean : 0|15@1- (0.001,0) [0|0] "V"  BMU

BO_ 578 Lecu20MsgB: 8 Vector__XXX
 SG_ M20_Heating_OverTemp_Flag : 27|1@1+ (1,0) [0|0] ""  BMU
 SG_ M20_TempFault : 29|1@1+ (1,0) [0|0] ""  BMU
 SG_ M20_BatteryLost_Error : 28|1@1+ (1,0) [0|0] ""  BMU
 SG_ M20_JumperTemp_Max m1 : 48|11@1+ (0.1,-40) [0|0] "℃"  BMU
 SG_ M20_BalanceTemp_Max m0 : 48|11@1+ (0.1,-40) [0|0] "℃"  BMU
 SG_ M20_BalanceFailure : 30|1@1+ (1,0) [0|0] ""  BMU
 SG_ M20_Tem_Min_Num : 40|3@1+ (1,0) [0|0] ""  BMU
 SG_ M20_Tem_Max_Num : 32|3@1+ (1,0) [0|0] ""  BMU
 SG_ M20_CellVoltageMin_Num : 43|5@1+ (1,0) [0|31] ""  BMU
 SG_ M20_CellVoltageMax_Num : 35|5@1+ (1,0) [0|31] ""  BMU
 SG_ M20_JumperTemp_Max_Valid m1 : 63|1@1+ (1,0) [0|0] ""  BMU
 SG_ M20_BalanceTemp_Max_Valid m0 : 63|1@1+ (1,0) [0|0] ""  BMU
 SG_ M20_Temp_Choice M : 59|4@1+ (1,0) [0|0] ""  BMU
 SG_ M20_Tem_Mean_Valid : 31|1@1+ (1,0) [0|0] ""  BMU
 SG_ M20_CellVoltageMean_Valid : 15|1@1+ (1,0) [0|0] ""  BMU
 SG_ M20_Tem_Mean : 16|11@1+ (0.1,-40) [0|0] "℃"  BMU
 SG_ M20_CellVoltageMean : 0|15@1- (0.001,0) [0|0] "V"  BMU

BO_ 562 Lecu19MsgB: 8 Vector__XXX
 SG_ M19_Heating_OverTemp_Flag : 27|1@1+ (1,0) [0|0] ""  BMU
 SG_ M19_TempFault : 29|1@1+ (1,0) [0|0] ""  BMU
 SG_ M19_BatteryLost_Error : 28|1@1+ (1,0) [0|0] ""  BMU
 SG_ M19_JumperTemp_Max m1 : 48|11@1+ (0.1,-40) [0|0] "℃"  BMU
 SG_ M19_BalanceTemp_Max m0 : 48|11@1+ (0.1,-40) [0|0] "℃"  BMU
 SG_ M19_BalanceFailure : 30|1@1+ (1,0) [0|0] ""  BMU
 SG_ M19_Tem_Min_Num : 40|3@1+ (1,0) [0|0] ""  BMU
 SG_ M19_Tem_Max_Num : 32|3@1+ (1,0) [0|0] ""  BMU
 SG_ M19_CellVoltageMin_Num : 43|5@1+ (1,0) [0|31] ""  BMU
 SG_ M19_CellVoltageMax_Num : 35|5@1+ (1,0) [0|31] ""  BMU
 SG_ M19_JumperTemp_Max_Valid m1 : 63|1@1+ (1,0) [0|0] ""  BMU
 SG_ M19_BalanceTemp_Max_Valid m0 : 63|1@1+ (1,0) [0|0] ""  BMU
 SG_ M19_Temp_Choice M : 59|4@1+ (1,0) [0|0] ""  BMU
 SG_ M19_Tem_Mean_Valid : 31|1@1+ (1,0) [0|0] ""  BMU
 SG_ M19_CellVoltageMean_Valid : 15|1@1+ (1,0) [0|0] ""  BMU
 SG_ M19_Tem_Mean : 16|11@1+ (0.1,-40) [0|0] "℃"  BMU
 SG_ M19_CellVoltageMean : 0|15@1- (0.001,0) [0|0] "V"  BMU

BO_ 546 Lecu18MsgB: 8 Vector__XXX
 SG_ M18_Heating_OverTemp_Flag : 27|1@1+ (1,0) [0|0] ""  BMU
 SG_ M18_TempFault : 29|1@1+ (1,0) [0|0] ""  BMU
 SG_ M18_BatteryLost_Error : 28|1@1+ (1,0) [0|0] ""  BMU
 SG_ M18_JumperTemp_Max m1 : 48|11@1+ (0.1,-40) [0|0] "℃"  BMU
 SG_ M18_BalanceTemp_Max m0 : 48|11@1+ (0.1,-40) [0|0] "℃"  BMU
 SG_ M18_BalanceFailure : 30|1@1+ (1,0) [0|0] ""  BMU
 SG_ M18_Tem_Min_Num : 40|3@1+ (1,0) [0|0] ""  BMU
 SG_ M18_Tem_Max_Num : 32|3@1+ (1,0) [0|0] ""  BMU
 SG_ M18_CellVoltageMin_Num : 43|5@1+ (1,0) [0|31] ""  BMU
 SG_ M18_CellVoltageMax_Num : 35|5@1+ (1,0) [0|31] ""  BMU
 SG_ M18_JumperTemp_Max_Valid m1 : 63|1@1+ (1,0) [0|0] ""  BMU
 SG_ M18_BalanceTemp_Max_Valid m0 : 63|1@1+ (1,0) [0|0] ""  BMU
 SG_ M18_Temp_Choice M : 59|4@1+ (1,0) [0|0] ""  BMU
 SG_ M18_Tem_Mean_Valid : 31|1@1+ (1,0) [0|0] ""  BMU
 SG_ M18_CellVoltageMean_Valid : 15|1@1+ (1,0) [0|0] ""  BMU
 SG_ M18_Tem_Mean : 16|11@1+ (0.1,-40) [0|0] "℃"  BMU
 SG_ M18_CellVoltageMean : 0|15@1- (0.001,0) [0|0] "V"  BMU

BO_ 530 Lecu17MsgB: 8 Vector__XXX
 SG_ M17_Heating_OverTemp_Flag : 27|1@1+ (1,0) [0|0] ""  BMU
 SG_ M17_TempFault : 29|1@1+ (1,0) [0|0] ""  BMU
 SG_ M17_BatteryLost_Error : 28|1@1+ (1,0) [0|0] ""  BMU
 SG_ M17_JumperTemp_Max m1 : 48|11@1+ (0.1,-40) [0|0] "℃"  BMU
 SG_ M17_BalanceTemp_Max m0 : 48|11@1+ (0.1,-40) [0|0] "℃"  BMU
 SG_ M17_BalanceFailure : 30|1@1+ (1,0) [0|0] ""  BMU
 SG_ M17_Tem_Min_Num : 40|3@1+ (1,0) [0|0] ""  BMU
 SG_ M17_Tem_Max_Num : 32|3@1+ (1,0) [0|0] ""  BMU
 SG_ M17_CellVoltageMin_Num : 43|5@1+ (1,0) [0|31] ""  BMU
 SG_ M17_CellVoltageMax_Num : 35|5@1+ (1,0) [0|31] ""  BMU
 SG_ M17_JumperTemp_Max_Valid m1 : 63|1@1+ (1,0) [0|0] ""  BMU
 SG_ M17_BalanceTemp_Max_Valid m0 : 63|1@1+ (1,0) [0|0] ""  BMU
 SG_ M17_Temp_Choice M : 59|4@1+ (1,0) [0|0] ""  BMU
 SG_ M17_Tem_Mean_Valid : 31|1@1+ (1,0) [0|0] ""  BMU
 SG_ M17_CellVoltageMean_Valid : 15|1@1+ (1,0) [0|0] ""  BMU
 SG_ M17_Tem_Mean : 16|11@1+ (0.1,-40) [0|0] "℃"  BMU
 SG_ M17_CellVoltageMean : 0|15@1- (0.001,0) [0|0] "V"  BMU

BO_ 514 Lecu16MsgB: 8 Vector__XXX
 SG_ M16_Heating_OverTemp_Flag : 27|1@1+ (1,0) [0|0] ""  BMU
 SG_ M16_TempFault : 29|1@1+ (1,0) [0|0] ""  BMU
 SG_ M16_BatteryLost_Error : 28|1@1+ (1,0) [0|0] ""  BMU
 SG_ M16_JumperTemp_Max m1 : 48|11@1+ (0.1,-40) [0|0] "℃"  BMU
 SG_ M16_BalanceTemp_Max m0 : 48|11@1+ (0.1,-40) [0|0] "℃"  BMU
 SG_ M16_BalanceFailure : 30|1@1+ (1,0) [0|0] ""  BMU
 SG_ M16_Tem_Min_Num : 40|3@1+ (1,0) [0|0] ""  BMU
 SG_ M16_Tem_Max_Num : 32|3@1+ (1,0) [0|0] ""  BMU
 SG_ M16_CellVoltageMin_Num : 43|5@1+ (1,0) [0|31] ""  BMU
 SG_ M16_CellVoltageMax_Num : 35|5@1+ (1,0) [0|31] ""  BMU
 SG_ M16_JumperTemp_Max_Valid m1 : 63|1@1+ (1,0) [0|0] ""  BMU
 SG_ M16_BalanceTemp_Max_Valid m0 : 63|1@1+ (1,0) [0|0] ""  BMU
 SG_ M16_Temp_Choice M : 59|4@1+ (1,0) [0|0] ""  BMU
 SG_ M16_Tem_Mean_Valid : 31|1@1+ (1,0) [0|0] ""  BMU
 SG_ M16_CellVoltageMean_Valid : 15|1@1+ (1,0) [0|0] ""  BMU
 SG_ M16_Tem_Mean : 16|11@1+ (0.1,-40) [0|0] "℃"  BMU
 SG_ M16_CellVoltageMean : 0|15@1- (0.001,0) [0|0] "V"  BMU

BO_ 498 Lecu15MsgB: 8 Vector__XXX
 SG_ M15_Heating_OverTemp_Flag : 27|1@1+ (1,0) [0|0] ""  BMU
 SG_ M15_TempFault : 29|1@1+ (1,0) [0|0] ""  BMU
 SG_ M15_BatteryLost_Error : 28|1@1+ (1,0) [0|0] ""  BMU
 SG_ M15_JumperTemp_Max m1 : 48|11@1+ (0.1,-40) [0|0] "℃"  BMU
 SG_ M15_BalanceTemp_Max m0 : 48|11@1+ (0.1,-40) [0|0] "℃"  BMU
 SG_ M15_BalanceFailure : 30|1@1+ (1,0) [0|0] ""  BMU
 SG_ M15_Tem_Min_Num : 40|3@1+ (1,0) [0|0] ""  BMU
 SG_ M15_Tem_Max_Num : 32|3@1+ (1,0) [0|0] ""  BMU
 SG_ M15_CellVoltageMin_Num : 43|5@1+ (1,0) [0|31] ""  BMU
 SG_ M15_CellVoltageMax_Num : 35|5@1+ (1,0) [0|31] ""  BMU
 SG_ M15_JumperTemp_Max_Valid m1 : 63|1@1+ (1,0) [0|0] ""  BMU
 SG_ M15_BalanceTemp_Max_Valid m0 : 63|1@1+ (1,0) [0|0] ""  BMU
 SG_ M15_Temp_Choice M : 59|4@1+ (1,0) [0|0] ""  BMU
 SG_ M15_Tem_Mean_Valid : 31|1@1+ (1,0) [0|0] ""  BMU
 SG_ M15_CellVoltageMean_Valid : 15|1@1+ (1,0) [0|0] ""  BMU
 SG_ M15_Tem_Mean : 16|11@1+ (0.1,-40) [0|0] "℃"  BMU
 SG_ M15_CellVoltageMean : 0|15@1- (0.001,0) [0|0] "V"  BMU

BO_ 482 Lecu14MsgB: 8 Vector__XXX
 SG_ M14_Heating_OverTemp_Flag : 27|1@1+ (1,0) [0|0] ""  BMU
 SG_ M14_TempFault : 29|1@1+ (1,0) [0|0] ""  BMU
 SG_ M14_BatteryLost_Error : 28|1@1+ (1,0) [0|0] ""  BMU
 SG_ M14_JumperTemp_Max m1 : 48|11@1+ (0.1,-40) [0|0] "℃"  BMU
 SG_ M14_BalanceTemp_Max m0 : 48|11@1+ (0.1,-40) [0|0] "℃"  BMU
 SG_ M14_BalanceFailure : 30|1@1+ (1,0) [0|0] ""  BMU
 SG_ M14_Tem_Min_Num : 40|3@1+ (1,0) [0|0] ""  BMU
 SG_ M14_Tem_Max_Num : 32|3@1+ (1,0) [0|0] ""  BMU
 SG_ M14_CellVoltageMin_Num : 43|5@1+ (1,0) [0|31] ""  BMU
 SG_ M14_CellVoltageMax_Num : 35|5@1+ (1,0) [0|31] ""  BMU
 SG_ M14_JumperTemp_Max_Valid m1 : 63|1@1+ (1,0) [0|0] ""  BMU
 SG_ M14_BalanceTemp_Max_Valid m0 : 63|1@1+ (1,0) [0|0] ""  BMU
 SG_ M14_Temp_Choice M : 59|4@1+ (1,0) [0|0] ""  BMU
 SG_ M14_Tem_Mean_Valid : 31|1@1+ (1,0) [0|0] ""  BMU
 SG_ M14_CellVoltageMean_Valid : 15|1@1+ (1,0) [0|0] ""  BMU
 SG_ M14_Tem_Mean : 16|11@1+ (0.1,-40) [0|0] "℃"  BMU
 SG_ M14_CellVoltageMean : 0|15@1- (0.001,0) [0|0] "V"  BMU

BO_ 466 Lecu13MsgB: 8 Vector__XXX
 SG_ M13_Heating_OverTemp_Flag : 27|1@1+ (1,0) [0|0] ""  BMU
 SG_ M13_TempFault : 29|1@1+ (1,0) [0|0] ""  BMU
 SG_ M13_BatteryLost_Error : 28|1@1+ (1,0) [0|0] ""  BMU
 SG_ M13_JumperTemp_Max m1 : 48|11@1+ (0.1,-40) [0|0] "℃"  BMU
 SG_ M13_BalanceTemp_Max m0 : 48|11@1+ (0.1,-40) [0|0] "℃"  BMU
 SG_ M13_BalanceFailure : 30|1@1+ (1,0) [0|0] ""  BMU
 SG_ M13_Tem_Min_Num : 40|3@1+ (1,0) [0|0] ""  BMU
 SG_ M13_Tem_Max_Num : 32|3@1+ (1,0) [0|0] ""  BMU
 SG_ M13_CellVoltageMin_Num : 43|5@1+ (1,0) [0|31] ""  BMU
 SG_ M13_CellVoltageMax_Num : 35|5@1+ (1,0) [0|31] ""  BMU
 SG_ M13_JumperTemp_Max_Valid m1 : 63|1@1+ (1,0) [0|0] ""  BMU
 SG_ M13_BalanceTemp_Max_Valid m0 : 63|1@1+ (1,0) [0|0] ""  BMU
 SG_ M13_Temp_Choice M : 59|4@1+ (1,0) [0|0] ""  BMU
 SG_ M13_Tem_Mean_Valid : 31|1@1+ (1,0) [0|0] ""  BMU
 SG_ M13_CellVoltageMean_Valid : 15|1@1+ (1,0) [0|0] ""  BMU
 SG_ M13_Tem_Mean : 16|11@1+ (0.1,-40) [0|0] "℃"  BMU
 SG_ M13_CellVoltageMean : 0|15@1- (0.001,0) [0|0] "V"  BMU

BO_ 450 Lecu12MsgB: 8 Vector__XXX
 SG_ M12_Heating_OverTemp_Flag : 27|1@1+ (1,0) [0|0] ""  BMU
 SG_ M12_TempFault : 29|1@1+ (1,0) [0|0] ""  BMU
 SG_ M12_BatteryLost_Error : 28|1@1+ (1,0) [0|0] ""  BMU
 SG_ M12_JumperTemp_Max m1 : 48|11@1+ (0.1,-40) [0|0] "℃"  BMU
 SG_ M12_BalanceTemp_Max m0 : 48|11@1+ (0.1,-40) [0|0] "℃"  BMU
 SG_ M12_BalanceFailure : 30|1@1+ (1,0) [0|0] ""  BMU
 SG_ M12_Tem_Min_Num : 40|3@1+ (1,0) [0|0] ""  BMU
 SG_ M12_Tem_Max_Num : 32|3@1+ (1,0) [0|0] ""  BMU
 SG_ M12_CellVoltageMin_Num : 43|5@1+ (1,0) [0|31] ""  BMU
 SG_ M12_CellVoltageMax_Num : 35|5@1+ (1,0) [0|31] ""  BMU
 SG_ M12_JumperTemp_Max_Valid m1 : 63|1@1+ (1,0) [0|0] ""  BMU
 SG_ M12_BalanceTemp_Max_Valid m0 : 63|1@1+ (1,0) [0|0] ""  BMU
 SG_ M12_Temp_Choice M : 59|4@1+ (1,0) [0|0] ""  BMU
 SG_ M12_Tem_Mean_Valid : 31|1@1+ (1,0) [0|0] ""  BMU
 SG_ M12_CellVoltageMean_Valid : 15|1@1+ (1,0) [0|0] ""  BMU
 SG_ M12_Tem_Mean : 16|11@1+ (0.1,-40) [0|0] "℃"  BMU
 SG_ M12_CellVoltageMean : 0|15@1- (0.001,0) [0|0] "V"  BMU

BO_ 434 Lecu11MsgB: 8 Vector__XXX
 SG_ M11_Heating_OverTemp_Flag : 27|1@1+ (1,0) [0|0] ""  BMU
 SG_ M11_TempFault : 29|1@1+ (1,0) [0|0] ""  BMU
 SG_ M11_BatteryLost_Error : 28|1@1+ (1,0) [0|0] ""  BMU
 SG_ M11_JumperTemp_Max m1 : 48|11@1+ (0.1,-40) [0|0] "℃"  BMU
 SG_ M11_BalanceTemp_Max m0 : 48|11@1+ (0.1,-40) [0|0] "℃"  BMU
 SG_ M11_BalanceFailure : 30|1@1+ (1,0) [0|0] ""  BMU
 SG_ M11_Tem_Min_Num : 40|3@1+ (1,0) [0|0] ""  BMU
 SG_ M11_Tem_Max_Num : 32|3@1+ (1,0) [0|0] ""  BMU
 SG_ M11_CellVoltageMin_Num : 43|5@1+ (1,0) [0|31] ""  BMU
 SG_ M11_CellVoltageMax_Num : 35|5@1+ (1,0) [0|31] ""  BMU
 SG_ M11_JumperTemp_Max_Valid m1 : 63|1@1+ (1,0) [0|0] ""  BMU
 SG_ M11_BalanceTemp_Max_Valid m0 : 63|1@1+ (1,0) [0|0] ""  BMU
 SG_ M11_Temp_Choice M : 59|4@1+ (1,0) [0|0] ""  BMU
 SG_ M11_Tem_Mean_Valid : 31|1@1+ (1,0) [0|0] ""  BMU
 SG_ M11_CellVoltageMean_Valid : 15|1@1+ (1,0) [0|0] ""  BMU
 SG_ M11_Tem_Mean : 16|11@1+ (0.1,-40) [0|0] "℃"  BMU
 SG_ M11_CellVoltageMean : 0|15@1- (0.001,0) [0|0] "V"  BMU

BO_ 418 Lecu10MsgB: 8 Vector__XXX
 SG_ M10_Heating_OverTemp_Flag : 27|1@1+ (1,0) [0|0] ""  BMU
 SG_ M10_TempFault : 29|1@1+ (1,0) [0|0] ""  BMU
 SG_ M10_BatteryLost_Error : 28|1@1+ (1,0) [0|0] ""  BMU
 SG_ M10_JumperTemp_Max m1 : 48|11@1+ (0.1,-40) [0|0] "℃"  BMU
 SG_ M10_BalanceTemp_Max m0 : 48|11@1+ (0.1,-40) [0|0] "℃"  BMU
 SG_ M10_BalanceFailure : 30|1@1+ (1,0) [0|0] ""  BMU
 SG_ M10_Tem_Min_Num : 40|3@1+ (1,0) [0|0] ""  BMU
 SG_ M10_Tem_Max_Num : 32|3@1+ (1,0) [0|0] ""  BMU
 SG_ M10_CellVoltageMin_Num : 43|5@1+ (1,0) [0|31] ""  BMU
 SG_ M10_CellVoltageMax_Num : 35|5@1+ (1,0) [0|31] ""  BMU
 SG_ M10_JumperTemp_Max_Valid m1 : 63|1@1+ (1,0) [0|0] ""  BMU
 SG_ M10_BalanceTemp_Max_Valid m0 : 63|1@1+ (1,0) [0|0] ""  BMU
 SG_ M10_Temp_Choice M : 59|4@1+ (1,0) [0|0] ""  BMU
 SG_ M10_Tem_Mean_Valid : 31|1@1+ (1,0) [0|0] ""  BMU
 SG_ M10_CellVoltageMean_Valid : 15|1@1+ (1,0) [0|0] ""  BMU
 SG_ M10_Tem_Mean : 16|11@1+ (0.1,-40) [0|0] "℃"  BMU
 SG_ M10_CellVoltageMean : 0|15@1- (0.001,0) [0|0] "V"  BMU

BO_ 402 Lecu9MsgB: 8 Vector__XXX
 SG_ M9_Heating_OverTemp_Flag : 27|1@1+ (1,0) [0|0] ""  BMU
 SG_ M9_TempFault : 29|1@1+ (1,0) [0|0] ""  BMU
 SG_ M9_BatteryLost_Error : 28|1@1+ (1,0) [0|0] ""  BMU
 SG_ M9_JumperTemp_Max m1 : 48|11@1+ (0.1,-40) [0|0] "℃"  BMU
 SG_ M9_BalanceTemp_Max m0 : 48|11@1+ (0.1,-40) [0|0] "℃"  BMU
 SG_ M9_BalanceFailure : 30|1@1+ (1,0) [0|0] ""  BMU
 SG_ M9_Tem_Min_Num : 40|3@1+ (1,0) [0|0] ""  BMU
 SG_ M9_Tem_Max_Num : 32|3@1+ (1,0) [0|0] ""  BMU
 SG_ M9_CellVoltageMin_Num : 43|5@1+ (1,0) [0|31] ""  BMU
 SG_ M9_CellVoltageMax_Num : 35|5@1+ (1,0) [0|31] ""  BMU
 SG_ M9_JumperTemp_Max_Valid m1 : 63|1@1+ (1,0) [0|0] ""  BMU
 SG_ M9_BalanceTemp_Max_Valid m0 : 63|1@1+ (1,0) [0|0] ""  BMU
 SG_ M9_Temp_Choice M : 59|4@1+ (1,0) [0|0] ""  BMU
 SG_ M9_Tem_Mean_Valid : 31|1@1+ (1,0) [0|0] ""  BMU
 SG_ M9_CellVoltageMean_Valid : 15|1@1+ (1,0) [0|0] ""  BMU
 SG_ M9_Tem_Mean : 16|11@1+ (0.1,-40) [0|0] "℃"  BMU
 SG_ M9_CellVoltageMean : 0|15@1- (0.001,0) [0|0] "V"  BMU

BO_ 386 Lecu8MsgB: 8 Vector__XXX
 SG_ M8_Heating_OverTemp_Flag : 27|1@1+ (1,0) [0|0] ""  BMU
 SG_ M8_TempFault : 29|1@1+ (1,0) [0|0] ""  BMU
 SG_ M8_BatteryLost_Error : 28|1@1+ (1,0) [0|0] ""  BMU
 SG_ M8_JumperTemp_Max m1 : 48|11@1+ (0.1,-40) [0|0] "℃"  BMU
 SG_ M8_BalanceTemp_Max m0 : 48|11@1+ (0.1,-40) [0|0] "℃"  BMU
 SG_ M8_BalanceFailure : 30|1@1+ (1,0) [0|0] ""  BMU
 SG_ M8_Tem_Min_Num : 40|3@1+ (1,0) [0|0] ""  BMU
 SG_ M8_Tem_Max_Num : 32|3@1+ (1,0) [0|0] ""  BMU
 SG_ M8_CellVoltageMin_Num : 43|5@1+ (1,0) [0|31] ""  BMU
 SG_ M8_CellVoltageMax_Num : 35|5@1+ (1,0) [0|31] ""  BMU
 SG_ M8_JumperTemp_Max_Valid m1 : 63|1@1+ (1,0) [0|0] ""  BMU
 SG_ M8_BalanceTemp_Max_Valid m0 : 63|1@1+ (1,0) [0|0] ""  BMU
 SG_ M8_Temp_Choice M : 59|4@1+ (1,0) [0|0] ""  BMU
 SG_ M8_Tem_Mean_Valid : 31|1@1+ (1,0) [0|0] ""  BMU
 SG_ M8_CellVoltageMean_Valid : 15|1@1+ (1,0) [0|0] ""  BMU
 SG_ M8_Tem_Mean : 16|11@1+ (0.1,-40) [0|0] "℃"  BMU
 SG_ M8_CellVoltageMean : 0|15@1- (0.001,0) [0|0] "V"  BMU

BO_ 370 Lecu7MsgB: 8 Vector__XXX
 SG_ M7_Heating_OverTemp_Flag : 27|1@1+ (1,0) [0|0] ""  BMU
 SG_ M7_TempFault : 29|1@1+ (1,0) [0|0] ""  BMU
 SG_ M7_BatteryLost_Error : 28|1@1+ (1,0) [0|0] ""  BMU
 SG_ M7_JumperTemp_Max m1 : 48|11@1+ (0.1,-40) [0|0] "℃"  BMU
 SG_ M7_BalanceTemp_Max m0 : 48|11@1+ (0.1,-40) [0|0] "℃"  BMU
 SG_ M7_BalanceFailure : 30|1@1+ (1,0) [0|0] ""  BMU
 SG_ M7_Tem_Min_Num : 40|3@1+ (1,0) [0|0] ""  BMU
 SG_ M7_Tem_Max_Num : 32|3@1+ (1,0) [0|0] ""  BMU
 SG_ M7_CellVoltageMin_Num : 43|5@1+ (1,0) [0|31] ""  BMU
 SG_ M7_CellVoltageMax_Num : 35|5@1+ (1,0) [0|31] ""  BMU
 SG_ M7_JumperTemp_Max_Valid m1 : 63|1@1+ (1,0) [0|0] ""  BMU
 SG_ M7_BalanceTemp_Max_Valid m0 : 63|1@1+ (1,0) [0|0] ""  BMU
 SG_ M7_Temp_Choice M : 59|4@1+ (1,0) [0|0] ""  BMU
 SG_ M7_Tem_Mean_Valid : 31|1@1+ (1,0) [0|0] ""  BMU
 SG_ M7_CellVoltageMean_Valid : 15|1@1+ (1,0) [0|0] ""  BMU
 SG_ M7_Tem_Mean : 16|11@1+ (0.1,-40) [0|0] "℃"  BMU
 SG_ M7_CellVoltageMean : 0|15@1- (0.001,0) [0|0] "V"  BMU

BO_ 354 Lecu6MsgB: 8 Vector__XXX
 SG_ M6_Heating_OverTemp_Flag : 27|1@1+ (1,0) [0|0] ""  BMU
 SG_ M6_TempFault : 29|1@1+ (1,0) [0|0] ""  BMU
 SG_ M6_BatteryLost_Error : 28|1@1+ (1,0) [0|0] ""  BMU
 SG_ M6_JumperTemp_Max m1 : 48|11@1+ (0.1,-40) [0|0] "℃"  BMU
 SG_ M6_BalanceTemp_Max m0 : 48|11@1+ (0.1,-40) [0|0] "℃"  BMU
 SG_ M6_BalanceFailure : 30|1@1+ (1,0) [0|0] ""  BMU
 SG_ M6_Tem_Min_Num : 40|3@1+ (1,0) [0|0] ""  BMU
 SG_ M6_Tem_Max_Num : 32|3@1+ (1,0) [0|0] ""  BMU
 SG_ M6_CellVoltageMin_Num : 43|5@1+ (1,0) [0|31] ""  BMU
 SG_ M6_CellVoltageMax_Num : 35|5@1+ (1,0) [0|31] ""  BMU
 SG_ M6_JumperTemp_Max_Valid m1 : 63|1@1+ (1,0) [0|0] ""  BMU
 SG_ M6_BalanceTemp_Max_Valid m0 : 63|1@1+ (1,0) [0|0] ""  BMU
 SG_ M6_Temp_Choice M : 59|4@1+ (1,0) [0|0] ""  BMU
 SG_ M6_Tem_Mean_Valid : 31|1@1+ (1,0) [0|0] ""  BMU
 SG_ M6_CellVoltageMean_Valid : 15|1@1+ (1,0) [0|0] ""  BMU
 SG_ M6_Tem_Mean : 16|11@1+ (0.1,-40) [0|0] "℃"  BMU
 SG_ M6_CellVoltageMean : 0|15@1- (0.001,0) [0|0] "V"  BMU

BO_ 338 Lecu5MsgB: 8 Vector__XXX
 SG_ M5_Heating_OverTemp_Flag : 27|1@1+ (1,0) [0|0] ""  BMU
 SG_ M5_TempFault : 29|1@1+ (1,0) [0|0] ""  BMU
 SG_ M5_BatteryLost_Error : 28|1@1+ (1,0) [0|0] ""  BMU
 SG_ M5_JumperTemp_Max m1 : 48|11@1+ (0.1,-40) [0|0] "℃"  BMU
 SG_ M5_BalanceTemp_Max m0 : 48|11@1+ (0.1,-40) [0|0] "℃"  BMU
 SG_ M5_BalanceFailure : 30|1@1+ (1,0) [0|0] ""  BMU
 SG_ M5_Tem_Min_Num : 40|3@1+ (1,0) [0|0] ""  BMU
 SG_ M5_Tem_Max_Num : 32|3@1+ (1,0) [0|0] ""  BMU
 SG_ M5_CellVoltageMin_Num : 43|5@1+ (1,0) [0|31] ""  BMU
 SG_ M5_CellVoltageMax_Num : 35|5@1+ (1,0) [0|31] ""  BMU
 SG_ M5_JumperTemp_Max_Valid m1 : 63|1@1+ (1,0) [0|0] ""  BMU
 SG_ M5_BalanceTemp_Max_Valid m0 : 63|1@1+ (1,0) [0|0] ""  BMU
 SG_ M5_Temp_Choice M : 59|4@1+ (1,0) [0|0] ""  BMU
 SG_ M5_Tem_Mean_Valid : 31|1@1+ (1,0) [0|0] ""  BMU
 SG_ M5_CellVoltageMean_Valid : 15|1@1+ (1,0) [0|0] ""  BMU
 SG_ M5_Tem_Mean : 16|11@1+ (0.1,-40) [0|0] "℃"  BMU
 SG_ M5_CellVoltageMean : 0|15@1- (0.001,0) [0|0] "V"  BMU

BO_ 322 Lecu4MsgB: 8 Vector__XXX
 SG_ M4_Heating_OverTemp_Flag : 27|1@1+ (1,0) [0|0] ""  BMU
 SG_ M4_TempFault : 29|1@1+ (1,0) [0|0] ""  BMU
 SG_ M4_BatteryLost_Error : 28|1@1+ (1,0) [0|0] ""  BMU
 SG_ M4_JumperTemp_Max m1 : 48|11@1+ (0.1,-40) [0|0] "℃"  BMU
 SG_ M4_BalanceTemp_Max m0 : 48|11@1+ (0.1,-40) [0|0] "℃"  BMU
 SG_ M4_BalanceFailure : 30|1@1+ (1,0) [0|0] ""  BMU
 SG_ M4_Tem_Min_Num : 40|3@1+ (1,0) [0|0] ""  BMU
 SG_ M4_Tem_Max_Num : 32|3@1+ (1,0) [0|0] ""  BMU
 SG_ M4_CellVoltageMin_Num : 43|5@1+ (1,0) [0|31] ""  BMU
 SG_ M4_CellVoltageMax_Num : 35|5@1+ (1,0) [0|31] ""  BMU
 SG_ M4_JumperTemp_Max_Valid m1 : 63|1@1+ (1,0) [0|0] ""  BMU
 SG_ M4_BalanceTemp_Max_Valid m0 : 63|1@1+ (1,0) [0|0] ""  BMU
 SG_ M4_Temp_Choice M : 59|4@1+ (1,0) [0|0] ""  BMU
 SG_ M4_Tem_Mean_Valid : 31|1@1+ (1,0) [0|0] ""  BMU
 SG_ M4_CellVoltageMean_Valid : 15|1@1+ (1,0) [0|0] ""  BMU
 SG_ M4_Tem_Mean : 16|11@1+ (0.1,-40) [0|0] "℃"  BMU
 SG_ M4_CellVoltageMean : 0|15@1- (0.001,0) [0|0] "V"  BMU

BO_ 306 Lecu3MsgB: 8 Vector__XXX
 SG_ M3_Heating_OverTemp_Flag : 27|1@1+ (1,0) [0|0] ""  BMU
 SG_ M3_TempFault : 29|1@1+ (1,0) [0|0] ""  BMU
 SG_ M3_BatteryLost_Error : 28|1@1+ (1,0) [0|0] ""  BMU
 SG_ M3_JumperTemp_Max m1 : 48|11@1+ (0.1,-40) [0|0] "℃"  BMU
 SG_ M3_BalanceTemp_Max m0 : 48|11@1+ (0.1,-40) [0|0] "℃"  BMU
 SG_ M3_BalanceFailure : 30|1@1+ (1,0) [0|0] ""  BMU
 SG_ M3_Tem_Min_Num : 40|3@1+ (1,0) [0|0] ""  BMU
 SG_ M3_Tem_Max_Num : 32|3@1+ (1,0) [0|0] ""  BMU
 SG_ M3_CellVoltageMin_Num : 43|5@1+ (1,0) [0|31] ""  BMU
 SG_ M3_CellVoltageMax_Num : 35|5@1+ (1,0) [0|31] ""  BMU
 SG_ M3_JumperTemp_Max_Valid m1 : 63|1@1+ (1,0) [0|0] ""  BMU
 SG_ M3_BalanceTemp_Max_Valid m0 : 63|1@1+ (1,0) [0|0] ""  BMU
 SG_ M3_Temp_Choice M : 59|4@1+ (1,0) [0|0] ""  BMU
 SG_ M3_Tem_Mean_Valid : 31|1@1+ (1,0) [0|0] ""  BMU
 SG_ M3_CellVoltageMean_Valid : 15|1@1+ (1,0) [0|0] ""  BMU
 SG_ M3_Tem_Mean : 16|11@1+ (0.1,-40) [0|0] "℃"  BMU
 SG_ M3_CellVoltageMean : 0|15@1- (0.001,0) [0|0] "V"  BMU

BO_ 290 Lecu2MsgB: 8 Vector__XXX
 SG_ M2_Heating_OverTemp_Flag : 27|1@1+ (1,0) [0|0] ""  BMU
 SG_ M2_TempFault : 29|1@1+ (1,0) [0|0] ""  BMU
 SG_ M2_BatteryLost_Error : 28|1@1+ (1,0) [0|0] ""  BMU
 SG_ M2_JumperTemp_Max m1 : 48|11@1+ (0.1,-40) [0|0] "℃"  BMU
 SG_ M2_BalanceTemp_Max m0 : 48|11@1+ (0.1,-40) [0|0] "℃"  BMU
 SG_ M2_BalanceFailure : 30|1@1+ (1,0) [0|0] ""  BMU
 SG_ M2_Tem_Min_Num : 40|3@1+ (1,0) [0|0] ""  BMU
 SG_ M2_Tem_Max_Num : 32|3@1+ (1,0) [0|0] ""  BMU
 SG_ M2_CellVoltageMin_Num : 43|5@1+ (1,0) [0|31] ""  BMU
 SG_ M2_CellVoltageMax_Num : 35|5@1+ (1,0) [0|31] ""  BMU
 SG_ M2_JumperTemp_Max_Valid m1 : 63|1@1+ (1,0) [0|0] ""  BMU
 SG_ M2_BalanceTemp_Max_Valid m0 : 63|1@1+ (1,0) [0|0] ""  BMU
 SG_ M2_Temp_Choice M : 59|4@1+ (1,0) [0|0] ""  BMU
 SG_ M2_Tem_Mean_Valid : 31|1@1+ (1,0) [0|0] ""  BMU
 SG_ M2_CellVoltageMean_Valid : 15|1@1+ (1,0) [0|0] ""  BMU
 SG_ M2_Tem_Mean : 16|11@1+ (0.1,-40) [0|0] "℃"  BMU
 SG_ M2_CellVoltageMean : 0|15@1- (0.001,0) [0|0] "V"  BMU

BO_ 284 Lecu1MsgK: 8 Vector__XXX
 SG_ M1_Time_Cell10Balance : 16|16@1+ (0.5,0) [0|0] "Hour" Vector__XXX
 SG_ M1_Time_Cell11Balance : 32|16@1+ (0.5,0) [0|0] "Hour" Vector__XXX
 SG_ M1_Time_Cell12Balance : 48|16@1+ (0.5,0) [0|0] "Hour" Vector__XXX
 SG_ M1_Time_Cell9Balance : 0|16@1+ (0.5,0) [0|0] "Hour" Vector__XXX

BO_ 781 Lecu32MsgL: 8 Vector__XXX
 SG_ M32_Volt_Min_History : 16|15@1- (0.001,0) [0|0] "℃" Vector__XXX
 SG_ M32_Volt_Max_History : 0|15@1- (0.001,0) [0|0] "V" Vector__XXX
 SG_ M32_Tem_BoardMax_History : 32|11@1+ (0.1,-40) [0|0] "℃" Vector__XXX

BO_ 749 Lecu30MsgL: 8 Vector__XXX
 SG_ M30_Volt_Min_History : 16|15@1- (0.001,0) [0|0] "℃" Vector__XXX
 SG_ M30_Volt_Max_History : 0|15@1- (0.001,0) [0|0] "V" Vector__XXX
 SG_ M30_Tem_BoardMax_History : 32|11@1+ (0.1,-40) [0|0] "℃" Vector__XXX

BO_ 733 Lecu29MsgL: 8 Vector__XXX
 SG_ M29_Volt_Min_History : 16|15@1- (0.001,0) [0|0] "℃" Vector__XXX
 SG_ M29_Volt_Max_History : 0|15@1- (0.001,0) [0|0] "V" Vector__XXX
 SG_ M29_Tem_BoardMax_History : 32|11@1+ (0.1,-40) [0|0] "℃" Vector__XXX

BO_ 717 Lecu28MsgL: 8 Vector__XXX
 SG_ M28_Volt_Min_History : 16|15@1- (0.001,0) [0|0] "℃" Vector__XXX
 SG_ M28_Volt_Max_History : 0|15@1- (0.001,0) [0|0] "V" Vector__XXX
 SG_ M28_Tem_BoardMax_History : 32|11@1+ (0.1,-40) [0|0] "℃" Vector__XXX

BO_ 701 Lecu27MsgL: 8 Vector__XXX
 SG_ M27_Volt_Min_History : 16|15@1- (0.001,0) [0|0] "℃" Vector__XXX
 SG_ M27_Volt_Max_History : 0|15@1- (0.001,0) [0|0] "V" Vector__XXX
 SG_ M27_Tem_BoardMax_History : 32|11@1+ (0.1,-40) [0|0] "℃" Vector__XXX

BO_ 413 Lecu9MsgL: 8 Vector__XXX
 SG_ M9_Volt_Min_History : 16|15@1- (0.001,0) [0|0] "℃" Vector__XXX
 SG_ M9_Volt_Max_History : 0|15@1- (0.001,0) [0|0] "V" Vector__XXX
 SG_ M9_Tem_BoardMax_History : 32|11@1+ (0.1,-40) [0|0] "℃" Vector__XXX

BO_ 685 Lecu26MsgL: 8 Vector__XXX
 SG_ M26_Volt_Min_History : 16|15@1- (0.001,0) [0|0] "℃" Vector__XXX
 SG_ M26_Volt_Max_History : 0|15@1- (0.001,0) [0|0] "V" Vector__XXX
 SG_ M26_Tem_BoardMax_History : 32|11@1+ (0.1,-40) [0|0] "℃" Vector__XXX

BO_ 669 Lecu25MsgL: 8 Vector__XXX
 SG_ M25_Volt_Min_History : 16|15@1- (0.001,0) [0|0] "℃" Vector__XXX
 SG_ M25_Volt_Max_History : 0|15@1- (0.001,0) [0|0] "V" Vector__XXX
 SG_ M25_Tem_BoardMax_History : 32|11@1+ (0.1,-40) [0|0] "℃" Vector__XXX

BO_ 653 Lecu24MsgL: 8 Vector__XXX
 SG_ M24_Volt_Min_History : 16|15@1- (0.001,0) [0|0] "℃" Vector__XXX
 SG_ M24_Volt_Max_History : 0|15@1- (0.001,0) [0|0] "V" Vector__XXX
 SG_ M24_Tem_BoardMax_History : 32|11@1+ (0.1,-40) [0|0] "℃" Vector__XXX

BO_ 637 Lecu23MsgL: 8 Vector__XXX
 SG_ M23_Volt_Min_History : 16|15@1- (0.001,0) [0|0] "℃" Vector__XXX
 SG_ M23_Volt_Max_History : 0|15@1- (0.001,0) [0|0] "V" Vector__XXX
 SG_ M23_Tem_BoardMax_History : 32|11@1+ (0.1,-40) [0|0] "℃" Vector__XXX

BO_ 621 Lecu22MsgL: 8 Vector__XXX
 SG_ M22_Volt_Min_History : 16|15@1- (0.001,0) [0|0] "℃" Vector__XXX
 SG_ M22_Volt_Max_History : 0|15@1- (0.001,0) [0|0] "V" Vector__XXX
 SG_ M22_Tem_BoardMax_History : 32|11@1+ (0.1,-40) [0|0] "℃" Vector__XXX

BO_ 605 Lecu21MsgL: 8 Vector__XXX
 SG_ M21_Volt_Min_History : 16|15@1- (0.001,0) [0|0] "℃" Vector__XXX
 SG_ M21_Volt_Max_History : 0|15@1- (0.001,0) [0|0] "V" Vector__XXX
 SG_ M21_Tem_BoardMax_History : 32|11@1+ (0.1,-40) [0|0] "℃" Vector__XXX

BO_ 589 Lecu20MsgL: 8 Vector__XXX
 SG_ M20_Volt_Min_History : 16|15@1- (0.001,0) [0|0] "℃" Vector__XXX
 SG_ M20_Volt_Max_History : 0|15@1- (0.001,0) [0|0] "V" Vector__XXX
 SG_ M20_Tem_BoardMax_History : 32|11@1+ (0.1,-40) [0|0] "℃" Vector__XXX

BO_ 573 Lecu19MsgL: 8 Vector__XXX
 SG_ M19_Volt_Min_History : 16|15@1- (0.001,0) [0|0] "℃" Vector__XXX
 SG_ M19_Volt_Max_History : 0|15@1- (0.001,0) [0|0] "V" Vector__XXX
 SG_ M19_Tem_BoardMax_History : 32|11@1+ (0.1,-40) [0|0] "℃" Vector__XXX

BO_ 557 Lecu18MsgL: 8 Vector__XXX
 SG_ M18_Volt_Min_History : 16|15@1- (0.001,0) [0|0] "℃" Vector__XXX
 SG_ M18_Volt_Max_History : 0|15@1- (0.001,0) [0|0] "V" Vector__XXX
 SG_ M18_Tem_BoardMax_History : 32|11@1+ (0.1,-40) [0|0] "℃" Vector__XXX

BO_ 541 Lecu17MsgL: 8 Vector__XXX
 SG_ M17_Volt_Min_History : 16|15@1- (0.001,0) [0|0] "℃" Vector__XXX
 SG_ M17_Volt_Max_History : 0|15@1- (0.001,0) [0|0] "V" Vector__XXX
 SG_ M17_Tem_BoardMax_History : 32|11@1+ (0.1,-40) [0|0] "℃" Vector__XXX

BO_ 525 Lecu16MsgL: 8 Vector__XXX
 SG_ M16_Volt_Min_History : 16|15@1- (0.001,0) [0|0] "℃" Vector__XXX
 SG_ M16_Volt_Max_History : 0|15@1- (0.001,0) [0|0] "V" Vector__XXX
 SG_ M16_Tem_BoardMax_History : 32|11@1+ (0.1,-40) [0|0] "℃" Vector__XXX

BO_ 509 Lecu15MsgL: 8 Vector__XXX
 SG_ M15_Volt_Min_History : 16|15@1- (0.001,0) [0|0] "℃" Vector__XXX
 SG_ M15_Volt_Max_History : 0|15@1- (0.001,0) [0|0] "V" Vector__XXX
 SG_ M15_Tem_BoardMax_History : 32|11@1+ (0.1,-40) [0|0] "℃" Vector__XXX

BO_ 493 Lecu14MsgL: 8 Vector__XXX
 SG_ M14_Volt_Min_History : 16|15@1- (0.001,0) [0|0] "℃" Vector__XXX
 SG_ M14_Volt_Max_History : 0|15@1- (0.001,0) [0|0] "V" Vector__XXX
 SG_ M14_Tem_BoardMax_History : 32|11@1+ (0.1,-40) [0|0] "℃" Vector__XXX

BO_ 477 Lecu13MsgL: 8 Vector__XXX
 SG_ M13_Volt_Min_History : 16|15@1- (0.001,0) [0|0] "℃" Vector__XXX
 SG_ M13_Volt_Max_History : 0|15@1- (0.001,0) [0|0] "V" Vector__XXX
 SG_ M13_Tem_BoardMax_History : 32|11@1+ (0.1,-40) [0|0] "℃" Vector__XXX

BO_ 461 Lecu12MsgL: 8 Vector__XXX
 SG_ M12_Volt_Min_History : 16|15@1- (0.001,0) [0|0] "℃" Vector__XXX
 SG_ M12_Volt_Max_History : 0|15@1- (0.001,0) [0|0] "V" Vector__XXX
 SG_ M12_Tem_BoardMax_History : 32|11@1+ (0.1,-40) [0|0] "℃" Vector__XXX

BO_ 445 Lecu11MsgL: 8 Vector__XXX
 SG_ M11_Volt_Min_History : 16|15@1- (0.001,0) [0|0] "℃" Vector__XXX
 SG_ M11_Volt_Max_History : 0|15@1- (0.001,0) [0|0] "V" Vector__XXX
 SG_ M11_Tem_BoardMax_History : 32|11@1+ (0.1,-40) [0|0] "℃" Vector__XXX

BO_ 765 Lecu31MsgL: 8 Vector__XXX
 SG_ M31_Volt_Min_History : 16|15@1- (0.001,0) [0|0] "℃" Vector__XXX
 SG_ M31_Volt_Max_History : 0|15@1- (0.001,0) [0|0] "V" Vector__XXX
 SG_ M31_Tem_BoardMax_History : 32|11@1+ (0.1,-40) [0|0] "℃" Vector__XXX

BO_ 397 Lecu8MsgL: 8 Vector__XXX
 SG_ M8_Volt_Min_History : 16|15@1- (0.001,0) [0|0] "℃" Vector__XXX
 SG_ M8_Volt_Max_History : 0|15@1- (0.001,0) [0|0] "V" Vector__XXX
 SG_ M8_Tem_BoardMax_History : 32|11@1+ (0.1,-40) [0|0] "℃" Vector__XXX

BO_ 381 Lecu7MsgL: 8 Vector__XXX
 SG_ M7_Volt_Min_History : 16|15@1- (0.001,0) [0|0] "℃" Vector__XXX
 SG_ M7_Volt_Max_History : 0|15@1- (0.001,0) [0|0] "V" Vector__XXX
 SG_ M7_Tem_BoardMax_History : 32|11@1+ (0.1,-40) [0|0] "℃" Vector__XXX

BO_ 365 Lecu6MsgL: 8 Vector__XXX
 SG_ M6_Volt_Min_History : 16|15@1- (0.001,0) [0|0] "℃" Vector__XXX
 SG_ M6_Volt_Max_History : 0|15@1- (0.001,0) [0|0] "V" Vector__XXX
 SG_ M6_Tem_BoardMax_History : 32|11@1+ (0.1,-40) [0|0] "℃" Vector__XXX

BO_ 349 Lecu5MsgL: 8 Vector__XXX
 SG_ M5_Volt_Min_History : 16|15@1- (0.001,0) [0|0] "℃" Vector__XXX
 SG_ M5_Volt_Max_History : 0|15@1- (0.001,0) [0|0] "V" Vector__XXX
 SG_ M5_Tem_BoardMax_History : 32|11@1+ (0.1,-40) [0|0] "℃" Vector__XXX

BO_ 333 Lecu4MsgL: 8 Vector__XXX
 SG_ M4_Volt_Min_History : 16|15@1- (0.001,0) [0|0] "℃" Vector__XXX
 SG_ M4_Volt_Max_History : 0|15@1- (0.001,0) [0|0] "V" Vector__XXX
 SG_ M4_Tem_BoardMax_History : 32|11@1+ (0.1,-40) [0|0] "℃" Vector__XXX

BO_ 317 Lecu3MsgL: 8 Vector__XXX
 SG_ M3_Volt_Min_History : 16|15@1- (0.001,0) [0|0] "℃" Vector__XXX
 SG_ M3_Volt_Max_History : 0|15@1- (0.001,0) [0|0] "V" Vector__XXX
 SG_ M3_Tem_BoardMax_History : 32|11@1+ (0.1,-40) [0|0] "℃" Vector__XXX

BO_ 301 Lecu2MsgL: 8 Vector__XXX
 SG_ M2_Volt_Min_History : 16|15@1- (0.001,0) [0|0] "℃" Vector__XXX
 SG_ M2_Volt_Max_History : 0|15@1- (0.001,0) [0|0] "V" Vector__XXX
 SG_ M2_Tem_BoardMax_History : 32|11@1+ (0.1,-40) [0|0] "℃" Vector__XXX

BO_ 285 Lecu1MsgL: 8 Vector__XXX
 SG_ M1_Volt_Min_History : 16|15@1- (0.001,0) [0|0] "℃" Vector__XXX
 SG_ M1_Volt_Max_History : 0|15@1- (0.001,0) [0|0] "V" Vector__XXX
 SG_ M1_Tem_BoardMax_History : 32|11@1+ (0.1,-40) [0|0] "℃" Vector__XXX

BO_ 429 Lecu10MsgL: 8 Vector__XXX
 SG_ M10_Volt_Min_History : 16|15@1- (0.001,0) [0|0] "℃" Vector__XXX
 SG_ M10_Volt_Max_History : 0|15@1- (0.001,0) [0|0] "V" Vector__XXX
 SG_ M10_Tem_BoardMax_History : 32|11@1+ (0.1,-40) [0|0] "℃" Vector__XXX

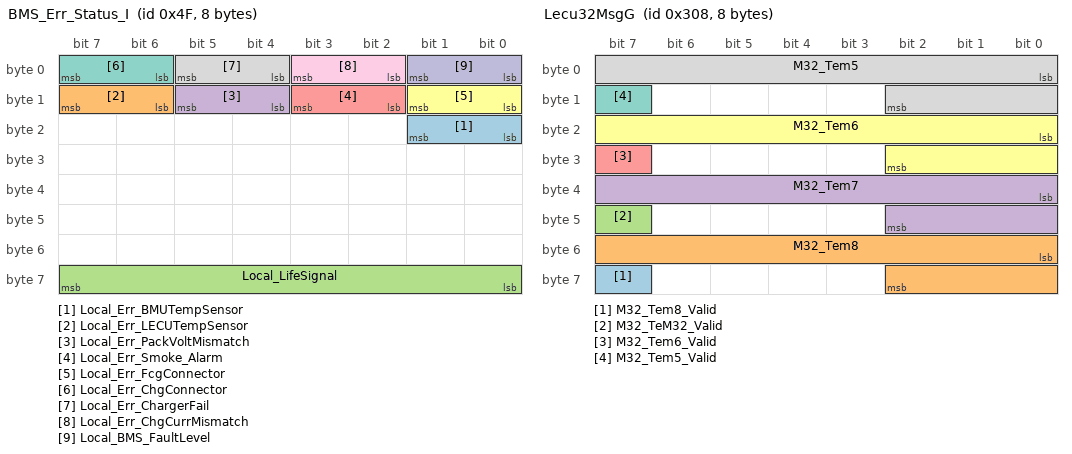
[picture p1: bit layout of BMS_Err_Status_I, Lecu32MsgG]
BO_ 79 BMS_Err_Status_I: 8 BMU
 SG_ Local_Err_BMUTempSensor : 17|2@0+ (1,0) [0|0] "" Vector__XXX
 SG_ Local_Err_LECUTempSensor : 15|2@0+ (1,0) [0|0] "" Vector__XXX
 SG_ Local_LifeSignal : 63|8@0+ (1,0) [0|0] "" Vector__XXX
 SG_ Local_Err_PackVoltMismatch : 13|2@0+ (1,0) [0|0] "" Vector__XXX
 SG_ Local_Err_Smoke_Alarm : 11|2@0+ (1,0) [0|0] "" Vector__XXX
 SG_ Local_Err_FcgConnector : 9|2@0+ (1,0) [0|0] "" Vector__XXX
 SG_ Local_Err_ChgConnector : 7|2@0+ (1,0) [0|0] "" Vector__XXX
 SG_ Local_Err_ChargerFail : 5|2@0+ (1,0) [0|0] "" Vector__XXX
 SG_ Local_Err_ChgCurrMismatch : 3|2@0+ (1,0) [0|0] "" Vector__XXX
 SG_ Local_BMS_FaultLevel : 1|2@0+ (1,0) [0|0] "" Vector__XXX

BO_ 1791 Local_CalibFrame_Msg: 8 Vector__XXX
 SG_ Calib_Volt_NewId_Num : 47|24@0+ (1,0) [0|16777215] "" Vector__XXX
 SG_ Calib_Tem_Num : 39|8@0+ (1,0) [0|0] "" Vector__XXX
 SG_ Calib_LecuId : 31|8@0+ (1,0) [0|0] "" Vector__XXX
 SG_ Calib_Type_CMD : 23|8@0+ (1,0) [0|0] "" Vector__XXX
 SG_ Calib_Volt_ID_CMD : 8|8@1+ (1,0) [0|0] "" Vector__XXX
 SG_ Calib_Default_CMD : 7|8@0+ (1,0) [0|0] "" Vector__XXX

BO_ 257 Local_BalanceControl_Msg: 8 BMU
 SG_ Local_Volt_StopChgBalance : 52|12@1+ (0.01,0) [0|0] "V" Vector__XXX
 SG_ Local_Volt_StartChgBalance : 40|12@1+ (0.01,0) [0|0] "V" Vector__XXX
 SG_ Local_Time_Balance : 24|16@1+ (1,0) [0|0] "Min" Vector__XXX
 SG_ Local_Volt_CellBalance : 0|15@1+ (0.001,0) [0|0] "V" Vector__XXX
 SG_ Local_InnerControl_Balance : 16|1@1+ (1,0) [0|0] "" Vector__XXX

BO_ 90 BMS_Frame0A: 8 BMU
 SG_ Local_Curr_ChgLimit : 7|10@0+ (1,0) [0|0] "A" Vector__XXX
 SG_ Local_Power_DchLimit : 39|12@0+ (0.1,0) [0|0] "kW" Vector__XXX
 SG_ Local_Curr_DchLimit : 13|10@0+ (1,0) [0|0] "A" Vector__XXX
 SG_ Local_Power_ChgLimit : 19|12@0+ (0.1,0) [0|0] "kW" Vector__XXX

BO_ 777 Lecu32MsgH: 8 Vector__XXX
 SG_ Lecu_Version3 : 63|8@0+ (1,0) [0|0] "" Vector__XXX
 SG_ Lecu_Version2 : 55|8@0+ (1,0) [0|0] "" Vector__XXX
 SG_ Lecu_Version1 : 47|8@0+ (1,0) [0|0] "" Vector__XXX
 SG_ Lecu_Version0 : 39|8@0+ (1,0) [0|0] "" Vector__XXX
 SG_ M32_CellBalance24 : 23|1@1+ (1,0) [0|0] "" Vector__XXX
 SG_ M32_CellBalance23 : 22|1@1+ (1,0) [0|0] "" Vector__XXX
 SG_ M32_CellBalance22 : 21|1@1+ (1,0) [0|0] "" Vector__XXX
 SG_ M32_CellBalance21 : 20|1@1+ (1,0) [0|0] "" Vector__XXX
 SG_ M32_CellBalance20 : 19|1@1+ (1,0) [0|0] "" Vector__XXX
 SG_ M32_CellBalance19 : 18|1@1+ (1,0) [0|0] "" Vector__XXX
 SG_ M32_CellBalance18 : 17|1@1+ (1,0) [0|0] "" Vector__XXX
 SG_ M32_CellBalance17 : 16|1@1+ (1,0) [0|0] "" Vector__XXX
 SG_ M32_CellBalance16 : 15|1@1+ (1,0) [0|0] "" Vector__XXX
 SG_ M32_CellBalance15 : 14|1@1+ (1,0) [0|0] "" Vector__XXX
 SG_ M32_CellBalance14 : 13|1@1+ (1,0) [0|0] "" Vector__XXX
 SG_ M32_CellBalance13 : 12|1@1+ (1,0) [0|0] "" Vector__XXX
 SG_ M32_CellBalance9 : 8|1@1+ (1,0) [0|0] "" Vector__XXX
 SG_ M32_CellBalance8 : 7|1@1+ (1,0) [0|0] "" Vector__XXX
 SG_ M32_CellBalance7 : 6|1@1+ (1,0) [0|0] "" Vector__XXX
 SG_ M32_CellBalance6 : 5|1@1+ (1,0) [0|0] "" Vector__XXX
 SG_ M32_CellBalance5 : 4|1@1+ (1,0) [0|0] "" Vector__XXX
 SG_ M32_CellBalance4 : 3|1@1+ (1,0) [0|0] "" Vector__XXX
 SG_ M32_CellBalance3 : 2|1@1+ (1,0) [0|0] "" Vector__XXX
 SG_ M32_CellBalance2 : 1|1@1+ (1,0) [0|0] "" Vector__XXX
 SG_ M32_CellBalance12 : 11|1@1+ (1,0) [0|0] "" Vector__XXX
 SG_ M32_CellBalance11 : 10|1@1+ (1,0) [0|0] "" Vector__XXX
 SG_ M32_CellBalance10 : 9|1@1+ (1,0) [0|0] "" Vector__XXX
 SG_ M32_CellBalance1 : 0|1@1+ (1,0) [0|0] "" Vector__XXX

BO_ 776 Lecu32MsgG: 8 Vector__XXX
 SG_ M32_Tem8_Valid : 63|1@1+ (1,0) [0|0] "" Vector__XXX
 SG_ M32_Tem8 : 48|11@1+ (0.1,-40) [0|0] "" Vector__XXX
 SG_ M32_TeM32_Valid : 47|1@1+ (1,0) [0|0] "" Vector__XXX
 SG_ M32_Tem7 : 32|11@1+ (0.1,-40) [0|0] "" Vector__XXX
 SG_ M32_Tem6_Valid : 31|1@1+ (1,0) [0|0] "" Vector__XXX
 SG_ M32_Tem6 : 16|11@1+ (0.1,-40) [0|0] "" Vector__XXX
 SG_ M32_Tem5_Valid : 15|1@1+ (1,0) [0|0] "" Vector__XXX
 SG_ M32_Tem5 : 0|11@1+ (0.1,-40) [0|0] "" Vector__XXX

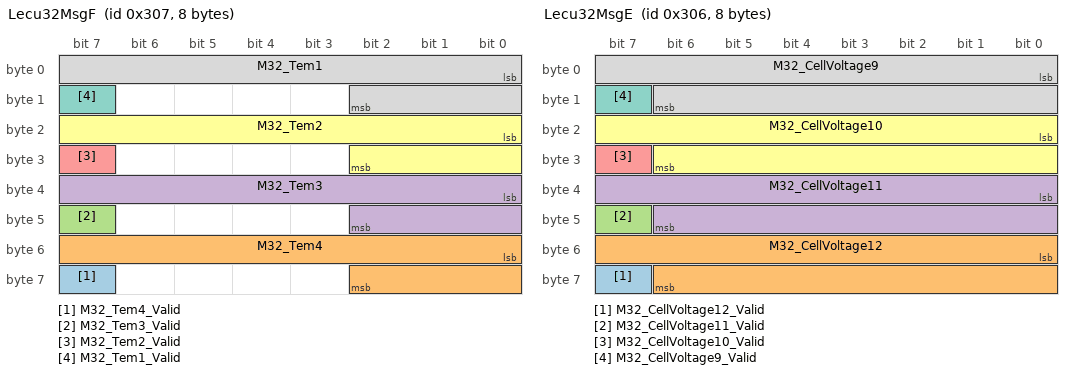
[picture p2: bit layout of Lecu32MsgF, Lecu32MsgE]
BO_ 775 Lecu32MsgF: 8 Vector__XXX
 SG_ M32_Tem4_Valid : 63|1@1+ (1,0) [0|0] "" Vector__XXX
 SG_ M32_Tem4 : 48|11@1+ (0.1,-40) [0|0] "" Vector__XXX
 SG_ M32_Tem3_Valid : 47|1@1+ (1,0) [0|0] "" Vector__XXX
 SG_ M32_Tem3 : 32|11@1+ (0.1,-40) [0|0] "" Vector__XXX
 SG_ M32_Tem2_Valid : 31|1@1+ (1,0) [0|0] "" Vector__XXX
 SG_ M32_Tem2 : 16|11@1+ (0.1,-40) [0|0] "" Vector__XXX
 SG_ M32_Tem1_Valid : 15|1@1+ (1,0) [0|0] "" Vector__XXX
 SG_ M32_Tem1 : 0|11@1+ (0.1,-40) [0|0] "" Vector__XXX

BO_ 774 Lecu32MsgE: 8 Vector__XXX
 SG_ M32_CellVoltage12_Valid : 63|1@1+ (1,0) [0|0] "" Vector__XXX
 SG_ M32_CellVoltage12 : 48|15@1- (0.001,0) [0|0] "" Vector__XXX
 SG_ M32_CellVoltage11_Valid : 47|1@1+ (1,0) [0|0] "" Vector__XXX
 SG_ M32_CellVoltage11 : 32|15@1- (0.001,0) [0|0] "" Vector__XXX
 SG_ M32_CellVoltage10_Valid : 31|1@1+ (1,0) [0|0] "" Vector__XXX
 SG_ M32_CellVoltage10 : 16|15@1- (0.001,0) [0|0] "" Vector__XXX
 SG_ M32_CellVoltage9_Valid : 15|1@1+ (1,0) [0|0] "" Vector__XXX
 SG_ M32_CellVoltage9 : 0|15@1- (0.001,0) [0|0] "" Vector__XXX

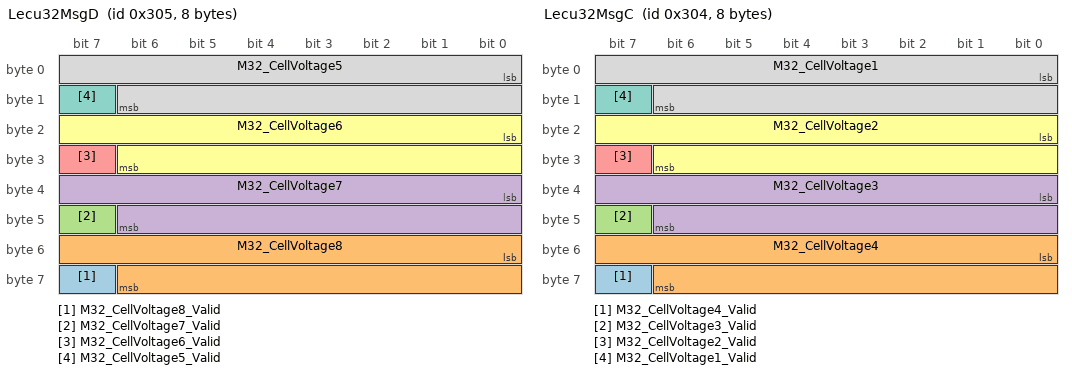
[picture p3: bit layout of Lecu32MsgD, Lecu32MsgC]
BO_ 773 Lecu32MsgD: 8 Vector__XXX
 SG_ M32_CellVoltage8_Valid : 63|1@1+ (1,0) [0|0] "" Vector__XXX
 SG_ M32_CellVoltage8 : 48|15@1- (0.001,0) [0|0] "" Vector__XXX
 SG_ M32_CellVoltage7_Valid : 47|1@1+ (1,0) [0|0] "" Vector__XXX
 SG_ M32_CellVoltage7 : 32|15@1- (0.001,0) [0|0] "" Vector__XXX
 SG_ M32_CellVoltage6_Valid : 31|1@1+ (1,0) [0|0] "" Vector__XXX
 SG_ M32_CellVoltage6 : 16|15@1- (0.001,0) [0|0] "" Vector__XXX
 SG_ M32_CellVoltage5_Valid : 15|1@1+ (1,0) [0|0] "" Vector__XXX
 SG_ M32_CellVoltage5 : 0|15@1- (0.001,0) [0|0] "" Vector__XXX

BO_ 772 Lecu32MsgC: 8 Vector__XXX
 SG_ M32_CellVoltage4_Valid : 63|1@1+ (1,0) [0|0] "" Vector__XXX
 SG_ M32_CellVoltage4 : 48|15@1- (0.001,0) [0|0] "" Vector__XXX
 SG_ M32_CellVoltage3_Valid : 47|1@1+ (1,0) [0|0] "" Vector__XXX
 SG_ M32_CellVoltage3 : 32|15@1- (0.001,0) [0|0] "" Vector__XXX
 SG_ M32_CellVoltage2_Valid : 31|1@1+ (1,0) [0|0] "" Vector__XXX
 SG_ M32_CellVoltage2 : 16|15@1- (0.001,0) [0|0] "" Vector__XXX
 SG_ M32_CellVoltage1_Valid : 15|1@1+ (1,0) [0|0] "" Vector__XXX
 SG_ M32_CellVoltage1 : 0|15@1- (0.001,0) [0|0] "" Vector__XXX

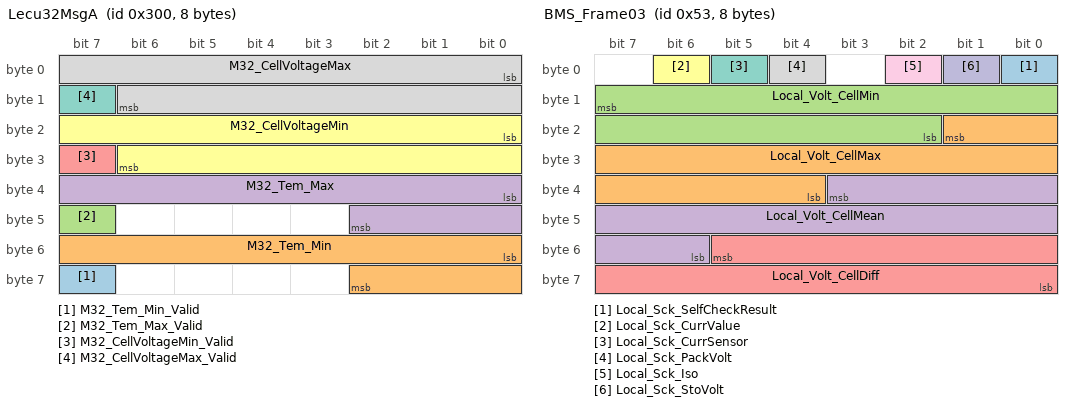
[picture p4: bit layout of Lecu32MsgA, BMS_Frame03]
BO_ 768 Lecu32MsgA: 8 LECU32
 SG_ M32_Tem_Min_Valid : 63|1@1+ (1,0) [0|0] ""  BMU
 SG_ M32_Tem_Min : 48|11@1+ (0.1,-40) [0|0] "℃"  BMU
 SG_ M32_Tem_Max_Valid : 47|1@1+ (1,0) [0|0] ""  BMU
 SG_ M32_Tem_Max : 32|11@1+ (0.1,-40) [0|0] "℃"  BMU
 SG_ M32_CellVoltageMin_Valid : 31|1@1+ (1,0) [0|0] ""  BMU
 SG_ M32_CellVoltageMin : 16|15@1- (0.001,0) [0|0] "V"  BMU
 SG_ M32_CellVoltageMax_Valid : 15|1@1+ (1,0) [0|0] ""  BMU
 SG_ M32_CellVoltageMax : 0|15@1- (0.001,0) [0|0] "V"  BMU

BO_ 95 BMS_Frame0F: 8 BMU
 SG_ Local_ModuleNum_CellVoltMax : 7|8@0+ (1,0) [0|0] "" Vector__XXX
 SG_ Local_Num_CellVoltMax : 15|8@0+ (1,0) [0|0] "" Vector__XXX
 SG_ Local_ModuleNum_CellVoltMin : 23|8@0+ (1,0) [0|0] "" Vector__XXX
 SG_ Local_Num_CellVoltMin : 31|8@0+ (1,0) [0|0] "" Vector__XXX
 SG_ Local_ModuleNum_TempMax : 39|8@0+ (1,0) [0|0] "" Vector__XXX
 SG_ Local_Num_TempMax : 47|8@0+ (1,0) [0|0] "" Vector__XXX
 SG_ Local_ModuleNum_TempMin : 55|8@0+ (1,0) [0|0] "" Vector__XXX
 SG_ Local_Num_TempMin : 63|8@0+ (1,0) [0|0] "" Vector__XXX

BO_ 5 SysFeatureSetCmd: 8 Vector__XXX
 SG_ gParaTxEnable : 31|8@0+ (1,0) [0|0] ""  BMU
 SG_ gParaReflashEnable : 23|8@0+ (1,0) [0|0] ""  BMU
 SG_ gParaModeCmd : 7|8@0+ (1,0) [0|0] ""  BMU
 SG_ gParaModeAddr : 15|8@0+ (1,0) [0|0] ""  BMU
 SG_ gParaContent : 39|32@0+ (1,0) [0|0] ""  BMU

BO_ 2 CCP_DTO_Msg: 8 BMU
 SG_ CCP_DTO_Data : 7|64@0+ (1,0) [0|0] "" Vector__XXX

BO_ 1 CCP_CRO_Msg: 8 Vector__XXX
 SG_ CCP_CRO_Data : 7|64@0+ (1,0) [0|0] ""  BMU

BO_ 6 BMS_ReqClock: 8 Vector__XXX
 SG_ Local_dClockSec : 37|6@0+ (1,0) [0|0] "S"  BMU
 SG_ Local_dClockMin : 31|6@0+ (1,0) [0|0] "Min"  BMU
 SG_ Local_dClockHour : 21|6@0+ (1,0) [0|0] "Hour"  BMU
 SG_ Local_dClockDay : 11|6@0+ (1,0) [0|0] "Day"  BMU
 SG_ Local_dClockMonth : 15|4@0+ (1,0) [0|0] "Month"  BMU
 SG_ Local_dClockYear : 7|8@0+ (1,0) [0|0] "Year"  BMU
 SG_ Local_ClockCMD : 25|4@0+ (1,0) [0|0] ""  BMU

BO_ 93 BMS_Frame0D: 8 BMU
 SG_ Local_SaveSOCFlag : 63|8@0+ (1,0) [0|0] "" Vector__XXX
 SG_ Local_K_SocAmend : 55|8@0+ (1,0) [0|0] "" Vector__XXX
 SG_ Local_Volt_FcgCC : 35|12@0+ (0.001,0) [0|4.095] "V" Vector__XXX
 SG_ Local_Volt_ChgCC : 31|12@0+ (0.001,0) [0|4.095] "V" Vector__XXX
 SG_ Local_Volt_ChgHvil : 11|12@0+ (0.001,0) [0|4.095] "V" Vector__XXX
 SG_ Local_Volt_DchHvil : 7|12@0+ (0.001,0) [0|4.095] "V" Vector__XXX

BO_ 92 BMS_Frame0C: 8 BMU
 SG_ Local_proBmuHwVersion : 7|12@0+ (0.01,0) [0|0] "" Vector__XXX
 SG_ Local_proLecuHwVersion : 11|12@0+ (0.01,0) [0|0] "" Vector__XXX
 SG_ Local_proPlatformVersion : 31|7@0+ (0.1,0) [0|0] "" Vector__XXX
 SG_ Local_proBmuSwVersion : 24|7@0+ (0.1,0) [0|0] "" Vector__XXX
 SG_ Local_proLecuSwVersion : 33|7@0+ (0.1,0) [0|0] "" Vector__XXX
 SG_ Local_proSwDesignDate : 42|19@0+ (1,0) [0|0] "" Vector__XXX

BO_ 91 BMS_Frame0B: 8 BMU
 SG_ Local_proClientCode : 7|8@0+ (1,0) [0|0] "" Vector__XXX
 SG_ Local_proProjectCode : 15|8@0+ (1,0) [0|0] "" Vector__XXX
 SG_ Local_proProjectStage : 23|8@0+ (1,0) [0|0] "" Vector__XXX
 SG_ Local_proProductSeries : 31|4@0+ (1,0) [0|0] "" Vector__XXX
 SG_ Local_LaunchYear : 47|7@0+ (1,0) [0|0] "Year" Vector__XXX
 SG_ Local_LaunchMonth : 51|4@0+ (1,0) [0|0] "Month" Vector__XXX
 SG_ Local_LaunchDay : 40|5@0+ (1,0) [0|0] "Day" Vector__XXX
 SG_ Local_LaunchNum : 27|12@0+ (1,0) [0|0] "" Vector__XXX

BO_ 89 BMS_Frame09: 8 BMU
 SG_ Local_dClockYearFeedBack : 7|8@0+ (1,0) [0|0] "Year" Vector__XXX
 SG_ Local_dClockMonthFeedBack : 15|4@0+ (1,0) [0|0] "Month" Vector__XXX
 SG_ Local_dClockDayFeedBack : 11|6@0+ (1,0) [0|0] "Day" Vector__XXX
 SG_ Local_dClockHourFeedBack : 21|6@0+ (1,0) [0|0] "Hour" Vector__XXX
 SG_ Local_dClockMinFeedBack : 31|6@0+ (1,0) [0|0] "Min" Vector__XXX
 SG_ Local_dClockSecFeedBack : 25|6@0+ (1,0) [0|0] "S" Vector__XXX

BO_ 88 BMS_Frame08: 8 BMU
 SG_ Local_CtrChk_PreConnector : 35|2@0+ (1,0) [0|0] "" Vector__XXX
 SG_ Local_CtrChk_NegConnector : 33|2@0+ (1,0) [0|0] "" Vector__XXX
 SG_ Local_CtrChk_FcgConnector : 37|2@0+ (1,0) [0|0] "" Vector__XXX
 SG_ Local_CtrChk_ChgConnector : 39|2@0+ (1,0) [0|0] "" Vector__XXX
 SG_ Local_CtrChk_PosConnector : 31|2@0+ (1,0) [0|0] "" Vector__XXX
 SG_ Local_CtrFb_HVIL_Dch : 46|1@0+ (1,0) [0|0] "" Vector__XXX
 SG_ Local_CtrFb_HVIL_Chg : 47|1@0+ (1,0) [0|0] "" Vector__XXX
 SG_ Local_Ctr_IsoPosAd : 26|1@0+ (1,0) [0|0] "" Vector__XXX
 SG_ Local_Ctr_IsoNegAd : 27|1@0+ (1,0) [0|0] "" Vector__XXX
 SG_ Local_Ctr_HVILVcc : 28|1@0+ (1,0) [0|0] "" Vector__XXX
 SG_ Local_CtrFb_PWMOut_L1 : 43|1@0+ (1,0) [0|0] "" Vector__XXX
 SG_ Local_CtrFb_PowerL2 : 42|1@0+ (1,0) [0|0] "" Vector__XXX
 SG_ Local_CtrFb_PowerL1 : 41|1@0+ (1,0) [0|0] "" Vector__XXX
 SG_ Local_CtrFb_Output_L1 : 45|1@0+ (1,0) [0|0] "" Vector__XXX
 SG_ Local_CtrFb_Output_H1 : 44|1@0+ (1,0) [0|0] "" Vector__XXX
 SG_ Local_Ctr_PWMOut_L1 : 23|1@0+ (1,0) [0|0] "" Vector__XXX
 SG_ Local_OlStatus_VCU : 54|1@0+ (1,0) [0|0] "" Vector__XXX
 SG_ Local_Ctr_PowerL2 : 19|1@0+ (1,0) [0|0] "" Vector__XXX
 SG_ Local_Ctr_ChgConnector : 16|1@0+ (1,0) [0|0] "" Vector__XXX
 SG_ Local_OlStatus_IVT : 50|1@0+ (1,0) [0|0] "" Vector__XXX
 SG_ Local_KeyMode : 10|3@0+ (1,0) [0|0] "" Vector__XXX
 SG_ Local_OlStatus_LECU : 52|1@0+ (1,0) [0|0] "" Vector__XXX
 SG_ Local_OlStatus_Insulation : 51|1@0+ (1,0) [0|0] "" Vector__XXX
 SG_ Local_OlStatus_Fcg : 53|1@0+ (1,0) [0|0] "" Vector__XXX
 SG_ Local_Curr_ChgRequest : 49|10@0+ (1,0) [0|0] "A" Vector__XXX
 SG_ Local_Status_BMS : 7|8@0+ (1,0) [0|0] "" Vector__XXX
 SG_ Local_CtrFb_LecuPower : 40|1@0+ (1,0) [0|0] "" Vector__XXX
 SG_ Local_Ctr_FcgConnector : 13|1@0+ (1,0) [0|0] "" Vector__XXX
 SG_ Local_Ctr_PreChgConnector : 12|1@0+ (1,0) [0|0] "" Vector__XXX
 SG_ Local_Ctr_NegConnector : 15|1@0+ (1,0) [0|0] "" Vector__XXX
 SG_ Local_Ctr_PosConnector : 14|1@0+ (1,0) [0|0] "" Vector__XXX
 SG_ Local_Ctr_HvpAd : 21|1@0+ (1,0) [0|0] "" Vector__XXX
 SG_ Local_Ctr_HvbAd : 22|1@0+ (1,0) [0|0] "" Vector__XXX
 SG_ Local_Ctr_PowerLock : 17|1@0+ (1,0) [0|0] "" Vector__XXX
 SG_ Local_Ctr_LecuPower : 11|1@0+ (1,0) [0|0] "" Vector__XXX
 SG_ Local_Ctr_Output_L1 : 25|1@0+ (1,0) [0|0] "" Vector__XXX
 SG_ Local_Ctr_PowerL1 : 18|1@0+ (1,0) [0|0] "" Vector__XXX
 SG_ Local_Ctr_Output_H1 : 24|1@0+ (1,0) [0|0] "" Vector__XXX
 SG_ Local_Ctr_FQPower : 20|1@0+ (1,0) [0|0] "" Vector__XXX

BO_ 87 BMS_Frame07: 8 BMU
 SG_ Local_Cap_Real : 7|16@0+ (0.01,0) [0|0] "AH" Vector__XXX
 SG_ Local_Cap_SOH : 23|16@0+ (0.01,0) [0|0] "AH" Vector__XXX
 SG_ Local_Cap_Design : 39|16@0+ (0.01,0) [0|0] "AH" Vector__XXX
 SG_ Local_Time_TotalRun : 55|16@0+ (1,0) [0|0] "h" Vector__XXX

BO_ 86 BMS_Frame06: 8 BMU
 SG_ Local_SOC : 7|10@0+ (0.1,0) [0|0] "%" Vector__XXX
 SG_ Local_Integ_SOC : 13|10@0+ (0.1,0) [0|0] "%" Vector__XXX
 SG_ Local_PosCtr_WithLoad_CTR : 31|16@0+ (0.01,0) [0|0] "AH" Vector__XXX
 SG_ Local_FcgCtr_WithLoad_CTR : 47|16@0+ (1,0) [0|0] "Min" Vector__XXX

BO_ 85 BMS_Frame05: 8 BMU
 SG_ Local_Curr_ChgMaxPermit : 7|10@0+ (1,0) [0|0] "A" Vector__XXX
 SG_ Local_Curr_DchMaxPermit : 13|10@0+ (1,0) [0|0] "A" Vector__XXX
 SG_ Local_Cap_RecentCharge : 19|10@0+ (1,0) [0|0] "Ah" Vector__XXX
 SG_ Local_Cap_RecentDischg : 25|10@0+ (1,0) [0|0] "Ah" Vector__XXX
 SG_ Local_DcA : 47|12@0+ (1,0) [0|0] "" Vector__XXX
 SG_ Local_ChA : 51|12@0+ (1,0) [0|0] "" Vector__XXX

BO_ 84 BMS_Frame04: 8 BMU
 SG_ Local_Temp_IVT : 55|16@0+ (0.1,-40) [0|0] "℃" Vector__XXX
 SG_ Local_Temp_CellMax : 7|12@0+ (0.1,-40) [0|0] "℃" Vector__XXX
 SG_ Local_Temp_CellMin : 11|12@0+ (0.1,-40) [0|0] "℃" Vector__XXX
 SG_ Local_Temp_CellMean : 31|12@0+ (0.1,-40) [0|0] "℃" Vector__XXX
 SG_ Local_Temp_CellDiff : 35|12@0+ (0.1,0) [0|0] "℃" Vector__XXX

BO_ 83 BMS_Frame03: 8 BMU
 SG_ Local_Sck_SelfCheckResult : 0|1@0+ (1,0) [0|0] "" Vector__XXX
 SG_ Local_Volt_CellMax : 17|14@0+ (0.001,0) [0|0] "V" Vector__XXX
 SG_ Local_Volt_CellMin : 15|14@0+ (0.001,0) [0|0] "V" Vector__XXX
 SG_ Local_Volt_CellMean : 35|14@0+ (0.001,0) [0|0] "V" Vector__XXX
 SG_ Local_Volt_CellDiff : 53|14@0+ (0.001,0) [0|0] "V" Vector__XXX
 SG_ Local_Sck_CurrValue : 6|1@0+ (1,0) [0|0] "" Vector__XXX
 SG_ Local_Sck_CurrSensor : 5|1@0+ (1,0) [0|0] "" Vector__XXX
 SG_ Local_Sck_PackVolt : 4|1@0+ (1,0) [0|0] "" Vector__XXX
 SG_ Local_Sck_Iso : 2|1@0+ (1,0) [0|0] "" Vector__XXX
 SG_ Local_Sck_StoVolt : 1|1@0+ (1,0) [0|0] "" Vector__XXX

BO_ 82 BMS_Frame02: 8 BMU
 SG_ Local_Powersaveflag : 16|1@0+ (1,0) [0|0] "" Vector__XXX
 SG_ Local_Energy_Bat : 7|16@0+ (1,0) [0|0] "kwh" Vector__XXX
 SG_ Local_EnergyBatChargeSingle : 31|8@0+ (1,0) [0|0] "kwh" Vector__XXX
 SG_ Local_Temp_Amb2 : 63|8@0+ (1,-40) [0|0] "℃" Vector__XXX
 SG_ Local_Temp_Amb1 : 55|8@0+ (1,-40) [0|0] "℃" Vector__XXX
 SG_ Local_Res_Isolation : 39|16@0+ (1,0) [0|0] "KΩ" Vector__XXX

BO_ 81 BMS_Frame01: 8 BMU
 SG_ Local_Volt_Bat : 7|16@0+ (0.1,0) [0|0] "V" Vector__XXX
 SG_ Local_Volt_Bus : 23|16@0+ (0.1,0) [0|0] "V" Vector__XXX
 SG_ Local_Volt_Sto : 39|16@0+ (0.01,0) [0|0] "V" Vector__XXX
 SG_ Local_Curr_Bus : 55|16@0+ (0.1,-3200) [0|0] "A" Vector__XXX

BO_ 80 BMS_Err_Status_II: 8 BMU
 SG_ Local_Err_TimeSequence : 55|2@0+ (1,0) [0|0] "" Vector__XXX
 SG_ Local_Err_InertiaSwitchFail : 49|2@0+ (1,0) [0|0] "" Vector__XXX
 SG_ Local_Err_Hvil_B : 47|2@0+ (1,0) [0|0] "" Vector__XXX
 SG_ Local_Err_IVTTempHigh : 29|2@0+ (1,0) [0|0] "" Vector__XXX
 SG_ Local_Err_JumperTempHigh : 27|2@0+ (1,0) [0|0] "" Vector__XXX
 SG_ Local_Err_StoVolt : 25|2@0+ (1,0) [0|0] "" Vector__XXX
 SG_ Local_Err_LECU6803 : 63|2@0+ (1,0) [0|0] "" Vector__XXX
 SG_ Local_Err_VcuIsoLow : 33|2@0+ (1,0) [0|0] "" Vector__XXX
 SG_ Local_Err_ChgCANLost : 35|2@0+ (1,0) [0|0] "" Vector__XXX
 SG_ Local_Err_BalanceFail : 61|2@0+ (1,0) [0|0] "" Vector__XXX
 SG_ Local_Err_SelfcheckFail : 59|2@0+ (1,0) [0|0] "" Vector__XXX
 SG_ Local_Err_PreChargeFail : 43|2@0+ (1,0) [0|0] "" Vector__XXX
 SG_ Local_Err_PackVoltLow : 15|2@0+ (1,0) [0|0] "" Vector__XXX
 SG_ Local_Err_PackVoltHigh : 13|2@0+ (1,0) [0|0] "" Vector__XXX
 SG_ Local_Err_PackSOCLow : 23|2@0+ (1,0) [0|0] "" Vector__XXX
 SG_ Local_Err_PackIsoLow : 17|2@0+ (1,0) [0|0] "" Vector__XXX
 SG_ Local_Err_LocalCANFail : 31|2@0+ (1,0) [0|0] "" Vector__XXX
 SG_ Local_Err_DchCurrHigh : 11|2@0+ (1,0) [0|0] "" Vector__XXX
 SG_ Local_Err_ChgCurrHigh : 9|2@0+ (1,0) [0|0] "" Vector__XXX
 SG_ Local_Err_CellVoltLow : 7|2@0+ (1,0) [0|0] "" Vector__XXX
 SG_ Local_Err_CellVoltHigh : 5|2@0+ (1,0) [0|0] "" Vector__XXX
 SG_ Local_Err_CellTempLow : 3|2@0+ (1,0) [0|0] "" Vector__XXX
 SG_ Local_Err_CellTempHigh : 1|2@0+ (1,0) [0|0] "" Vector__XXX
 SG_ Local_Err_CellTempDiff : 21|2@0+ (1,0) [0|0] "" Vector__XXX
 SG_ Local_Err_RelayWeld : 51|2@0+ (1,0) [0|0] "" Vector__XXX
 SG_ Local_Err_PatternChaos : 53|2@0+ (1,0) [0|0] "" Vector__XXX
 SG_ Local_Err_IsoCANLost : 39|2@0+ (1,0) [0|0] "" Vector__XXX
 SG_ Local_Err_CurrSensorLost : 41|2@0+ (1,0) [0|0] "" Vector__XXX
 SG_ Local_Err_FcgCANLost : 37|2@0+ (1,0) [0|0] "" Vector__XXX
 SG_ Local_Err_CellVoltDiff : 19|2@0+ (1,0) [0|0] "" Vector__XXX
 SG_ Local_Err_Hvil_A : 45|2@0+ (1,0) [0|0] "" Vector__XXX
 SG_ Local_Err_SOP : 57|2@0+ (1,0) [0|0] "" Vector__XXX

BO_ 521 Lecu16MsgH: 8 Vector__XXX
 SG_ Lecu_Version3 : 63|8@0+ (1,0) [0|0] "" Vector__XXX
 SG_ Lecu_Version2 : 55|8@0+ (1,0) [0|0] "" Vector__XXX
 SG_ Lecu_Version1 : 47|8@0+ (1,0) [0|0] "" Vector__XXX
 SG_ Lecu_Version0 : 39|8@0+ (1,0) [0|0] "" Vector__XXX
 SG_ M16_CellBalance24 : 23|1@1+ (1,0) [0|0] "" Vector__XXX
 SG_ M16_CellBalance23 : 22|1@1+ (1,0) [0|0] "" Vector__XXX
 SG_ M16_CellBalance22 : 21|1@1+ (1,0) [0|0] "" Vector__XXX
 SG_ M16_CellBalance21 : 20|1@1+ (1,0) [0|0] "" Vector__XXX
 SG_ M16_CellBalance20 : 19|1@1+ (1,0) [0|0] "" Vector__XXX
 SG_ M16_CellBalance19 : 18|1@1+ (1,0) [0|0] "" Vector__XXX
 SG_ M16_CellBalance18 : 17|1@1+ (1,0) [0|0] "" Vector__XXX
 SG_ M16_CellBalance17 : 16|1@1+ (1,0) [0|0] "" Vector__XXX
 SG_ M16_CellBalance16 : 15|1@1+ (1,0) [0|0] "" Vector__XXX
 SG_ M16_CellBalance15 : 14|1@1+ (1,0) [0|0] "" Vector__XXX
 SG_ M16_CellBalance14 : 13|1@1+ (1,0) [0|0] "" Vector__XXX
 SG_ M16_CellBalance13 : 12|1@1+ (1,0) [0|0] "" Vector__XXX
 SG_ M16_CellBalance9 : 8|1@1+ (1,0) [0|0] "" Vector__XXX
 SG_ M16_CellBalance8 : 7|1@1+ (1,0) [0|0] "" Vector__XXX
 SG_ M16_CellBalance7 : 6|1@1+ (1,0) [0|0] "" Vector__XXX
 SG_ M16_CellBalance6 : 5|1@1+ (1,0) [0|0] "" Vector__XXX
 SG_ M16_CellBalance5 : 4|1@1+ (1,0) [0|0] "" Vector__XXX
 SG_ M16_CellBalance4 : 3|1@1+ (1,0) [0|0] "" Vector__XXX
 SG_ M16_CellBalance3 : 2|1@1+ (1,0) [0|0] "" Vector__XXX
 SG_ M16_CellBalance2 : 1|1@1+ (1,0) [0|0] "" Vector__XXX
 SG_ M16_CellBalance12 : 11|1@1+ (1,0) [0|0] "" Vector__XXX
 SG_ M16_CellBalance11 : 10|1@1+ (1,0) [0|0] "" Vector__XXX
 SG_ M16_CellBalance10 : 9|1@1+ (1,0) [0|0] "" Vector__XXX
 SG_ M16_CellBalance1 : 0|1@1+ (1,0) [0|0] "" Vector__XXX

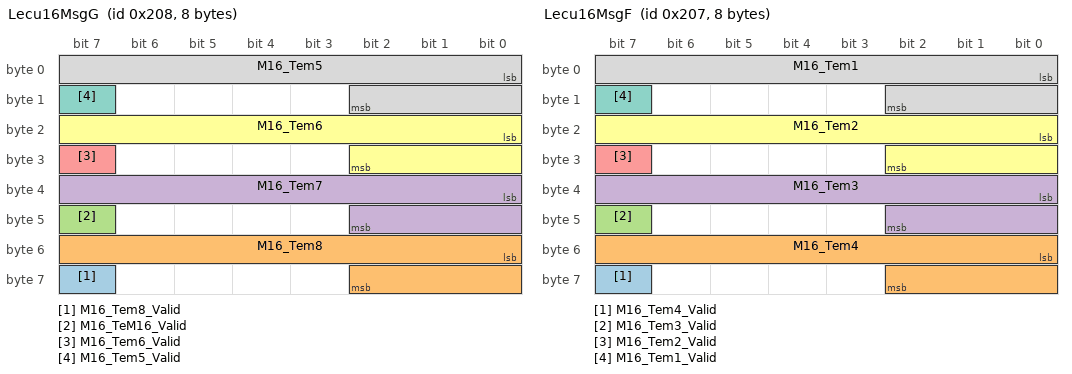
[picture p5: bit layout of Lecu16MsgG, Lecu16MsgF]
BO_ 520 Lecu16MsgG: 8 Vector__XXX
 SG_ M16_Tem8_Valid : 63|1@1+ (1,0) [0|0] "" Vector__XXX
 SG_ M16_Tem8 : 48|11@1+ (0.1,-40) [0|0] "" Vector__XXX
 SG_ M16_TeM16_Valid : 47|1@1+ (1,0) [0|0] "" Vector__XXX
 SG_ M16_Tem7 : 32|11@1+ (0.1,-40) [0|0] "" Vector__XXX
 SG_ M16_Tem6_Valid : 31|1@1+ (1,0) [0|0] "" Vector__XXX
 SG_ M16_Tem6 : 16|11@1+ (0.1,-40) [0|0] "" Vector__XXX
 SG_ M16_Tem5_Valid : 15|1@1+ (1,0) [0|0] "" Vector__XXX
 SG_ M16_Tem5 : 0|11@1+ (0.1,-40) [0|0] "" Vector__XXX

BO_ 519 Lecu16MsgF: 8 Vector__XXX
 SG_ M16_Tem4_Valid : 63|1@1+ (1,0) [0|0] "" Vector__XXX
 SG_ M16_Tem4 : 48|11@1+ (0.1,-40) [0|0] "" Vector__XXX
 SG_ M16_Tem3_Valid : 47|1@1+ (1,0) [0|0] "" Vector__XXX
 SG_ M16_Tem3 : 32|11@1+ (0.1,-40) [0|0] "" Vector__XXX
 SG_ M16_Tem2_Valid : 31|1@1+ (1,0) [0|0] "" Vector__XXX
 SG_ M16_Tem2 : 16|11@1+ (0.1,-40) [0|0] "" Vector__XXX
 SG_ M16_Tem1_Valid : 15|1@1+ (1,0) [0|0] "" Vector__XXX
 SG_ M16_Tem1 : 0|11@1+ (0.1,-40) [0|0] "" Vector__XXX

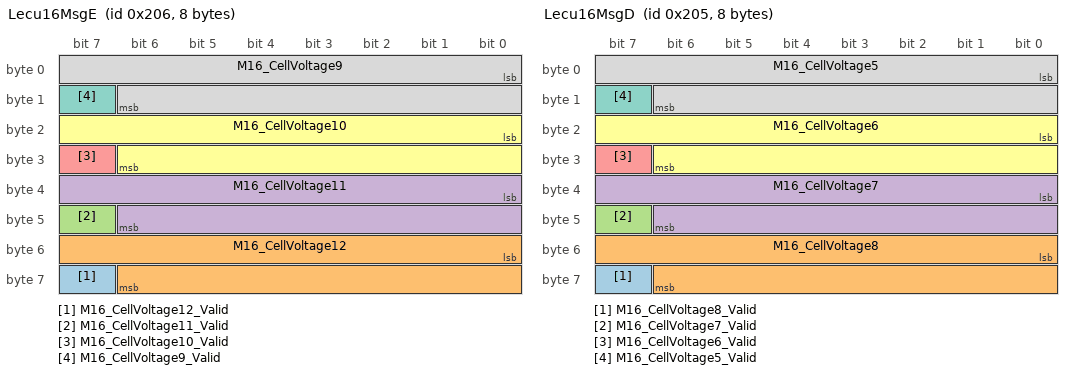
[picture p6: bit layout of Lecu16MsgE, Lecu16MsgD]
BO_ 518 Lecu16MsgE: 8 Vector__XXX
 SG_ M16_CellVoltage12_Valid : 63|1@1+ (1,0) [0|0] "" Vector__XXX
 SG_ M16_CellVoltage12 : 48|15@1- (0.001,0) [0|0] "" Vector__XXX
 SG_ M16_CellVoltage11_Valid : 47|1@1+ (1,0) [0|0] "" Vector__XXX
 SG_ M16_CellVoltage11 : 32|15@1- (0.001,0) [0|0] "" Vector__XXX
 SG_ M16_CellVoltage10_Valid : 31|1@1+ (1,0) [0|0] "" Vector__XXX
 SG_ M16_CellVoltage10 : 16|15@1- (0.001,0) [0|0] "" Vector__XXX
 SG_ M16_CellVoltage9_Valid : 15|1@1+ (1,0) [0|0] "" Vector__XXX
 SG_ M16_CellVoltage9 : 0|15@1- (0.001,0) [0|0] "" Vector__XXX

BO_ 517 Lecu16MsgD: 8 Vector__XXX
 SG_ M16_CellVoltage8_Valid : 63|1@1+ (1,0) [0|0] "" Vector__XXX
 SG_ M16_CellVoltage8 : 48|15@1- (0.001,0) [0|0] "" Vector__XXX
 SG_ M16_CellVoltage7_Valid : 47|1@1+ (1,0) [0|0] "" Vector__XXX
 SG_ M16_CellVoltage7 : 32|15@1- (0.001,0) [0|0] "" Vector__XXX
 SG_ M16_CellVoltage6_Valid : 31|1@1+ (1,0) [0|0] "" Vector__XXX
 SG_ M16_CellVoltage6 : 16|15@1- (0.001,0) [0|0] "" Vector__XXX
 SG_ M16_CellVoltage5_Valid : 15|1@1+ (1,0) [0|0] "" Vector__XXX
 SG_ M16_CellVoltage5 : 0|15@1- (0.001,0) [0|0] "" Vector__XXX

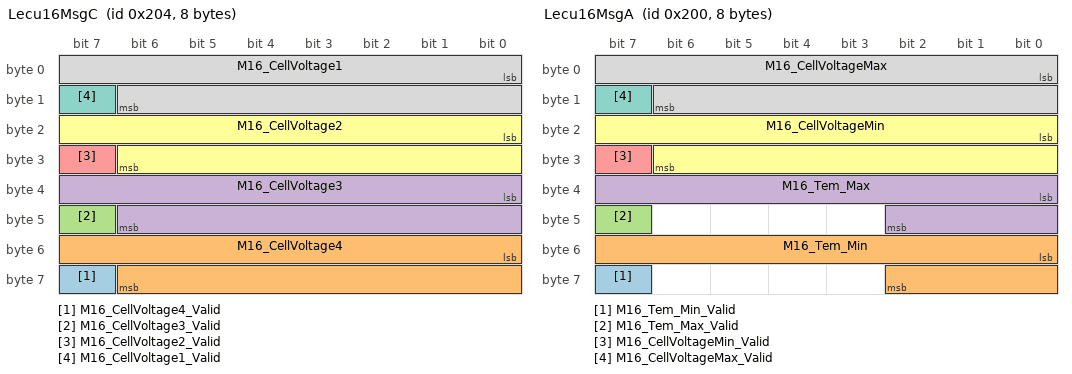
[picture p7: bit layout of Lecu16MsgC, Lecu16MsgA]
BO_ 516 Lecu16MsgC: 8 Vector__XXX
 SG_ M16_CellVoltage4_Valid : 63|1@1+ (1,0) [0|0] "" Vector__XXX
 SG_ M16_CellVoltage4 : 48|15@1- (0.001,0) [0|0] "" Vector__XXX
 SG_ M16_CellVoltage3_Valid : 47|1@1+ (1,0) [0|0] "" Vector__XXX
 SG_ M16_CellVoltage3 : 32|15@1- (0.001,0) [0|0] "" Vector__XXX
 SG_ M16_CellVoltage2_Valid : 31|1@1+ (1,0) [0|0] "" Vector__XXX
 SG_ M16_CellVoltage2 : 16|15@1- (0.001,0) [0|0] "" Vector__XXX
 SG_ M16_CellVoltage1_Valid : 15|1@1+ (1,0) [0|0] "" Vector__XXX
 SG_ M16_CellVoltage1 : 0|15@1- (0.001,0) [0|0] "" Vector__XXX

BO_ 512 Lecu16MsgA: 8 LECU16
 SG_ M16_Tem_Min_Valid : 63|1@1+ (1,0) [0|0] ""  BMU
 SG_ M16_Tem_Min : 48|11@1+ (0.1,-40) [0|0] "℃"  BMU
 SG_ M16_Tem_Max_Valid : 47|1@1+ (1,0) [0|0] ""  BMU
 SG_ M16_Tem_Max : 32|11@1+ (0.1,-40) [0|0] "℃"  BMU
 SG_ M16_CellVoltageMin_Valid : 31|1@1+ (1,0) [0|0] ""  BMU
 SG_ M16_CellVoltageMin : 16|15@1- (0.001,0) [0|0] "V"  BMU
 SG_ M16_CellVoltageMax_Valid : 15|1@1+ (1,0) [0|0] ""  BMU
 SG_ M16_CellVoltageMax : 0|15@1- (0.001,0) [0|0] "V"  BMU

BO_ 537 Lecu17MsgH: 8 Vector__XXX
 SG_ Lecu_Version3 : 63|8@0+ (1,0) [0|0] "" Vector__XXX
 SG_ Lecu_Version2 : 55|8@0+ (1,0) [0|0] "" Vector__XXX
 SG_ Lecu_Version1 : 47|8@0+ (1,0) [0|0] "" Vector__XXX
 SG_ Lecu_Version0 : 39|8@0+ (1,0) [0|0] "" Vector__XXX
 SG_ M17_CellBalance24 : 23|1@1+ (1,0) [0|0] "" Vector__XXX
 SG_ M17_CellBalance23 : 22|1@1+ (1,0) [0|0] "" Vector__XXX
 SG_ M17_CellBalance22 : 21|1@1+ (1,0) [0|0] "" Vector__XXX
 SG_ M17_CellBalance21 : 20|1@1+ (1,0) [0|0] "" Vector__XXX
 SG_ M17_CellBalance20 : 19|1@1+ (1,0) [0|0] "" Vector__XXX
 SG_ M17_CellBalance19 : 18|1@1+ (1,0) [0|0] "" Vector__XXX
 SG_ M17_CellBalance18 : 17|1@1+ (1,0) [0|0] "" Vector__XXX
 SG_ M17_CellBalance17 : 16|1@1+ (1,0) [0|0] "" Vector__XXX
 SG_ M17_CellBalance16 : 15|1@1+ (1,0) [0|0] "" Vector__XXX
 SG_ M17_CellBalance15 : 14|1@1+ (1,0) [0|0] "" Vector__XXX
 SG_ M17_CellBalance14 : 13|1@1+ (1,0) [0|0] "" Vector__XXX
 SG_ M17_CellBalance13 : 12|1@1+ (1,0) [0|0] "" Vector__XXX
 SG_ M17_CellBalance9 : 8|1@1+ (1,0) [0|0] "" Vector__XXX
 SG_ M17_CellBalance8 : 7|1@1+ (1,0) [0|0] "" Vector__XXX
 SG_ M17_CellBalance7 : 6|1@1+ (1,0) [0|0] "" Vector__XXX
 SG_ M17_CellBalance6 : 5|1@1+ (1,0) [0|0] "" Vector__XXX
 SG_ M17_CellBalance5 : 4|1@1+ (1,0) [0|0] "" Vector__XXX
 SG_ M17_CellBalance4 : 3|1@1+ (1,0) [0|0] "" Vector__XXX
 SG_ M17_CellBalance3 : 2|1@1+ (1,0) [0|0] "" Vector__XXX
 SG_ M17_CellBalance2 : 1|1@1+ (1,0) [0|0] "" Vector__XXX
 SG_ M17_CellBalance12 : 11|1@1+ (1,0) [0|0] "" Vector__XXX
 SG_ M17_CellBalance11 : 10|1@1+ (1,0) [0|0] "" Vector__XXX
 SG_ M17_CellBalance10 : 9|1@1+ (1,0) [0|0] "" Vector__XXX
 SG_ M17_CellBalance1 : 0|1@1+ (1,0) [0|0] "" Vector__XXX

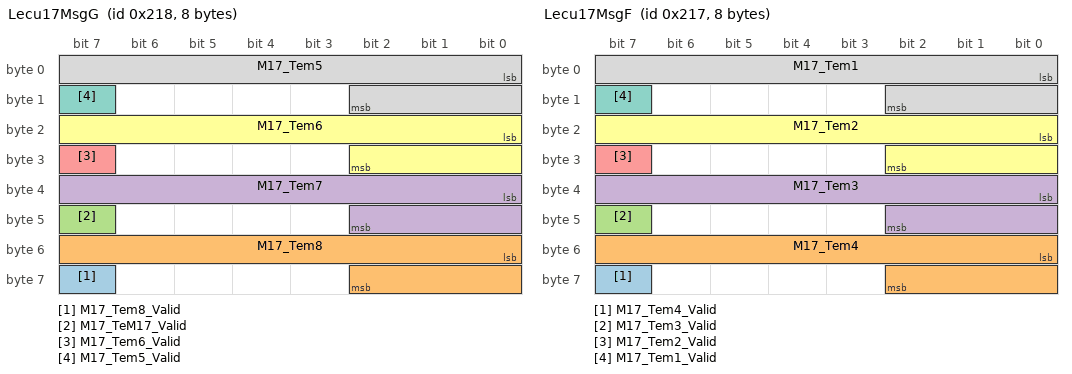
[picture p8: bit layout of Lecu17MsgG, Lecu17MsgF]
BO_ 536 Lecu17MsgG: 8 Vector__XXX
 SG_ M17_Tem8_Valid : 63|1@1+ (1,0) [0|0] "" Vector__XXX
 SG_ M17_Tem8 : 48|11@1+ (0.1,-40) [0|0] "" Vector__XXX
 SG_ M17_TeM17_Valid : 47|1@1+ (1,0) [0|0] "" Vector__XXX
 SG_ M17_Tem7 : 32|11@1+ (0.1,-40) [0|0] "" Vector__XXX
 SG_ M17_Tem6_Valid : 31|1@1+ (1,0) [0|0] "" Vector__XXX
 SG_ M17_Tem6 : 16|11@1+ (0.1,-40) [0|0] "" Vector__XXX
 SG_ M17_Tem5_Valid : 15|1@1+ (1,0) [0|0] "" Vector__XXX
 SG_ M17_Tem5 : 0|11@1+ (0.1,-40) [0|0] "" Vector__XXX

BO_ 535 Lecu17MsgF: 8 Vector__XXX
 SG_ M17_Tem4_Valid : 63|1@1+ (1,0) [0|0] "" Vector__XXX
 SG_ M17_Tem4 : 48|11@1+ (0.1,-40) [0|0] "" Vector__XXX
 SG_ M17_Tem3_Valid : 47|1@1+ (1,0) [0|0] "" Vector__XXX
 SG_ M17_Tem3 : 32|11@1+ (0.1,-40) [0|0] "" Vector__XXX
 SG_ M17_Tem2_Valid : 31|1@1+ (1,0) [0|0] "" Vector__XXX
 SG_ M17_Tem2 : 16|11@1+ (0.1,-40) [0|0] "" Vector__XXX
 SG_ M17_Tem1_Valid : 15|1@1+ (1,0) [0|0] "" Vector__XXX
 SG_ M17_Tem1 : 0|11@1+ (0.1,-40) [0|0] "" Vector__XXX

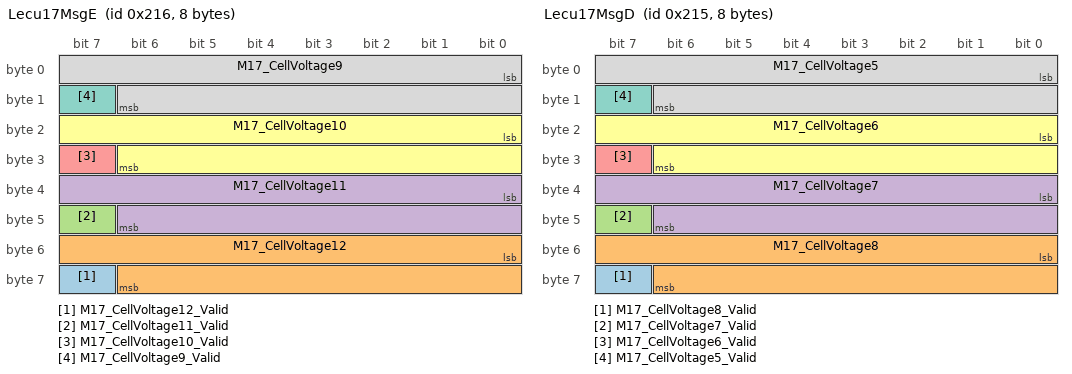
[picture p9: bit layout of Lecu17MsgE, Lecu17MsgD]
BO_ 534 Lecu17MsgE: 8 Vector__XXX
 SG_ M17_CellVoltage12_Valid : 63|1@1+ (1,0) [0|0] "" Vector__XXX
 SG_ M17_CellVoltage12 : 48|15@1- (0.001,0) [0|0] "" Vector__XXX
 SG_ M17_CellVoltage11_Valid : 47|1@1+ (1,0) [0|0] "" Vector__XXX
 SG_ M17_CellVoltage11 : 32|15@1- (0.001,0) [0|0] "" Vector__XXX
 SG_ M17_CellVoltage10_Valid : 31|1@1+ (1,0) [0|0] "" Vector__XXX
 SG_ M17_CellVoltage10 : 16|15@1- (0.001,0) [0|0] "" Vector__XXX
 SG_ M17_CellVoltage9_Valid : 15|1@1+ (1,0) [0|0] "" Vector__XXX
 SG_ M17_CellVoltage9 : 0|15@1- (0.001,0) [0|0] "" Vector__XXX

BO_ 533 Lecu17MsgD: 8 Vector__XXX
 SG_ M17_CellVoltage8_Valid : 63|1@1+ (1,0) [0|0] "" Vector__XXX
 SG_ M17_CellVoltage8 : 48|15@1- (0.001,0) [0|0] "" Vector__XXX
 SG_ M17_CellVoltage7_Valid : 47|1@1+ (1,0) [0|0] "" Vector__XXX
 SG_ M17_CellVoltage7 : 32|15@1- (0.001,0) [0|0] "" Vector__XXX
 SG_ M17_CellVoltage6_Valid : 31|1@1+ (1,0) [0|0] "" Vector__XXX
 SG_ M17_CellVoltage6 : 16|15@1- (0.001,0) [0|0] "" Vector__XXX
 SG_ M17_CellVoltage5_Valid : 15|1@1+ (1,0) [0|0] "" Vector__XXX
 SG_ M17_CellVoltage5 : 0|15@1- (0.001,0) [0|0] "" Vector__XXX

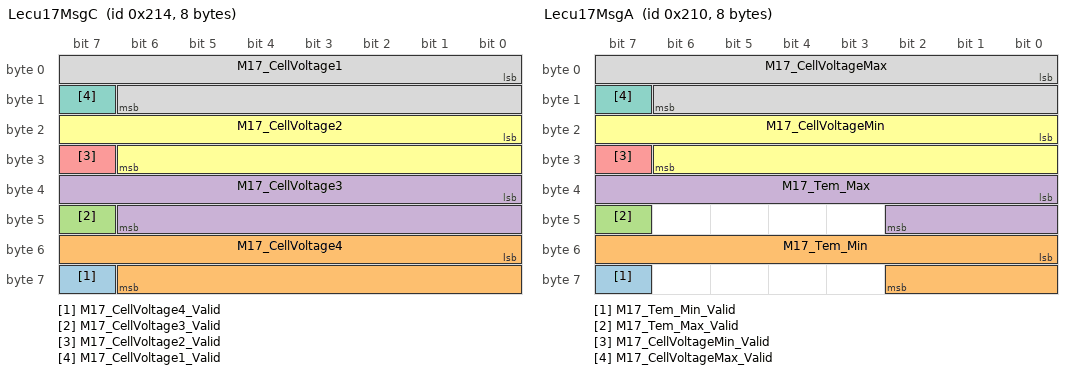
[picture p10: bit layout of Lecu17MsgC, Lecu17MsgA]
BO_ 532 Lecu17MsgC: 8 Vector__XXX
 SG_ M17_CellVoltage4_Valid : 63|1@1+ (1,0) [0|0] "" Vector__XXX
 SG_ M17_CellVoltage4 : 48|15@1- (0.001,0) [0|0] "" Vector__XXX
 SG_ M17_CellVoltage3_Valid : 47|1@1+ (1,0) [0|0] "" Vector__XXX
 SG_ M17_CellVoltage3 : 32|15@1- (0.001,0) [0|0] "" Vector__XXX
 SG_ M17_CellVoltage2_Valid : 31|1@1+ (1,0) [0|0] "" Vector__XXX
 SG_ M17_CellVoltage2 : 16|15@1- (0.001,0) [0|0] "" Vector__XXX
 SG_ M17_CellVoltage1_Valid : 15|1@1+ (1,0) [0|0] "" Vector__XXX
 SG_ M17_CellVoltage1 : 0|15@1- (0.001,0) [0|0] "" Vector__XXX

BO_ 528 Lecu17MsgA: 8 LECU17
 SG_ M17_Tem_Min_Valid : 63|1@1+ (1,0) [0|0] ""  BMU
 SG_ M17_Tem_Min : 48|11@1+ (0.1,-40) [0|0] "℃"  BMU
 SG_ M17_Tem_Max_Valid : 47|1@1+ (1,0) [0|0] ""  BMU
 SG_ M17_Tem_Max : 32|11@1+ (0.1,-40) [0|0] "℃"  BMU
 SG_ M17_CellVoltageMin_Valid : 31|1@1+ (1,0) [0|0] ""  BMU
 SG_ M17_CellVoltageMin : 16|15@1- (0.001,0) [0|0] "V"  BMU
 SG_ M17_CellVoltageMax_Valid : 15|1@1+ (1,0) [0|0] ""  BMU
 SG_ M17_CellVoltageMax : 0|15@1- (0.001,0) [0|0] "V"  BMU

BO_ 553 Lecu18MsgH: 8 Vector__XXX
 SG_ Lecu_Version3 : 63|8@0+ (1,0) [0|0] "" Vector__XXX
 SG_ Lecu_Version2 : 55|8@0+ (1,0) [0|0] "" Vector__XXX
 SG_ Lecu_Version1 : 47|8@0+ (1,0) [0|0] "" Vector__XXX
 SG_ Lecu_Version0 : 39|8@0+ (1,0) [0|0] "" Vector__XXX
 SG_ M18_CellBalance24 : 23|1@1+ (1,0) [0|0] "" Vector__XXX
 SG_ M18_CellBalance23 : 22|1@1+ (1,0) [0|0] "" Vector__XXX
 SG_ M18_CellBalance22 : 21|1@1+ (1,0) [0|0] "" Vector__XXX
 SG_ M18_CellBalance21 : 20|1@1+ (1,0) [0|0] "" Vector__XXX
 SG_ M18_CellBalance20 : 19|1@1+ (1,0) [0|0] "" Vector__XXX
 SG_ M18_CellBalance19 : 18|1@1+ (1,0) [0|0] "" Vector__XXX
 SG_ M18_CellBalance18 : 17|1@1+ (1,0) [0|0] "" Vector__XXX
 SG_ M18_CellBalance17 : 16|1@1+ (1,0) [0|0] "" Vector__XXX
 SG_ M18_CellBalance16 : 15|1@1+ (1,0) [0|0] "" Vector__XXX
 SG_ M18_CellBalance15 : 14|1@1+ (1,0) [0|0] "" Vector__XXX
 SG_ M18_CellBalance14 : 13|1@1+ (1,0) [0|0] "" Vector__XXX
 SG_ M18_CellBalance13 : 12|1@1+ (1,0) [0|0] "" Vector__XXX
 SG_ M18_CellBalance9 : 8|1@1+ (1,0) [0|0] "" Vector__XXX
 SG_ M18_CellBalance8 : 7|1@1+ (1,0) [0|0] "" Vector__XXX
 SG_ M18_CellBalance7 : 6|1@1+ (1,0) [0|0] "" Vector__XXX
 SG_ M18_CellBalance6 : 5|1@1+ (1,0) [0|0] "" Vector__XXX
 SG_ M18_CellBalance5 : 4|1@1+ (1,0) [0|0] "" Vector__XXX
 SG_ M18_CellBalance4 : 3|1@1+ (1,0) [0|0] "" Vector__XXX
 SG_ M18_CellBalance3 : 2|1@1+ (1,0) [0|0] "" Vector__XXX
 SG_ M18_CellBalance2 : 1|1@1+ (1,0) [0|0] "" Vector__XXX
 SG_ M18_CellBalance12 : 11|1@1+ (1,0) [0|0] "" Vector__XXX
 SG_ M18_CellBalance11 : 10|1@1+ (1,0) [0|0] "" Vector__XXX
 SG_ M18_CellBalance10 : 9|1@1+ (1,0) [0|0] "" Vector__XXX
 SG_ M18_CellBalance1 : 0|1@1+ (1,0) [0|0] "" Vector__XXX

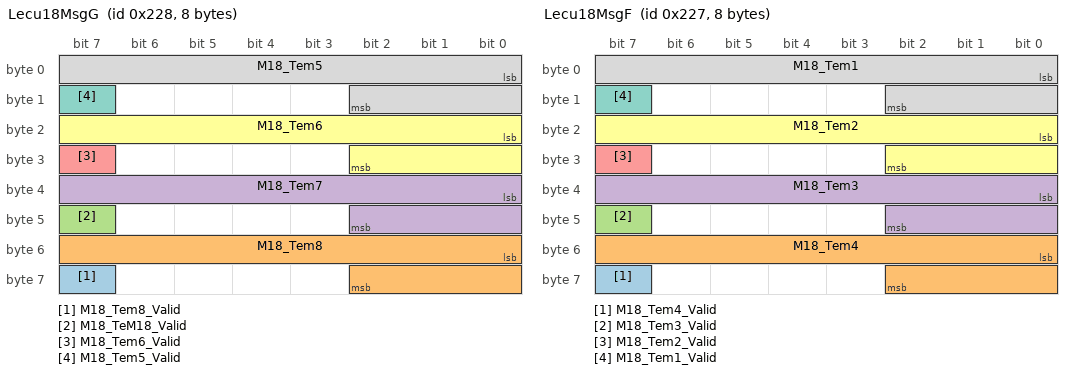
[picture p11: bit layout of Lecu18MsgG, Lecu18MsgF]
BO_ 552 Lecu18MsgG: 8 Vector__XXX
 SG_ M18_Tem8_Valid : 63|1@1+ (1,0) [0|0] "" Vector__XXX
 SG_ M18_Tem8 : 48|11@1+ (0.1,-40) [0|0] "" Vector__XXX
 SG_ M18_TeM18_Valid : 47|1@1+ (1,0) [0|0] "" Vector__XXX
 SG_ M18_Tem7 : 32|11@1+ (0.1,-40) [0|0] "" Vector__XXX
 SG_ M18_Tem6_Valid : 31|1@1+ (1,0) [0|0] "" Vector__XXX
 SG_ M18_Tem6 : 16|11@1+ (0.1,-40) [0|0] "" Vector__XXX
 SG_ M18_Tem5_Valid : 15|1@1+ (1,0) [0|0] "" Vector__XXX
 SG_ M18_Tem5 : 0|11@1+ (0.1,-40) [0|0] "" Vector__XXX

BO_ 551 Lecu18MsgF: 8 Vector__XXX
 SG_ M18_Tem4_Valid : 63|1@1+ (1,0) [0|0] "" Vector__XXX
 SG_ M18_Tem4 : 48|11@1+ (0.1,-40) [0|0] "" Vector__XXX
 SG_ M18_Tem3_Valid : 47|1@1+ (1,0) [0|0] "" Vector__XXX
 SG_ M18_Tem3 : 32|11@1+ (0.1,-40) [0|0] "" Vector__XXX
 SG_ M18_Tem2_Valid : 31|1@1+ (1,0) [0|0] "" Vector__XXX
 SG_ M18_Tem2 : 16|11@1+ (0.1,-40) [0|0] "" Vector__XXX
 SG_ M18_Tem1_Valid : 15|1@1+ (1,0) [0|0] "" Vector__XXX
 SG_ M18_Tem1 : 0|11@1+ (0.1,-40) [0|0] "" Vector__XXX

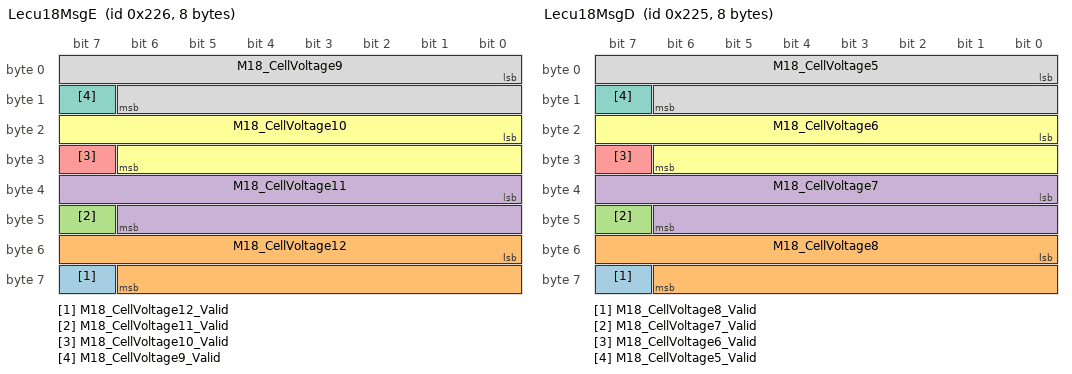
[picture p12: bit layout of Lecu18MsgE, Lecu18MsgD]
BO_ 550 Lecu18MsgE: 8 Vector__XXX
 SG_ M18_CellVoltage12_Valid : 63|1@1+ (1,0) [0|0] "" Vector__XXX
 SG_ M18_CellVoltage12 : 48|15@1- (0.001,0) [0|0] "" Vector__XXX
 SG_ M18_CellVoltage11_Valid : 47|1@1+ (1,0) [0|0] "" Vector__XXX
 SG_ M18_CellVoltage11 : 32|15@1- (0.001,0) [0|0] "" Vector__XXX
 SG_ M18_CellVoltage10_Valid : 31|1@1+ (1,0) [0|0] "" Vector__XXX
 SG_ M18_CellVoltage10 : 16|15@1- (0.001,0) [0|0] "" Vector__XXX
 SG_ M18_CellVoltage9_Valid : 15|1@1+ (1,0) [0|0] "" Vector__XXX
 SG_ M18_CellVoltage9 : 0|15@1- (0.001,0) [0|0] "" Vector__XXX

BO_ 549 Lecu18MsgD: 8 Vector__XXX
 SG_ M18_CellVoltage8_Valid : 63|1@1+ (1,0) [0|0] "" Vector__XXX
 SG_ M18_CellVoltage8 : 48|15@1- (0.001,0) [0|0] "" Vector__XXX
 SG_ M18_CellVoltage7_Valid : 47|1@1+ (1,0) [0|0] "" Vector__XXX
 SG_ M18_CellVoltage7 : 32|15@1- (0.001,0) [0|0] "" Vector__XXX
 SG_ M18_CellVoltage6_Valid : 31|1@1+ (1,0) [0|0] "" Vector__XXX
 SG_ M18_CellVoltage6 : 16|15@1- (0.001,0) [0|0] "" Vector__XXX
 SG_ M18_CellVoltage5_Valid : 15|1@1+ (1,0) [0|0] "" Vector__XXX
 SG_ M18_CellVoltage5 : 0|15@1- (0.001,0) [0|0] "" Vector__XXX

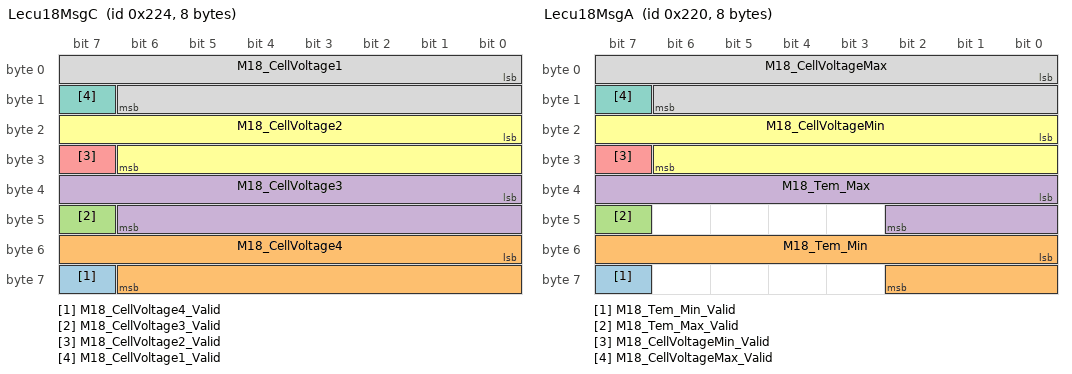
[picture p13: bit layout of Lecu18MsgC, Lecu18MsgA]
BO_ 548 Lecu18MsgC: 8 Vector__XXX
 SG_ M18_CellVoltage4_Valid : 63|1@1+ (1,0) [0|0] "" Vector__XXX
 SG_ M18_CellVoltage4 : 48|15@1- (0.001,0) [0|0] "" Vector__XXX
 SG_ M18_CellVoltage3_Valid : 47|1@1+ (1,0) [0|0] "" Vector__XXX
 SG_ M18_CellVoltage3 : 32|15@1- (0.001,0) [0|0] "" Vector__XXX
 SG_ M18_CellVoltage2_Valid : 31|1@1+ (1,0) [0|0] "" Vector__XXX
 SG_ M18_CellVoltage2 : 16|15@1- (0.001,0) [0|0] "" Vector__XXX
 SG_ M18_CellVoltage1_Valid : 15|1@1+ (1,0) [0|0] "" Vector__XXX
 SG_ M18_CellVoltage1 : 0|15@1- (0.001,0) [0|0] "" Vector__XXX

BO_ 544 Lecu18MsgA: 8 LECU18
 SG_ M18_Tem_Min_Valid : 63|1@1+ (1,0) [0|0] ""  BMU
 SG_ M18_Tem_Min : 48|11@1+ (0.1,-40) [0|0] "℃"  BMU
 SG_ M18_Tem_Max_Valid : 47|1@1+ (1,0) [0|0] ""  BMU
 SG_ M18_Tem_Max : 32|11@1+ (0.1,-40) [0|0] "℃"  BMU
 SG_ M18_CellVoltageMin_Valid : 31|1@1+ (1,0) [0|0] ""  BMU
 SG_ M18_CellVoltageMin : 16|15@1- (0.001,0) [0|0] "V"  BMU
 SG_ M18_CellVoltageMax_Valid : 15|1@1+ (1,0) [0|0] ""  BMU
 SG_ M18_CellVoltageMax : 0|15@1- (0.001,0) [0|0] "V"  BMU

BO_ 569 Lecu19MsgH: 8 Vector__XXX
 SG_ Lecu_Version3 : 63|8@0+ (1,0) [0|0] "" Vector__XXX
 SG_ Lecu_Version2 : 55|8@0+ (1,0) [0|0] "" Vector__XXX
 SG_ Lecu_Version1 : 47|8@0+ (1,0) [0|0] "" Vector__XXX
 SG_ Lecu_Version0 : 39|8@0+ (1,0) [0|0] "" Vector__XXX
 SG_ M19_CellBalance24 : 23|1@1+ (1,0) [0|0] "" Vector__XXX
 SG_ M19_CellBalance23 : 22|1@1+ (1,0) [0|0] "" Vector__XXX
 SG_ M19_CellBalance22 : 21|1@1+ (1,0) [0|0] "" Vector__XXX
 SG_ M19_CellBalance21 : 20|1@1+ (1,0) [0|0] "" Vector__XXX
 SG_ M19_CellBalance20 : 19|1@1+ (1,0) [0|0] "" Vector__XXX
 SG_ M19_CellBalance19 : 18|1@1+ (1,0) [0|0] "" Vector__XXX
 SG_ M19_CellBalance18 : 17|1@1+ (1,0) [0|0] "" Vector__XXX
 SG_ M19_CellBalance17 : 16|1@1+ (1,0) [0|0] "" Vector__XXX
 SG_ M19_CellBalance16 : 15|1@1+ (1,0) [0|0] "" Vector__XXX
 SG_ M19_CellBalance15 : 14|1@1+ (1,0) [0|0] "" Vector__XXX
 SG_ M19_CellBalance14 : 13|1@1+ (1,0) [0|0] "" Vector__XXX
 SG_ M19_CellBalance13 : 12|1@1+ (1,0) [0|0] "" Vector__XXX
 SG_ M19_CellBalance9 : 8|1@1+ (1,0) [0|0] "" Vector__XXX
 SG_ M19_CellBalance8 : 7|1@1+ (1,0) [0|0] "" Vector__XXX
 SG_ M19_CellBalance7 : 6|1@1+ (1,0) [0|0] "" Vector__XXX
 SG_ M19_CellBalance6 : 5|1@1+ (1,0) [0|0] "" Vector__XXX
 SG_ M19_CellBalance5 : 4|1@1+ (1,0) [0|0] "" Vector__XXX
 SG_ M19_CellBalance4 : 3|1@1+ (1,0) [0|0] "" Vector__XXX
 SG_ M19_CellBalance3 : 2|1@1+ (1,0) [0|0] "" Vector__XXX
 SG_ M19_CellBalance2 : 1|1@1+ (1,0) [0|0] "" Vector__XXX
 SG_ M19_CellBalance12 : 11|1@1+ (1,0) [0|0] "" Vector__XXX
 SG_ M19_CellBalance11 : 10|1@1+ (1,0) [0|0] "" Vector__XXX
 SG_ M19_CellBalance10 : 9|1@1+ (1,0) [0|0] "" Vector__XXX
 SG_ M19_CellBalance1 : 0|1@1+ (1,0) [0|0] "" Vector__XXX

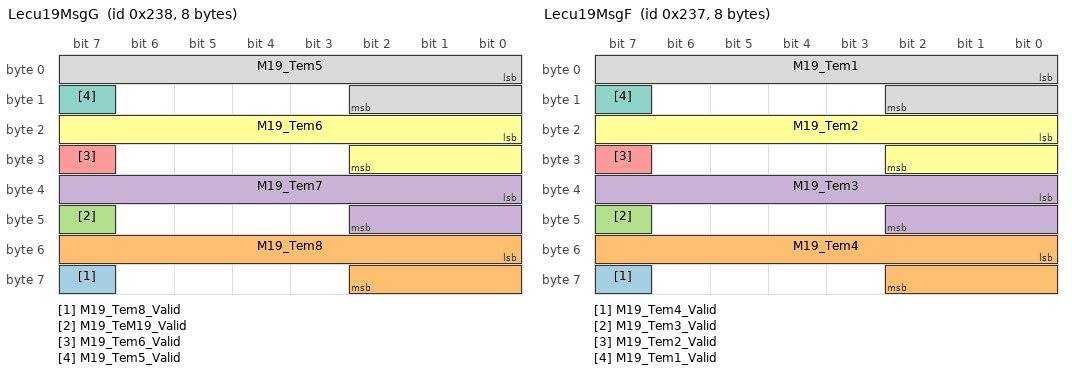
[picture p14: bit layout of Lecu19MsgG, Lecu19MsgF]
BO_ 568 Lecu19MsgG: 8 Vector__XXX
 SG_ M19_Tem8_Valid : 63|1@1+ (1,0) [0|0] "" Vector__XXX
 SG_ M19_Tem8 : 48|11@1+ (0.1,-40) [0|0] "" Vector__XXX
 SG_ M19_TeM19_Valid : 47|1@1+ (1,0) [0|0] "" Vector__XXX
 SG_ M19_Tem7 : 32|11@1+ (0.1,-40) [0|0] "" Vector__XXX
 SG_ M19_Tem6_Valid : 31|1@1+ (1,0) [0|0] "" Vector__XXX
 SG_ M19_Tem6 : 16|11@1+ (0.1,-40) [0|0] "" Vector__XXX
 SG_ M19_Tem5_Valid : 15|1@1+ (1,0) [0|0] "" Vector__XXX
 SG_ M19_Tem5 : 0|11@1+ (0.1,-40) [0|0] "" Vector__XXX

BO_ 567 Lecu19MsgF: 8 Vector__XXX
 SG_ M19_Tem4_Valid : 63|1@1+ (1,0) [0|0] "" Vector__XXX
 SG_ M19_Tem4 : 48|11@1+ (0.1,-40) [0|0] "" Vector__XXX
 SG_ M19_Tem3_Valid : 47|1@1+ (1,0) [0|0] "" Vector__XXX
 SG_ M19_Tem3 : 32|11@1+ (0.1,-40) [0|0] "" Vector__XXX
 SG_ M19_Tem2_Valid : 31|1@1+ (1,0) [0|0] "" Vector__XXX
 SG_ M19_Tem2 : 16|11@1+ (0.1,-40) [0|0] "" Vector__XXX
 SG_ M19_Tem1_Valid : 15|1@1+ (1,0) [0|0] "" Vector__XXX
 SG_ M19_Tem1 : 0|11@1+ (0.1,-40) [0|0] "" Vector__XXX

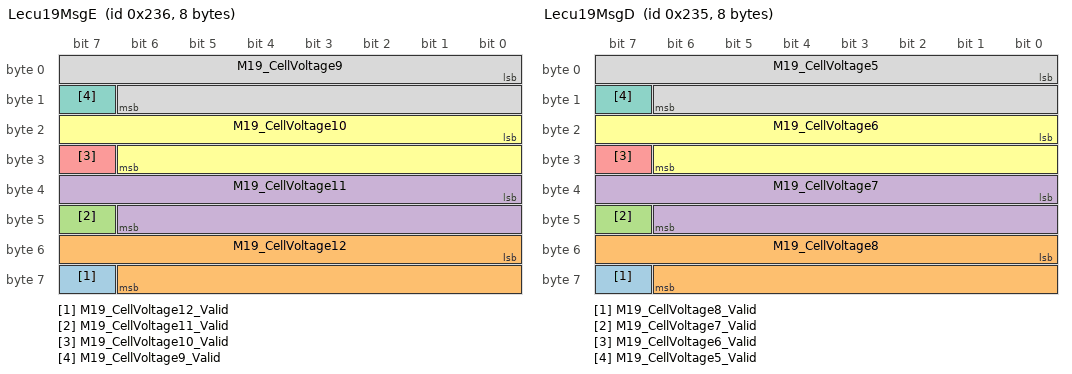
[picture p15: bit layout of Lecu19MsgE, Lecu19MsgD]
BO_ 566 Lecu19MsgE: 8 Vector__XXX
 SG_ M19_CellVoltage12_Valid : 63|1@1+ (1,0) [0|0] "" Vector__XXX
 SG_ M19_CellVoltage12 : 48|15@1- (0.001,0) [0|0] "" Vector__XXX
 SG_ M19_CellVoltage11_Valid : 47|1@1+ (1,0) [0|0] "" Vector__XXX
 SG_ M19_CellVoltage11 : 32|15@1- (0.001,0) [0|0] "" Vector__XXX
 SG_ M19_CellVoltage10_Valid : 31|1@1+ (1,0) [0|0] "" Vector__XXX
 SG_ M19_CellVoltage10 : 16|15@1- (0.001,0) [0|0] "" Vector__XXX
 SG_ M19_CellVoltage9_Valid : 15|1@1+ (1,0) [0|0] "" Vector__XXX
 SG_ M19_CellVoltage9 : 0|15@1- (0.001,0) [0|0] "" Vector__XXX

BO_ 565 Lecu19MsgD: 8 Vector__XXX
 SG_ M19_CellVoltage8_Valid : 63|1@1+ (1,0) [0|0] "" Vector__XXX
 SG_ M19_CellVoltage8 : 48|15@1- (0.001,0) [0|0] "" Vector__XXX
 SG_ M19_CellVoltage7_Valid : 47|1@1+ (1,0) [0|0] "" Vector__XXX
 SG_ M19_CellVoltage7 : 32|15@1- (0.001,0) [0|0] "" Vector__XXX
 SG_ M19_CellVoltage6_Valid : 31|1@1+ (1,0) [0|0] "" Vector__XXX
 SG_ M19_CellVoltage6 : 16|15@1- (0.001,0) [0|0] "" Vector__XXX
 SG_ M19_CellVoltage5_Valid : 15|1@1+ (1,0) [0|0] "" Vector__XXX
 SG_ M19_CellVoltage5 : 0|15@1- (0.001,0) [0|0] "" Vector__XXX

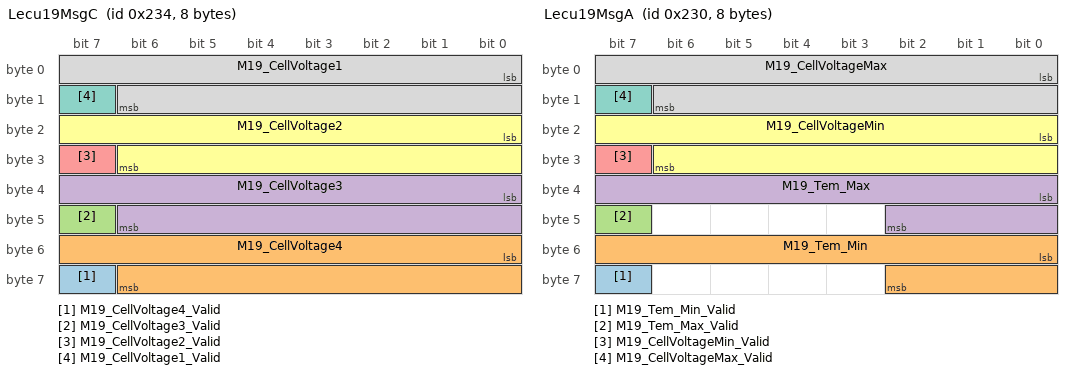
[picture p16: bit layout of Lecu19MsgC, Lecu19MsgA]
BO_ 564 Lecu19MsgC: 8 Vector__XXX
 SG_ M19_CellVoltage4_Valid : 63|1@1+ (1,0) [0|0] "" Vector__XXX
 SG_ M19_CellVoltage4 : 48|15@1- (0.001,0) [0|0] "" Vector__XXX
 SG_ M19_CellVoltage3_Valid : 47|1@1+ (1,0) [0|0] "" Vector__XXX
 SG_ M19_CellVoltage3 : 32|15@1- (0.001,0) [0|0] "" Vector__XXX
 SG_ M19_CellVoltage2_Valid : 31|1@1+ (1,0) [0|0] "" Vector__XXX
 SG_ M19_CellVoltage2 : 16|15@1- (0.001,0) [0|0] "" Vector__XXX
 SG_ M19_CellVoltage1_Valid : 15|1@1+ (1,0) [0|0] "" Vector__XXX
 SG_ M19_CellVoltage1 : 0|15@1- (0.001,0) [0|0] "" Vector__XXX

BO_ 560 Lecu19MsgA: 8 LECU19
 SG_ M19_Tem_Min_Valid : 63|1@1+ (1,0) [0|0] ""  BMU
 SG_ M19_Tem_Min : 48|11@1+ (0.1,-40) [0|0] "℃"  BMU
 SG_ M19_Tem_Max_Valid : 47|1@1+ (1,0) [0|0] ""  BMU
 SG_ M19_Tem_Max : 32|11@1+ (0.1,-40) [0|0] "℃"  BMU
 SG_ M19_CellVoltageMin_Valid : 31|1@1+ (1,0) [0|0] ""  BMU
 SG_ M19_CellVoltageMin : 16|15@1- (0.001,0) [0|0] "V"  BMU
 SG_ M19_CellVoltageMax_Valid : 15|1@1+ (1,0) [0|0] ""  BMU
 SG_ M19_CellVoltageMax : 0|15@1- (0.001,0) [0|0] "V"  BMU

BO_ 585 Lecu20MsgH: 8 Vector__XXX
 SG_ Lecu_Version3 : 63|8@0+ (1,0) [0|0] "" Vector__XXX
 SG_ Lecu_Version2 : 55|8@0+ (1,0) [0|0] "" Vector__XXX
 SG_ Lecu_Version1 : 47|8@0+ (1,0) [0|0] "" Vector__XXX
 SG_ Lecu_Version0 : 39|8@0+ (1,0) [0|0] "" Vector__XXX
 SG_ M20_CellBalance24 : 23|1@1+ (1,0) [0|0] "" Vector__XXX
 SG_ M20_CellBalance23 : 22|1@1+ (1,0) [0|0] "" Vector__XXX
 SG_ M20_CellBalance22 : 21|1@1+ (1,0) [0|0] "" Vector__XXX
 SG_ M20_CellBalance21 : 20|1@1+ (1,0) [0|0] "" Vector__XXX
 SG_ M20_CellBalance20 : 19|1@1+ (1,0) [0|0] "" Vector__XXX
 SG_ M20_CellBalance19 : 18|1@1+ (1,0) [0|0] "" Vector__XXX
 SG_ M20_CellBalance18 : 17|1@1+ (1,0) [0|0] "" Vector__XXX
 SG_ M20_CellBalance17 : 16|1@1+ (1,0) [0|0] "" Vector__XXX
 SG_ M20_CellBalance16 : 15|1@1+ (1,0) [0|0] "" Vector__XXX
 SG_ M20_CellBalance15 : 14|1@1+ (1,0) [0|0] "" Vector__XXX
 SG_ M20_CellBalance14 : 13|1@1+ (1,0) [0|0] "" Vector__XXX
 SG_ M20_CellBalance13 : 12|1@1+ (1,0) [0|0] "" Vector__XXX
 SG_ M20_CellBalance9 : 8|1@1+ (1,0) [0|0] "" Vector__XXX
 SG_ M20_CellBalance8 : 7|1@1+ (1,0) [0|0] "" Vector__XXX
 SG_ M20_CellBalance7 : 6|1@1+ (1,0) [0|0] "" Vector__XXX
 SG_ M20_CellBalance6 : 5|1@1+ (1,0) [0|0] "" Vector__XXX
 SG_ M20_CellBalance5 : 4|1@1+ (1,0) [0|0] "" Vector__XXX
 SG_ M20_CellBalance4 : 3|1@1+ (1,0) [0|0] "" Vector__XXX
 SG_ M20_CellBalance3 : 2|1@1+ (1,0) [0|0] "" Vector__XXX
 SG_ M20_CellBalance2 : 1|1@1+ (1,0) [0|0] "" Vector__XXX
 SG_ M20_CellBalance12 : 11|1@1+ (1,0) [0|0] "" Vector__XXX
 SG_ M20_CellBalance11 : 10|1@1+ (1,0) [0|0] "" Vector__XXX
 SG_ M20_CellBalance10 : 9|1@1+ (1,0) [0|0] "" Vector__XXX
 SG_ M20_CellBalance1 : 0|1@1+ (1,0) [0|0] "" Vector__XXX

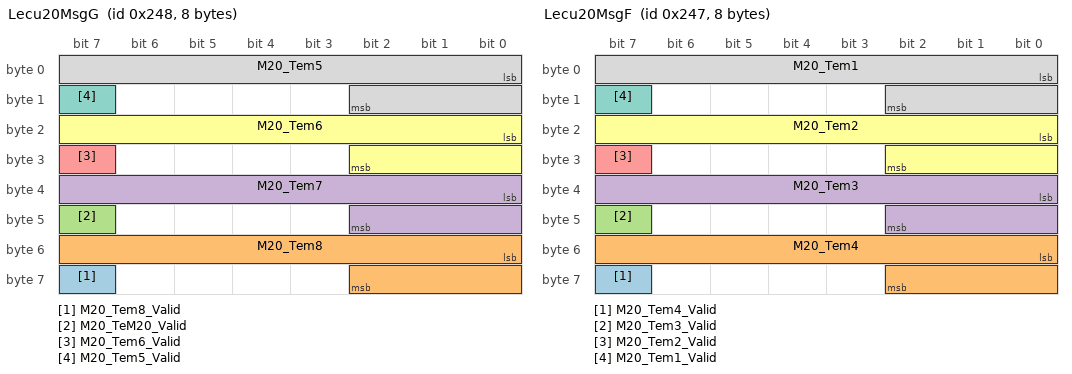
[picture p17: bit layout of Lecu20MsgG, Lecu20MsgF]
BO_ 584 Lecu20MsgG: 8 Vector__XXX
 SG_ M20_Tem8_Valid : 63|1@1+ (1,0) [0|0] "" Vector__XXX
 SG_ M20_Tem8 : 48|11@1+ (0.1,-40) [0|0] "" Vector__XXX
 SG_ M20_TeM20_Valid : 47|1@1+ (1,0) [0|0] "" Vector__XXX
 SG_ M20_Tem7 : 32|11@1+ (0.1,-40) [0|0] "" Vector__XXX
 SG_ M20_Tem6_Valid : 31|1@1+ (1,0) [0|0] "" Vector__XXX
 SG_ M20_Tem6 : 16|11@1+ (0.1,-40) [0|0] "" Vector__XXX
 SG_ M20_Tem5_Valid : 15|1@1+ (1,0) [0|0] "" Vector__XXX
 SG_ M20_Tem5 : 0|11@1+ (0.1,-40) [0|0] "" Vector__XXX

BO_ 583 Lecu20MsgF: 8 Vector__XXX
 SG_ M20_Tem4_Valid : 63|1@1+ (1,0) [0|0] "" Vector__XXX
 SG_ M20_Tem4 : 48|11@1+ (0.1,-40) [0|0] "" Vector__XXX
 SG_ M20_Tem3_Valid : 47|1@1+ (1,0) [0|0] "" Vector__XXX
 SG_ M20_Tem3 : 32|11@1+ (0.1,-40) [0|0] "" Vector__XXX
 SG_ M20_Tem2_Valid : 31|1@1+ (1,0) [0|0] "" Vector__XXX
 SG_ M20_Tem2 : 16|11@1+ (0.1,-40) [0|0] "" Vector__XXX
 SG_ M20_Tem1_Valid : 15|1@1+ (1,0) [0|0] "" Vector__XXX
 SG_ M20_Tem1 : 0|11@1+ (0.1,-40) [0|0] "" Vector__XXX

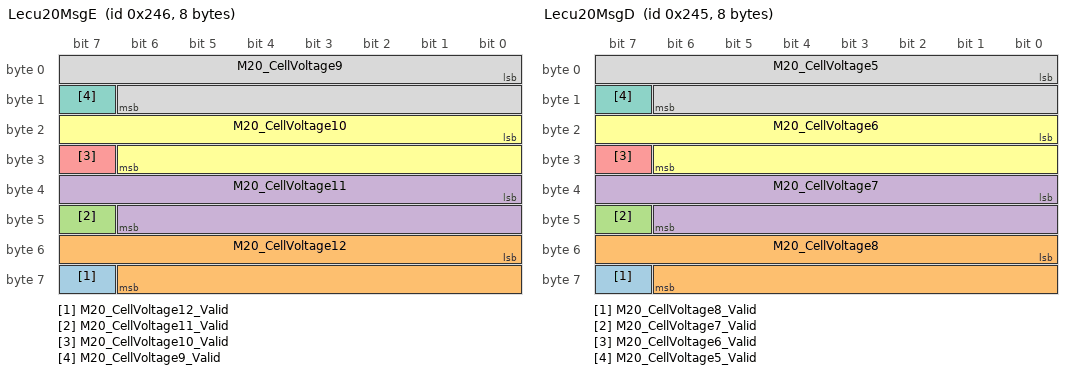
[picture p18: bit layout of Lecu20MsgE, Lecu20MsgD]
BO_ 582 Lecu20MsgE: 8 Vector__XXX
 SG_ M20_CellVoltage12_Valid : 63|1@1+ (1,0) [0|0] "" Vector__XXX
 SG_ M20_CellVoltage12 : 48|15@1- (0.001,0) [0|0] "" Vector__XXX
 SG_ M20_CellVoltage11_Valid : 47|1@1+ (1,0) [0|0] "" Vector__XXX
 SG_ M20_CellVoltage11 : 32|15@1- (0.001,0) [0|0] "" Vector__XXX
 SG_ M20_CellVoltage10_Valid : 31|1@1+ (1,0) [0|0] "" Vector__XXX
 SG_ M20_CellVoltage10 : 16|15@1- (0.001,0) [0|0] "" Vector__XXX
 SG_ M20_CellVoltage9_Valid : 15|1@1+ (1,0) [0|0] "" Vector__XXX
 SG_ M20_CellVoltage9 : 0|15@1- (0.001,0) [0|0] "" Vector__XXX

BO_ 581 Lecu20MsgD: 8 Vector__XXX
 SG_ M20_CellVoltage8_Valid : 63|1@1+ (1,0) [0|0] "" Vector__XXX
 SG_ M20_CellVoltage8 : 48|15@1- (0.001,0) [0|0] "" Vector__XXX
 SG_ M20_CellVoltage7_Valid : 47|1@1+ (1,0) [0|0] "" Vector__XXX
 SG_ M20_CellVoltage7 : 32|15@1- (0.001,0) [0|0] "" Vector__XXX
 SG_ M20_CellVoltage6_Valid : 31|1@1+ (1,0) [0|0] "" Vector__XXX
 SG_ M20_CellVoltage6 : 16|15@1- (0.001,0) [0|0] "" Vector__XXX
 SG_ M20_CellVoltage5_Valid : 15|1@1+ (1,0) [0|0] "" Vector__XXX
 SG_ M20_CellVoltage5 : 0|15@1- (0.001,0) [0|0] "" Vector__XXX

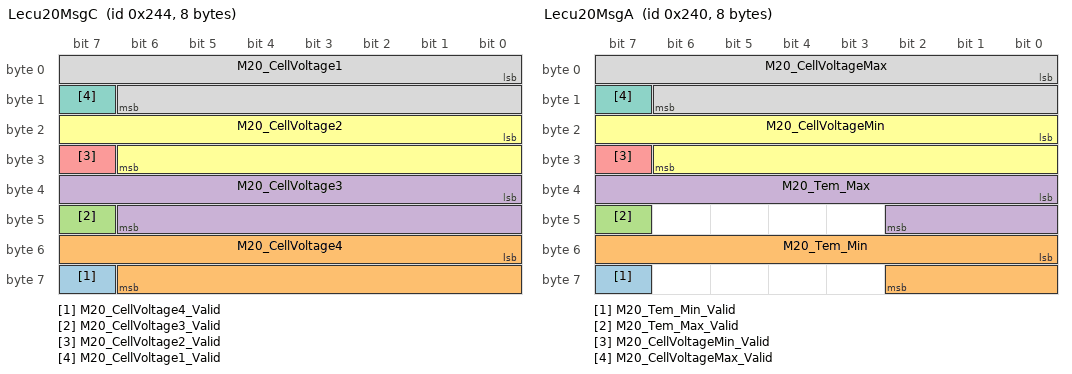
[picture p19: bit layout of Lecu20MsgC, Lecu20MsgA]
BO_ 580 Lecu20MsgC: 8 Vector__XXX
 SG_ M20_CellVoltage4_Valid : 63|1@1+ (1,0) [0|0] "" Vector__XXX
 SG_ M20_CellVoltage4 : 48|15@1- (0.001,0) [0|0] "" Vector__XXX
 SG_ M20_CellVoltage3_Valid : 47|1@1+ (1,0) [0|0] "" Vector__XXX
 SG_ M20_CellVoltage3 : 32|15@1- (0.001,0) [0|0] "" Vector__XXX
 SG_ M20_CellVoltage2_Valid : 31|1@1+ (1,0) [0|0] "" Vector__XXX
 SG_ M20_CellVoltage2 : 16|15@1- (0.001,0) [0|0] "" Vector__XXX
 SG_ M20_CellVoltage1_Valid : 15|1@1+ (1,0) [0|0] "" Vector__XXX
 SG_ M20_CellVoltage1 : 0|15@1- (0.001,0) [0|0] "" Vector__XXX

BO_ 576 Lecu20MsgA: 8 LECU20
 SG_ M20_Tem_Min_Valid : 63|1@1+ (1,0) [0|0] ""  BMU
 SG_ M20_Tem_Min : 48|11@1+ (0.1,-40) [0|0] "℃"  BMU
 SG_ M20_Tem_Max_Valid : 47|1@1+ (1,0) [0|0] ""  BMU
 SG_ M20_Tem_Max : 32|11@1+ (0.1,-40) [0|0] "℃"  BMU
 SG_ M20_CellVoltageMin_Valid : 31|1@1+ (1,0) [0|0] ""  BMU
 SG_ M20_CellVoltageMin : 16|15@1- (0.001,0) [0|0] "V"  BMU
 SG_ M20_CellVoltageMax_Valid : 15|1@1+ (1,0) [0|0] ""  BMU
 SG_ M20_CellVoltageMax : 0|15@1- (0.001,0) [0|0] "V"  BMU

BO_ 601 Lecu21MsgH: 8 Vector__XXX
 SG_ Lecu_Version3 : 63|8@0+ (1,0) [0|0] "" Vector__XXX
 SG_ Lecu_Version2 : 55|8@0+ (1,0) [0|0] "" Vector__XXX
 SG_ Lecu_Version1 : 47|8@0+ (1,0) [0|0] "" Vector__XXX
 SG_ Lecu_Version0 : 39|8@0+ (1,0) [0|0] "" Vector__XXX
 SG_ M21_CellBalance24 : 23|1@1+ (1,0) [0|0] "" Vector__XXX
 SG_ M21_CellBalance23 : 22|1@1+ (1,0) [0|0] "" Vector__XXX
 SG_ M21_CellBalance22 : 21|1@1+ (1,0) [0|0] "" Vector__XXX
 SG_ M21_CellBalance21 : 20|1@1+ (1,0) [0|0] "" Vector__XXX
 SG_ M21_CellBalance20 : 19|1@1+ (1,0) [0|0] "" Vector__XXX
 SG_ M21_CellBalance19 : 18|1@1+ (1,0) [0|0] "" Vector__XXX
 SG_ M21_CellBalance18 : 17|1@1+ (1,0) [0|0] "" Vector__XXX
 SG_ M21_CellBalance17 : 16|1@1+ (1,0) [0|0] "" Vector__XXX
 SG_ M21_CellBalance16 : 15|1@1+ (1,0) [0|0] "" Vector__XXX
 SG_ M21_CellBalance15 : 14|1@1+ (1,0) [0|0] "" Vector__XXX
 SG_ M21_CellBalance14 : 13|1@1+ (1,0) [0|0] "" Vector__XXX
 SG_ M21_CellBalance13 : 12|1@1+ (1,0) [0|0] "" Vector__XXX
 SG_ M21_CellBalance9 : 8|1@1+ (1,0) [0|0] "" Vector__XXX
 SG_ M21_CellBalance8 : 7|1@1+ (1,0) [0|0] "" Vector__XXX
 SG_ M21_CellBalance7 : 6|1@1+ (1,0) [0|0] "" Vector__XXX
 SG_ M21_CellBalance6 : 5|1@1+ (1,0) [0|0] "" Vector__XXX
 SG_ M21_CellBalance5 : 4|1@1+ (1,0) [0|0] "" Vector__XXX
 SG_ M21_CellBalance4 : 3|1@1+ (1,0) [0|0] "" Vector__XXX
 SG_ M21_CellBalance3 : 2|1@1+ (1,0) [0|0] "" Vector__XXX
 SG_ M21_CellBalance2 : 1|1@1+ (1,0) [0|0] "" Vector__XXX
 SG_ M21_CellBalance12 : 11|1@1+ (1,0) [0|0] "" Vector__XXX
 SG_ M21_CellBalance11 : 10|1@1+ (1,0) [0|0] "" Vector__XXX
 SG_ M21_CellBalance10 : 9|1@1+ (1,0) [0|0] "" Vector__XXX
 SG_ M21_CellBalance1 : 0|1@1+ (1,0) [0|0] "" Vector__XXX

BO_ 600 Lecu21MsgG: 8 Vector__XXX
 SG_ M21_Tem8_Valid : 63|1@1+ (1,0) [0|0] "" Vector__XXX
 SG_ M21_Tem8 : 48|11@1+ (0.1,-40) [0|0] "" Vector__XXX
 SG_ M21_TeM21_Valid : 47|1@1+ (1,0) [0|0] "" Vector__XXX
 SG_ M21_Tem7 : 32|11@1+ (0.1,-40) [0|0] "" Vector__XXX
 SG_ M21_Tem6_Valid : 31|1@1+ (1,0) [0|0] "" Vector__XXX
 SG_ M21_Tem6 : 16|11@1+ (0.1,-40) [0|0] "" Vector__XXX
 SG_ M21_Tem5_Valid : 15|1@1+ (1,0) [0|0] "" Vector__XXX
 SG_ M21_Tem5 : 0|11@1+ (0.1,-40) [0|0] "" Vector__XXX

BO_ 599 Lecu21MsgF: 8 Vector__XXX
 SG_ M21_Tem4_Valid : 63|1@1+ (1,0) [0|0] "" Vector__XXX
 SG_ M21_Tem4 : 48|11@1+ (0.1,-40) [0|0] "" Vector__XXX
 SG_ M21_Tem3_Valid : 47|1@1+ (1,0) [0|0] "" Vector__XXX
 SG_ M21_Tem3 : 32|11@1+ (0.1,-40) [0|0] "" Vector__XXX
 SG_ M21_Tem2_Valid : 31|1@1+ (1,0) [0|0] "" Vector__XXX
 SG_ M21_Tem2 : 16|11@1+ (0.1,-40) [0|0] "" Vector__XXX
 SG_ M21_Tem1_Valid : 15|1@1+ (1,0) [0|0] "" Vector__XXX
 SG_ M21_Tem1 : 0|11@1+ (0.1,-40) [0|0] "" Vector__XXX

BO_ 598 Lecu21MsgE: 8 Vector__XXX
 SG_ M21_CellVoltage12_Valid : 63|1@1+ (1,0) [0|0] "" Vector__XXX
 SG_ M21_CellVoltage12 : 48|15@1- (0.001,0) [0|0] "" Vector__XXX
 SG_ M21_CellVoltage11_Valid : 47|1@1+ (1,0) [0|0] "" Vector__XXX
 SG_ M21_CellVoltage11 : 32|15@1- (0.001,0) [0|0] "" Vector__XXX
 SG_ M21_CellVoltage10_Valid : 31|1@1+ (1,0) [0|0] "" Vector__XXX
 SG_ M21_CellVoltage10 : 16|15@1- (0.001,0) [0|0] "" Vector__XXX
 SG_ M21_CellVoltage9_Valid : 15|1@1+ (1,0) [0|0] "" Vector__XXX
 SG_ M21_CellVoltage9 : 0|15@1- (0.001,0) [0|0] "" Vector__XXX

BO_ 597 Lecu21MsgD: 8 Vector__XXX
 SG_ M21_CellVoltage8_Valid : 63|1@1+ (1,0) [0|0] "" Vector__XXX
 SG_ M21_CellVoltage8 : 48|15@1- (0.001,0) [0|0] "" Vector__XXX
 SG_ M21_CellVoltage7_Valid : 47|1@1+ (1,0) [0|0] "" Vector__XXX
 SG_ M21_CellVoltage7 : 32|15@1- (0.001,0) [0|0] "" Vector__XXX
 SG_ M21_CellVoltage6_Valid : 31|1@1+ (1,0) [0|0] "" Vector__XXX
 SG_ M21_CellVoltage6 : 16|15@1- (0.001,0) [0|0] "" Vector__XXX
 SG_ M21_CellVoltage5_Valid : 15|1@1+ (1,0) [0|0] "" Vector__XXX
 SG_ M21_CellVoltage5 : 0|15@1- (0.001,0) [0|0] "" Vector__XXX

BO_ 596 Lecu21MsgC: 8 Vector__XXX
 SG_ M21_CellVoltage4_Valid : 63|1@1+ (1,0) [0|0] "" Vector__XXX
 SG_ M21_CellVoltage4 : 48|15@1- (0.001,0) [0|0] "" Vector__XXX
 SG_ M21_CellVoltage3_Valid : 47|1@1+ (1,0) [0|0] "" Vector__XXX
 SG_ M21_CellVoltage3 : 32|15@1- (0.001,0) [0|0] "" Vector__XXX
 SG_ M21_CellVoltage2_Valid : 31|1@1+ (1,0) [0|0] "" Vector__XXX
 SG_ M21_CellVoltage2 : 16|15@1- (0.001,0) [0|0] "" Vector__XXX
 SG_ M21_CellVoltage1_Valid : 15|1@1+ (1,0) [0|0] "" Vector__XXX
 SG_ M21_CellVoltage1 : 0|15@1- (0.001,0) [0|0] "" Vector__XXX

BO_ 592 Lecu21MsgA: 8 LECU21
 SG_ M21_Tem_Min_Valid : 63|1@1+ (1,0) [0|0] ""  BMU
 SG_ M21_Tem_Min : 48|11@1+ (0.1,-40) [0|0] "℃"  BMU
 SG_ M21_Tem_Max_Valid : 47|1@1+ (1,0) [0|0] ""  BMU
 SG_ M21_Tem_Max : 32|11@1+ (0.1,-40) [0|0] "℃"  BMU
 SG_ M21_CellVoltageMin_Valid : 31|1@1+ (1,0) [0|0] ""  BMU
 SG_ M21_CellVoltageMin : 16|15@1- (0.001,0) [0|0] "V"  BMU
 SG_ M21_CellVoltageMax_Valid : 15|1@1+ (1,0) [0|0] ""  BMU
 SG_ M21_CellVoltageMax : 0|15@1- (0.001,0) [0|0] "V"  BMU

BO_ 617 Lecu22MsgH: 8 Vector__XXX
 SG_ Lecu_Version3 : 63|8@0+ (1,0) [0|0] "" Vector__XXX
 SG_ Lecu_Version2 : 55|8@0+ (1,0) [0|0] "" Vector__XXX
 SG_ Lecu_Version1 : 47|8@0+ (1,0) [0|0] "" Vector__XXX
 SG_ Lecu_Version0 : 39|8@0+ (1,0) [0|0] "" Vector__XXX
 SG_ M22_CellBalance24 : 23|1@1+ (1,0) [0|0] "" Vector__XXX
 SG_ M22_CellBalance23 : 22|1@1+ (1,0) [0|0] "" Vector__XXX
 SG_ M22_CellBalance22 : 21|1@1+ (1,0) [0|0] "" Vector__XXX
 SG_ M22_CellBalance21 : 20|1@1+ (1,0) [0|0] "" Vector__XXX
 SG_ M22_CellBalance20 : 19|1@1+ (1,0) [0|0] "" Vector__XXX
 SG_ M22_CellBalance19 : 18|1@1+ (1,0) [0|0] "" Vector__XXX
 SG_ M22_CellBalance18 : 17|1@1+ (1,0) [0|0] "" Vector__XXX
 SG_ M22_CellBalance17 : 16|1@1+ (1,0) [0|0] "" Vector__XXX
 SG_ M22_CellBalance16 : 15|1@1+ (1,0) [0|0] "" Vector__XXX
 SG_ M22_CellBalance15 : 14|1@1+ (1,0) [0|0] "" Vector__XXX
 SG_ M22_CellBalance14 : 13|1@1+ (1,0) [0|0] "" Vector__XXX
 SG_ M22_CellBalance13 : 12|1@1+ (1,0) [0|0] "" Vector__XXX
 SG_ M22_CellBalance9 : 8|1@1+ (1,0) [0|0] "" Vector__XXX
 SG_ M22_CellBalance8 : 7|1@1+ (1,0) [0|0] "" Vector__XXX
 SG_ M22_CellBalance7 : 6|1@1+ (1,0) [0|0] "" Vector__XXX
 SG_ M22_CellBalance6 : 5|1@1+ (1,0) [0|0] "" Vector__XXX
 SG_ M22_CellBalance5 : 4|1@1+ (1,0) [0|0] "" Vector__XXX
 SG_ M22_CellBalance4 : 3|1@1+ (1,0) [0|0] "" Vector__XXX
 SG_ M22_CellBalance3 : 2|1@1+ (1,0) [0|0] "" Vector__XXX
 SG_ M22_CellBalance2 : 1|1@1+ (1,0) [0|0] "" Vector__XXX
 SG_ M22_CellBalance12 : 11|1@1+ (1,0) [0|0] "" Vector__XXX
 SG_ M22_CellBalance11 : 10|1@1+ (1,0) [0|0] "" Vector__XXX
 SG_ M22_CellBalance10 : 9|1@1+ (1,0) [0|0] "" Vector__XXX
 SG_ M22_CellBalance1 : 0|1@1+ (1,0) [0|0] "" Vector__XXX

BO_ 616 Lecu22MsgG: 8 Vector__XXX
 SG_ M22_Tem8_Valid : 63|1@1+ (1,0) [0|0] "" Vector__XXX
 SG_ M22_Tem8 : 48|11@1+ (0.1,-40) [0|0] "" Vector__XXX
 SG_ M22_TeM22_Valid : 47|1@1+ (1,0) [0|0] "" Vector__XXX
 SG_ M22_Tem7 : 32|11@1+ (0.1,-40) [0|0] "" Vector__XXX
 SG_ M22_Tem6_Valid : 31|1@1+ (1,0) [0|0] "" Vector__XXX
 SG_ M22_Tem6 : 16|11@1+ (0.1,-40) [0|0] "" Vector__XXX
 SG_ M22_Tem5_Valid : 15|1@1+ (1,0) [0|0] "" Vector__XXX
 SG_ M22_Tem5 : 0|11@1+ (0.1,-40) [0|0] "" Vector__XXX

CM_ BO_ 3221225472 "This is a message for not used signals, created by Vector CANdb++ DBC OLE DB Provider.";
CM_ BO_ 258 "显示屏控制紧急上电命令";
CM_ SG_ 274 M1_Tem_Min_Num "温度值";
CM_ SG_ 274 M1_Tem_Max_Num "温度值";
CM_ SG_ 274 M1_CellVoltageMin_Num "单体电池电压值";
CM_ SG_ 274 M1_CellVoltageMax_Num "单体电池电压值";
CM_ SG_ 274 M1_JumperTemp_Max_Valid "
";
CM_ SG_ 274 M1_Tem_Mean "温度平均值";
CM_ SG_ 274 M1_CellVoltageMean "单体电池电压平均值";
CM_ SG_ 770 M32_Tem_Min_Num "温度值";
CM_ SG_ 770 M32_Tem_Max_Num "温度值";
CM_ SG_ 770 M32_CellVoltageMin_Num "单体电池电压值";
CM_ SG_ 770 M32_CellVoltageMax_Num "单体电池电压值";
CM_ SG_ 770 M32_JumperTemp_Max_Valid "
";
CM_ SG_ 770 M32_Tem_Mean "温度平均值";
CM_ SG_ 770 M32_CellVoltageMean "单体电池电压平均值";
CM_ SG_ 754 M31_Tem_Min_Num "温度值";
CM_ SG_ 754 M31_Tem_Max_Num "温度值";
CM_ SG_ 754 M31_CellVoltageMin_Num "单体电池电压值";
CM_ SG_ 754 M31_CellVoltageMax_Num "单体电池电压值";
CM_ SG_ 754 M31_JumperTemp_Max_Valid "
";
CM_ SG_ 754 M31_Tem_Mean "温度平均值";
CM_ SG_ 754 M31_CellVoltageMean "单体电池电压平均值";
CM_ SG_ 738 M30_Tem_Min_Num "温度值";
CM_ SG_ 738 M30_Tem_Max_Num "温度值";
CM_ SG_ 738 M30_CellVoltageMin_Num "单体电池电压值";
CM_ SG_ 738 M30_CellVoltageMax_Num "单体电池电压值";
CM_ SG_ 738 M30_JumperTemp_Max_Valid "
";
CM_ SG_ 738 M30_Tem_Mean "温度平均值";
CM_ SG_ 738 M30_CellVoltageMean "单体电池电压平均值";
CM_ SG_ 722 M29_Tem_Min_Num "温度值";
CM_ SG_ 722 M29_Tem_Max_Num "温度值";
CM_ SG_ 722 M29_CellVoltageMin_Num "单体电池电压值";
CM_ SG_ 722 M29_CellVoltageMax_Num "单体电池电压值";
CM_ SG_ 722 M29_JumperTemp_Max_Valid "
";
CM_ SG_ 722 M29_Tem_Mean "温度平均值";
CM_ SG_ 722 M29_CellVoltageMean "单体电池电压平均值";
CM_ SG_ 706 M28_Tem_Min_Num "温度值";
CM_ SG_ 706 M28_Tem_Max_Num "温度值";
CM_ SG_ 706 M28_CellVoltageMin_Num "单体电池电压值";
CM_ SG_ 706 M28_CellVoltageMax_Num "单体电池电压值";
CM_ SG_ 706 M28_JumperTemp_Max_Valid "
";
CM_ SG_ 706 M28_Tem_Mean "温度平均值";
CM_ SG_ 706 M28_CellVoltageMean "单体电池电压平均值";
CM_ SG_ 690 M27_Tem_Min_Num "温度值";
CM_ SG_ 690 M27_Tem_Max_Num "温度值";
CM_ SG_ 690 M27_CellVoltageMin_Num "单体电池电压值";
CM_ SG_ 690 M27_CellVoltageMax_Num "单体电池电压值";
CM_ SG_ 690 M27_JumperTemp_Max_Valid "
";
CM_ SG_ 690 M27_Tem_Mean "温度平均值";
CM_ SG_ 690 M27_CellVoltageMean "单体电池电压平均值";
CM_ SG_ 674 M26_Tem_Min_Num "温度值";
CM_ SG_ 674 M26_Tem_Max_Num "温度值";
CM_ SG_ 674 M26_CellVoltageMin_Num "单体电池电压值";
CM_ SG_ 674 M26_CellVoltageMax_Num "单体电池电压值";
CM_ SG_ 674 M26_JumperTemp_Max_Valid "
";
CM_ SG_ 674 M26_Tem_Mean "温度平均值";
CM_ SG_ 674 M26_CellVoltageMean "单体电池电压平均值";
CM_ SG_ 658 M25_Tem_Min_Num "温度值";
CM_ SG_ 658 M25_Tem_Max_Num "温度值";
CM_ SG_ 658 M25_CellVoltageMin_Num "单体电池电压值";
CM_ SG_ 658 M25_CellVoltageMax_Num "单体电池电压值";
CM_ SG_ 658 M25_JumperTemp_Max_Valid "
";
CM_ SG_ 658 M25_Tem_Mean "温度平均值";
CM_ SG_ 658 M25_CellVoltageMean "单体电池电压平均值";
CM_ SG_ 642 M24_Tem_Min_Num "温度值";
CM_ SG_ 642 M24_Tem_Max_Num "温度值";
CM_ SG_ 642 M24_CellVoltageMin_Num "单体电池电压值";
CM_ SG_ 642 M24_CellVoltageMax_Num "单体电池电压值";
CM_ SG_ 642 M24_JumperTemp_Max_Valid "
";
CM_ SG_ 642 M24_Tem_Mean "温度平均值";
CM_ SG_ 642 M24_CellVoltageMean "单体电池电压平均值";
CM_ SG_ 626 M23_Tem_Min_Num "温度值";
CM_ SG_ 626 M23_Tem_Max_Num "温度值";
CM_ SG_ 626 M23_CellVoltageMin_Num "单体电池电压值";
CM_ SG_ 626 M23_CellVoltageMax_Num "单体电池电压值";
CM_ SG_ 626 M23_JumperTemp_Max_Valid "
";
CM_ SG_ 626 M23_Tem_Mean "温度平均值";
CM_ SG_ 626 M23_CellVoltageMean "单体电池电压平均值";
CM_ SG_ 610 M22_Tem_Min_Num "温度值";
CM_ SG_ 610 M22_Tem_Max_Num "温度值";
CM_ SG_ 610 M22_CellVoltageMin_Num "单体电池电压值";
CM_ SG_ 610 M22_CellVoltageMax_Num "单体电池电压值";
CM_ SG_ 610 M22_JumperTemp_Max_Valid "
";
CM_ SG_ 610 M22_Tem_Mean "温度平均值";
CM_ SG_ 610 M22_CellVoltageMean "单体电池电压平均值";
CM_ SG_ 594 M21_Tem_Min_Num "温度值";
CM_ SG_ 594 M21_Tem_Max_Num "温度值";
CM_ SG_ 594 M21_CellVoltageMin_Num "单体电池电压值";
CM_ SG_ 594 M21_CellVoltageMax_Num "单体电池电压值";
CM_ SG_ 594 M21_JumperTemp_Max_Valid "
";
CM_ SG_ 594 M21_Tem_Mean "温度平均值";
CM_ SG_ 594 M21_CellVoltageMean "单体电池电压平均值";
CM_ SG_ 578 M20_Tem_Min_Num "温度值";
CM_ SG_ 578 M20_Tem_Max_Num "温度值";
CM_ SG_ 578 M20_CellVoltageMin_Num "单体电池电压值";
CM_ SG_ 578 M20_CellVoltageMax_Num "单体电池电压值";
CM_ SG_ 578 M20_JumperTemp_Max_Valid "
";
CM_ SG_ 578 M20_Tem_Mean "温度平均值";
CM_ SG_ 578 M20_CellVoltageMean "单体电池电压平均值";
CM_ SG_ 562 M19_Tem_Min_Num "温度值";
CM_ SG_ 562 M19_Tem_Max_Num "温度值";
CM_ SG_ 562 M19_CellVoltageMin_Num "单体电池电压值";
CM_ SG_ 562 M19_CellVoltageMax_Num "单体电池电压值";
CM_ SG_ 562 M19_JumperTemp_Max_Valid "
";
CM_ SG_ 562 M19_Tem_Mean "温度平均值";
CM_ SG_ 562 M19_CellVoltageMean "单体电池电压平均值";
CM_ SG_ 546 M18_Tem_Min_Num "温度值";
CM_ SG_ 546 M18_Tem_Max_Num "温度值";
CM_ SG_ 546 M18_CellVoltageMin_Num "单体电池电压值";
CM_ SG_ 546 M18_CellVoltageMax_Num "单体电池电压值";
CM_ SG_ 546 M18_JumperTemp_Max_Valid "
";
CM_ SG_ 546 M18_Tem_Mean "温度平均值";
CM_ SG_ 546 M18_CellVoltageMean "单体电池电压平均值";
CM_ SG_ 530 M17_Tem_Min_Num "温度值";
CM_ SG_ 530 M17_Tem_Max_Num "温度值";
CM_ SG_ 530 M17_CellVoltageMin_Num "单体电池电压值";
CM_ SG_ 530 M17_CellVoltageMax_Num "单体电池电压值";
CM_ SG_ 530 M17_JumperTemp_Max_Valid "
";
CM_ SG_ 530 M17_Tem_Mean "温度平均值";
CM_ SG_ 530 M17_CellVoltageMean "单体电池电压平均值";
CM_ SG_ 514 M16_Tem_Min_Num "温度值";
CM_ SG_ 514 M16_Tem_Max_Num "温度值";
CM_ SG_ 514 M16_CellVoltageMin_Num "单体电池电压值";
CM_ SG_ 514 M16_CellVoltageMax_Num "单体电池电压值";
CM_ SG_ 514 M16_JumperTemp_Max_Valid "
";
CM_ SG_ 514 M16_Tem_Mean "温度平均值";
CM_ SG_ 514 M16_CellVoltageMean "单体电池电压平均值";
CM_ SG_ 498 M15_Tem_Min_Num "温度值";
CM_ SG_ 498 M15_Tem_Max_Num "温度值";
CM_ SG_ 498 M15_CellVoltageMin_Num "单体电池电压值";
CM_ SG_ 498 M15_CellVoltageMax_Num "单体电池电压值";
CM_ SG_ 498 M15_JumperTemp_Max_Valid "
";
CM_ SG_ 498 M15_Tem_Mean "温度平均值";
CM_ SG_ 498 M15_CellVoltageMean "单体电池电压平均值";
CM_ SG_ 482 M14_Tem_Min_Num "温度值";
CM_ SG_ 482 M14_Tem_Max_Num "温度值";
CM_ SG_ 482 M14_CellVoltageMin_Num "单体电池电压值";
CM_ SG_ 482 M14_CellVoltageMax_Num "单体电池电压值";
CM_ SG_ 482 M14_JumperTemp_Max_Valid "
";
CM_ SG_ 482 M14_Tem_Mean "温度平均值";
CM_ SG_ 482 M14_CellVoltageMean "单体电池电压平均值";
CM_ SG_ 466 M13_Tem_Min_Num "温度值";
CM_ SG_ 466 M13_Tem_Max_Num "温度值";
CM_ SG_ 466 M13_CellVoltageMin_Num "单体电池电压值";
CM_ SG_ 466 M13_CellVoltageMax_Num "单体电池电压值";
CM_ SG_ 466 M13_JumperTemp_Max_Valid "
";
CM_ SG_ 466 M13_Tem_Mean "温度平均值";
CM_ SG_ 466 M13_CellVoltageMean "单体电池电压平均值";
CM_ SG_ 450 M12_Tem_Min_Num "温度值";
CM_ SG_ 450 M12_Tem_Max_Num "温度值";
CM_ SG_ 450 M12_CellVoltageMin_Num "单体电池电压值";
CM_ SG_ 450 M12_CellVoltageMax_Num "单体电池电压值";
CM_ SG_ 450 M12_JumperTemp_Max_Valid "
";
CM_ SG_ 450 M12_Tem_Mean "温度平均值";
CM_ SG_ 450 M12_CellVoltageMean "单体电池电压平均值";
CM_ SG_ 434 M11_Tem_Min_Num "温度值";
CM_ SG_ 434 M11_Tem_Max_Num "温度值";
CM_ SG_ 434 M11_CellVoltageMin_Num "单体电池电压值";
CM_ SG_ 434 M11_CellVoltageMax_Num "单体电池电压值";
CM_ SG_ 434 M11_JumperTemp_Max_Valid "
";
CM_ SG_ 434 M11_Tem_Mean "温度平均值";
CM_ SG_ 434 M11_CellVoltageMean "单体电池电压平均值";
CM_ SG_ 418 M10_Tem_Min_Num "温度值";
CM_ SG_ 418 M10_Tem_Max_Num "温度值";
CM_ SG_ 418 M10_CellVoltageMin_Num "单体电池电压值";
CM_ SG_ 418 M10_CellVoltageMax_Num "单体电池电压值";
CM_ SG_ 418 M10_JumperTemp_Max_Valid "
";
CM_ SG_ 418 M10_Tem_Mean "温度平均值";
CM_ SG_ 418 M10_CellVoltageMean "单体电池电压平均值";
CM_ SG_ 402 M9_Tem_Min_Num "温度值";
CM_ SG_ 402 M9_Tem_Max_Num "温度值";
CM_ SG_ 402 M9_CellVoltageMin_Num "单体电池电压值";
CM_ SG_ 402 M9_CellVoltageMax_Num "单体电池电压值";
CM_ SG_ 402 M9_JumperTemp_Max_Valid "
";
CM_ SG_ 402 M9_Tem_Mean "温度平均值";
CM_ SG_ 402 M9_CellVoltageMean "单体电池电压平均值";
CM_ SG_ 386 M8_Tem_Min_Num "温度值";
CM_ SG_ 386 M8_Tem_Max_Num "温度值";
CM_ SG_ 386 M8_CellVoltageMin_Num "单体电池电压值";
CM_ SG_ 386 M8_CellVoltageMax_Num "单体电池电压值";
CM_ SG_ 386 M8_JumperTemp_Max_Valid "
";
CM_ SG_ 386 M8_Tem_Mean "温度平均值";
CM_ SG_ 386 M8_CellVoltageMean "单体电池电压平均值";
CM_ SG_ 370 M7_Tem_Min_Num "温度值";
CM_ SG_ 370 M7_Tem_Max_Num "温度值";
CM_ SG_ 370 M7_CellVoltageMin_Num "单体电池电压值";
CM_ SG_ 370 M7_CellVoltageMax_Num "单体电池电压值";
CM_ SG_ 370 M7_JumperTemp_Max_Valid "
";
CM_ SG_ 370 M7_Tem_Mean "温度平均值";
CM_ SG_ 370 M7_CellVoltageMean "单体电池电压平均值";
CM_ SG_ 354 M6_Tem_Min_Num "温度值";
CM_ SG_ 354 M6_Tem_Max_Num "温度值";
CM_ SG_ 354 M6_CellVoltageMin_Num "单体电池电压值";
CM_ SG_ 354 M6_CellVoltageMax_Num "单体电池电压值";
CM_ SG_ 354 M6_JumperTemp_Max_Valid "
";
CM_ SG_ 354 M6_Tem_Mean "温度平均值";
CM_ SG_ 354 M6_CellVoltageMean "单体电池电压平均值";
CM_ SG_ 338 M5_Tem_Min_Num "温度值";
CM_ SG_ 338 M5_Tem_Max_Num "温度值";
CM_ SG_ 338 M5_CellVoltageMin_Num "单体电池电压值";
CM_ SG_ 338 M5_CellVoltageMax_Num "单体电池电压值";
CM_ SG_ 338 M5_JumperTemp_Max_Valid "
";
CM_ SG_ 338 M5_Tem_Mean "温度平均值";
CM_ SG_ 338 M5_CellVoltageMean "单体电池电压平均值";
CM_ SG_ 322 M4_Tem_Min_Num "温度值";
CM_ SG_ 322 M4_Tem_Max_Num "温度值";
CM_ SG_ 322 M4_CellVoltageMin_Num "单体电池电压值";
CM_ SG_ 322 M4_CellVoltageMax_Num "单体电池电压值";
CM_ SG_ 322 M4_JumperTemp_Max_Valid "
";
CM_ SG_ 322 M4_Tem_Mean "温度平均值";
CM_ SG_ 322 M4_CellVoltageMean "单体电池电压平均值";
CM_ SG_ 306 M3_Tem_Min_Num "温度值";
CM_ SG_ 306 M3_Tem_Max_Num "温度值";
CM_ SG_ 306 M3_CellVoltageMin_Num "单体电池电压值";
CM_ SG_ 306 M3_CellVoltageMax_Num "单体电池电压值";
CM_ SG_ 306 M3_JumperTemp_Max_Valid "
";
CM_ SG_ 306 M3_Tem_Mean "温度平均值";
CM_ SG_ 306 M3_CellVoltageMean "单体电池电压平均值";
CM_ SG_ 290 M2_Tem_Min_Num "温度值";
CM_ SG_ 290 M2_Tem_Max_Num "温度值";
CM_ SG_ 290 M2_CellVoltageMin_Num "单体电池电压值";
CM_ SG_ 290 M2_CellVoltageMax_Num "单体电池电压值";
CM_ SG_ 290 M2_JumperTemp_Max_Valid "
";
CM_ SG_ 290 M2_Tem_Mean "温度平均值";
CM_ SG_ 290 M2_CellVoltageMean "单体电池电压平均值";
CM_ SG_ 257 Local_Volt_CellBalance "单体电池电压最小值";
CM_ SG_ 257 Local_InnerControl_Balance "模块内部均衡指令";
BA_DEF_ SG_  "GenSigStartValue" FLOAT 0 0;
BA_DEF_ SG_  "GenSigSendType" ENUM  "NotUsed","NotUsed","NotUsed","NotUsed","OnChangeWithRepetition","NotUsed","IfActiveWithRepetition","NoSigSendType","NotUsed","NotUsed";
BA_DEF_ BO_  "GenMsgCycleTime" INT 0 65535;
BA_DEF_ BO_  "GenMsgILSupport" ENUM  "No","Yes";
BA_DEF_ BO_  "GenMsgSendType" ENUM  "Cyclic","NotUsed","NotUsed","NotUsed","NotUsed","NotUsed","NotUsed","NotUsed","NoMsgSendType","NotUsed","vector_leerstring";
BA_DEF_ BU_  "ILUsed" ENUM  "No","Yes";
BA_DEF_  "Manufacturer" STRING ;
BA_DEF_  "BusType" STRING ;
BA_DEF_DEF_  "GenSigStartValue" 0;
BA_DEF_DEF_  "GenSigSendType" "NoSigSendType";
BA_DEF_DEF_  "GenMsgCycleTime" 0;
BA_DEF_DEF_  "GenMsgILSupport" "Yes";
BA_DEF_DEF_  "GenMsgSendType" "NoMsgSendType";
BA_DEF_DEF_  "ILUsed" "Yes";
BA_DEF_DEF_  "Manufacturer" "Vector";
BA_DEF_DEF_  "BusType" "";
BA_ "BusType" "CAN";
BA_ "GenMsgSendType" BO_ 111 0;
BA_ "GenMsgCycleTime" BO_ 111 1000;
BA_ "GenMsgCycleTime" BO_ 101 1000;
BA_ "GenMsgSendType" BO_ 101 0;
BA_ "GenMsgCycleTime" BO_ 100 1000;
BA_ "GenMsgSendType" BO_ 100 0;
BA_ "GenMsgSendType" BO_ 261 0;
BA_ "GenMsgCycleTime" BO_ 261 100;
BA_ "GenMsgCycleTime" BO_ 1520 10;
BA_ "GenMsgSendType" BO_ 1520 0;
BA_ "GenMsgCycleTime" BO_ 1320 10;
BA_ "GenMsgSendType" BO_ 1320 0;
BA_ "GenMsgCycleTime" BO_ 1316 10;
BA_ "GenMsgSendType" BO_ 1316 0;
BA_ "GenMsgCycleTime" BO_ 1315 10;
BA_ "GenMsgSendType" BO_ 1315 0;
BA_ "GenMsgCycleTime" BO_ 1314 10;
BA_ "GenMsgSendType" BO_ 1314 0;
BA_ "GenMsgCycleTime" BO_ 1317 10;
BA_ "GenMsgSendType" BO_ 1317 0;
BA_ "GenMsgCycleTime" BO_ 1313 10;
BA_ "GenMsgSendType" BO_ 1313 0;
BA_ "GenMsgSendType" BO_ 260 0;
BA_ "GenMsgCycleTime" BO_ 260 1000;
BA_ "GenMsgSendType" BO_ 259 0;
BA_ "GenMsgCycleTime" BO_ 259 1000;
BA_ "GenMsgCycleTime" BO_ 258 100;
BA_ "GenMsgSendType" BO_ 258 0;
BA_ "GenMsgSendType" BO_ 1537 0;
BA_ "GenMsgCycleTime" BO_ 1537 10000;
BA_ "GenMsgCycleTime" BO_ 274 100;
BA_ "GenMsgSendType" BO_ 274 0;
BA_ "GenMsgCycleTime" BO_ 332 1000;
BA_ "GenMsgSendType" BO_ 332 0;
BA_ "GenMsgCycleTime" BO_ 331 1000;
BA_ "GenMsgSendType" BO_ 331 0;
BA_ "GenMsgCycleTime" BO_ 330 1000;
BA_ "GenMsgSendType" BO_ 330 0;
BA_ "GenMsgCycleTime" BO_ 316 1000;
BA_ "GenMsgSendType" BO_ 316 0;
BA_ "GenMsgCycleTime" BO_ 315 1000;
BA_ "GenMsgSendType" BO_ 315 0;
BA_ "GenMsgCycleTime" BO_ 314 1000;
BA_ "GenMsgSendType" BO_ 314 0;
BA_ "GenMsgCycleTime" BO_ 300 1000;
BA_ "GenMsgSendType" BO_ 300 0;
BA_ "GenMsgCycleTime" BO_ 299 1000;
BA_ "GenMsgSendType" BO_ 299 0;
BA_ "GenMsgCycleTime" BO_ 298 1000;
BA_ "GenMsgSendType" BO_ 298 0;
BA_ "GenMsgCycleTime" BO_ 706 100;
BA_ "GenMsgSendType" BO_ 706 0;
BA_ "GenMsgCycleTime" BO_ 690 100;
BA_ "GenMsgSendType" BO_ 690 0;
BA_ "GenMsgCycleTime" BO_ 674 100;
BA_ "GenMsgSendType" BO_ 674 0;
BA_ "GenMsgCycleTime" BO_ 658 100;
BA_ "GenMsgSendType" BO_ 658 0;
BA_ "GenMsgCycleTime" BO_ 642 100;
BA_ "GenMsgSendType" BO_ 642 0;
BA_ "GenMsgCycleTime" BO_ 626 100;
BA_ "GenMsgSendType" BO_ 626 0;
BA_ "GenMsgCycleTime" BO_ 610 100;
BA_ "GenMsgSendType" BO_ 610 0;
BA_ "GenMsgCycleTime" BO_ 594 100;
BA_ "GenMsgSendType" BO_ 594 0;
BA_ "GenMsgCycleTime" BO_ 578 100;
BA_ "GenMsgSendType" BO_ 578 0;
BA_ "GenMsgCycleTime" BO_ 562 100;
BA_ "GenMsgSendType" BO_ 562 0;
BA_ "GenMsgCycleTime" BO_ 546 100;
BA_ "GenMsgSendType" BO_ 546 0;
BA_ "GenMsgCycleTime" BO_ 530 100;
BA_ "GenMsgSendType" BO_ 530 0;
BA_ "GenMsgCycleTime" BO_ 514 100;
BA_ "GenMsgSendType" BO_ 514 0;
BA_ "GenMsgCycleTime" BO_ 498 100;
BA_ "GenMsgSendType" BO_ 498 0;
BA_ "GenMsgCycleTime" BO_ 482 100;
BA_ "GenMsgSendType" BO_ 482 0;
BA_ "GenMsgCycleTime" BO_ 466 100;
BA_ "GenMsgSendType" BO_ 466 0;
BA_ "GenMsgCycleTime" BO_ 450 100;
BA_ "GenMsgSendType" BO_ 450 0;
BA_ "GenMsgCycleTime" BO_ 434 100;
BA_ "GenMsgSendType" BO_ 434 0;
BA_ "GenMsgCycleTime" BO_ 418 100;
BA_ "GenMsgSendType" BO_ 418 0;
BA_ "GenMsgCycleTime" BO_ 402 100;
BA_ "GenMsgSendType" BO_ 402 0;
BA_ "GenMsgCycleTime" BO_ 386 100;
BA_ "GenMsgSendType" BO_ 386 0;
BA_ "GenMsgCycleTime" BO_ 370 100;
BA_ "GenMsgSendType" BO_ 370 0;
BA_ "GenMsgCycleTime" BO_ 354 100;
BA_ "GenMsgSendType" BO_ 354 0;
BA_ "GenMsgCycleTime" BO_ 338 100;
BA_ "GenMsgSendType" BO_ 338 0;
BA_ "GenMsgCycleTime" BO_ 322 100;
BA_ "GenMsgSendType" BO_ 322 0;
BA_ "GenMsgCycleTime" BO_ 306 100;
BA_ "GenMsgSendType" BO_ 306 0;
BA_ "GenMsgCycleTime" BO_ 290 100;
BA_ "GenMsgSendType" BO_ 290 0;
BA_ "GenMsgCycleTime" BO_ 284 1000;
BA_ "GenMsgSendType" BO_ 284 0;
BA_ "GenMsgCycleTime" BO_ 333 1000;
BA_ "GenMsgSendType" BO_ 333 0;
BA_ "GenMsgCycleTime" BO_ 317 1000;
BA_ "GenMsgSendType" BO_ 317 0;
BA_ "GenMsgCycleTime" BO_ 301 1000;
BA_ "GenMsgSendType" BO_ 301 0;
BA_ "GenMsgCycleTime" BO_ 285 1000;
BA_ "GenMsgSendType" BO_ 285 0;
BA_ "GenMsgSendType" BO_ 79 0;
BA_ "GenMsgCycleTime" BO_ 79 1000;
BA_ "GenMsgCycleTime" BO_ 257 1000;
BA_ "GenMsgCycleTime" BO_ 90 10000;
BA_ "GenMsgSendType" BO_ 90 0;
BA_ "GenMsgCycleTime" BO_ 95 10000;
BA_ "GenMsgSendType" BO_ 95 0;
BA_ "GenMsgILSupport" BO_ 2 0;
BA_ "GenMsgILSupport" BO_ 1 0;
BA_ "GenMsgSendType" BO_ 93 0;
BA_ "GenMsgCycleTime" BO_ 93 1000;
BA_ "GenMsgSendType" BO_ 92 0;
BA_ "GenMsgCycleTime" BO_ 92 10000;
BA_ "GenMsgSendType" BO_ 91 0;
BA_ "GenMsgCycleTime" BO_ 91 10000;
BA_ "GenMsgSendType" BO_ 89 0;
BA_ "GenMsgCycleTime" BO_ 89 10000;
BA_ "GenMsgSendType" BO_ 88 0;
BA_ "GenMsgCycleTime" BO_ 88 1000;
BA_ "GenMsgSendType" BO_ 87 0;
BA_ "GenMsgCycleTime" BO_ 87 10000;
BA_ "GenMsgSendType" BO_ 86 0;
BA_ "GenMsgCycleTime" BO_ 86 1000;
BA_ "GenMsgSendType" BO_ 85 0;
BA_ "GenMsgCycleTime" BO_ 85 10000;
BA_ "GenMsgSendType" BO_ 84 0;
BA_ "GenMsgCycleTime" BO_ 84 1000;
BA_ "GenMsgSendType" BO_ 83 0;
BA_ "GenMsgCycleTime" BO_ 83 1000;
BA_ "GenMsgSendType" BO_ 82 0;
BA_ "GenMsgCycleTime" BO_ 82 100;
BA_ "GenMsgSendType" BO_ 81 0;
BA_ "GenMsgCycleTime" BO_ 81 1000;
BA_ "GenMsgSendType" BO_ 80 0;
BA_ "GenMsgCycleTime" BO_ 80 1000;
BA_ "GenMsgCycleTime" BO_ 512 100;
BA_ "GenMsgSendType" BO_ 512 0;
BA_ "GenMsgCycleTime" BO_ 528 100;
BA_ "GenMsgSendType" BO_ 528 0;
BA_ "GenMsgCycleTime" BO_ 544 100;
BA_ "GenMsgSendType" BO_ 544 0;
BA_ "GenMsgCycleTime" BO_ 560 100;
BA_ "GenMsgSendType" BO_ 560 0;
BA_ "GenMsgCycleTime" BO_ 576 100;
BA_ "GenMsgSendType" BO_ 576 0;
BA_ "GenMsgCycleTime" BO_ 592 100;
BA_ "GenMsgSendType" BO_ 592 0;
BA_ "GenSigStartValue" SG_ 101 Local_Curr_Bus_Copy_3 32000;
BA_ "GenSigStartValue" SG_ 101 Local_Curr_Bus_Copy_2 32000;
BA_ "GenSigStartValue" SG_ 101 Local_Curr_Bus_Copy_1 32000;
BA_ "GenSigStartValue" SG_ 101 Local_Curr_Bus 32000;
BA_ "GenSigStartValue" SG_ 100 Local_Curr_Bus_Copy_3 32000;
BA_ "GenSigStartValue" SG_ 100 Local_Curr_Bus_Copy_2 32000;
BA_ "GenSigStartValue" SG_ 100 Local_Curr_Bus_Copy_1 32000;
BA_ "GenSigStartValue" SG_ 100 Local_Curr_Bus 32000;
BA_ "GenSigStartValue" SG_ 81 Local_Curr_Bus 32000;
VAL_ 3221225472 Local_CtrFb_PosConnector 1 "Open" 0 "Close" ;
VAL_ 3221225472 Local_CtrFb_NegConnector 1 "Open" 0 "Close" ;
VAL_ 3221225472 Local_CtrFb_FcgConnector 1 "Open" 0 "Close" ;
VAL_ 3221225472 Local_CtrFb_ChgConnector 1 "Open" 0 "Close" ;
VAL_ 3221225472 Local_CtrFb_PreChgConnector 1 "Open" 0 "Close" ;
VAL_ 261 External_Sleep_Cmd 170 "Sleep_Cmd_On" ;
VAL_ 261 External_Fcg_Cmd 170 "Fcg_Cmd_On" ;
VAL_ 259 DisCharge_Heating_cmd 255 "停止加热" 170 "边加热边放电" 16 "只加热" ;
VAL_ 259 Charge_Heating_cmd 255 "停止加热" 48 "请求电流90A" 32 "请求电流30A" 16 "启动加热" ;
VAL_ 258 Emergency_Running_Cmd 255 "无效" 170 "上电" 0 "下电" ;
VAL_ 258 Emergency_PowerON_Cmd 255 "无效" 170 "上电" 0 "下电" ;
VAL_ 274 M1_Heating_OverTemp_Flag 1 "High" 0 "Normal" ;
VAL_ 274 M1_TempFault 1 "Error" 0 "Normal" ;
VAL_ 274 M1_BalanceFailure 1 "failure" 0 "normal" ;
VAL_ 770 M32_Heating_OverTemp_Flag 1 "High" 0 "Normal" ;
VAL_ 770 M32_TempFault 1 "Error" 0 "Normal" ;
VAL_ 770 M32_BalanceFailure 1 "failure" 0 "normal" ;
VAL_ 754 M31_Heating_OverTemp_Flag 1 "High" 0 "Normal" ;
VAL_ 754 M31_TempFault 1 "Error" 0 "Normal" ;
VAL_ 754 M31_BalanceFailure 1 "failure" 0 "normal" ;
VAL_ 738 M30_Heating_OverTemp_Flag 1 "High" 0 "Normal" ;
VAL_ 738 M30_TempFault 1 "Error" 0 "Normal" ;
VAL_ 738 M30_BalanceFailure 1 "failure" 0 "normal" ;
VAL_ 722 M29_Heating_OverTemp_Flag 1 "High" 0 "Normal" ;
VAL_ 722 M29_TempFault 1 "Error" 0 "Normal" ;
VAL_ 722 M29_BalanceFailure 1 "failure" 0 "normal" ;
VAL_ 706 M28_Heating_OverTemp_Flag 1 "High" 0 "Normal" ;
VAL_ 706 M28_TempFault 1 "Error" 0 "Normal" ;
VAL_ 706 M28_BalanceFailure 1 "failure" 0 "normal" ;
VAL_ 690 M27_Heating_OverTemp_Flag 1 "High" 0 "Normal" ;
VAL_ 690 M27_TempFault 1 "Error" 0 "Normal" ;
VAL_ 690 M27_BalanceFailure 1 "failure" 0 "normal" ;
VAL_ 674 M26_Heating_OverTemp_Flag 1 "High" 0 "Normal" ;
VAL_ 674 M26_TempFault 1 "Error" 0 "Normal" ;
VAL_ 674 M26_BalanceFailure 1 "failure" 0 "normal" ;
VAL_ 658 M25_Heating_OverTemp_Flag 1 "High" 0 "Normal" ;
VAL_ 658 M25_TempFault 1 "Error" 0 "Normal" ;
VAL_ 658 M25_BalanceFailure 1 "failure" 0 "normal" ;
VAL_ 642 M24_Heating_OverTemp_Flag 1 "High" 0 "Normal" ;
VAL_ 642 M24_TempFault 1 "Error" 0 "Normal" ;
VAL_ 642 M24_BalanceFailure 1 "failure" 0 "normal" ;
VAL_ 626 M23_Heating_OverTemp_Flag 1 "High" 0 "Normal" ;
VAL_ 626 M23_TempFault 1 "Error" 0 "Normal" ;
VAL_ 626 M23_BalanceFailure 1 "failure" 0 "normal" ;
VAL_ 610 M22_Heating_OverTemp_Flag 1 "High" 0 "Normal" ;
VAL_ 610 M22_TempFault 1 "Error" 0 "Normal" ;
VAL_ 610 M22_BalanceFailure 1 "failure" 0 "normal" ;
VAL_ 594 M21_Heating_OverTemp_Flag 1 "High" 0 "Normal" ;
VAL_ 594 M21_TempFault 1 "Error" 0 "Normal" ;
VAL_ 594 M21_BalanceFailure 1 "failure" 0 "normal" ;
VAL_ 578 M20_Heating_OverTemp_Flag 1 "High" 0 "Normal" ;
VAL_ 578 M20_TempFault 1 "Error" 0 "Normal" ;
VAL_ 578 M20_BalanceFailure 1 "failure" 0 "normal" ;
VAL_ 562 M19_Heating_OverTemp_Flag 1 "High" 0 "Normal" ;
VAL_ 562 M19_TempFault 1 "Error" 0 "Normal" ;
VAL_ 562 M19_BalanceFailure 1 "failure" 0 "normal" ;
VAL_ 546 M18_Heating_OverTemp_Flag 1 "High" 0 "Normal" ;
VAL_ 546 M18_TempFault 1 "Error" 0 "Normal" ;
VAL_ 546 M18_BalanceFailure 1 "failure" 0 "normal" ;
VAL_ 530 M17_Heating_OverTemp_Flag 1 "High" 0 "Normal" ;
VAL_ 530 M17_TempFault 1 "Error" 0 "Normal" ;
VAL_ 530 M17_BalanceFailure 1 "failure" 0 "normal" ;
VAL_ 514 M16_Heating_OverTemp_Flag 1 "High" 0 "Normal" ;
VAL_ 514 M16_TempFault 1 "Error" 0 "Normal" ;
VAL_ 514 M16_BalanceFailure 1 "failure" 0 "normal" ;
VAL_ 498 M15_Heating_OverTemp_Flag 1 "High" 0 "Normal" ;
VAL_ 498 M15_TempFault 1 "Error" 0 "Normal" ;
VAL_ 498 M15_BalanceFailure 1 "failure" 0 "normal" ;
VAL_ 482 M14_Heating_OverTemp_Flag 1 "High" 0 "Normal" ;
VAL_ 482 M14_TempFault 1 "Error" 0 "Normal" ;
VAL_ 482 M14_BalanceFailure 1 "failure" 0 "normal" ;
VAL_ 466 M13_Heating_OverTemp_Flag 1 "High" 0 "Normal" ;
VAL_ 466 M13_TempFault 1 "Error" 0 "Normal" ;
VAL_ 466 M13_BalanceFailure 1 "failure" 0 "normal" ;
VAL_ 450 M12_Heating_OverTemp_Flag 1 "High" 0 "Normal" ;
VAL_ 450 M12_TempFault 1 "Error" 0 "Normal" ;
VAL_ 450 M12_BalanceFailure 1 "failure" 0 "normal" ;
VAL_ 434 M11_Heating_OverTemp_Flag 1 "High" 0 "Normal" ;
VAL_ 434 M11_TempFault 1 "Error" 0 "Normal" ;
VAL_ 434 M11_BalanceFailure 1 "failure" 0 "normal" ;
VAL_ 418 M10_Heating_OverTemp_Flag 1 "High" 0 "Normal" ;
VAL_ 418 M10_TempFault 1 "Error" 0 "Normal" ;
VAL_ 418 M10_BalanceFailure 1 "failure" 0 "normal" ;
VAL_ 402 M9_Heating_OverTemp_Flag 1 "High" 0 "Normal" ;
VAL_ 402 M9_TempFault 1 "Error" 0 "Normal" ;
VAL_ 402 M9_BalanceFailure 1 "failure" 0 "normal" ;
VAL_ 386 M8_Heating_OverTemp_Flag 1 "High" 0 "Normal" ;
VAL_ 386 M8_TempFault 1 "Error" 0 "Normal" ;
VAL_ 386 M8_BalanceFailure 1 "failure" 0 "normal" ;
VAL_ 370 M7_Heating_OverTemp_Flag 1 "High" 0 "Normal" ;
VAL_ 370 M7_TempFault 1 "Error" 0 "Normal" ;
VAL_ 370 M7_BalanceFailure 1 "failure" 0 "normal" ;
VAL_ 354 M6_Heating_OverTemp_Flag 1 "High" 0 "Normal" ;
VAL_ 354 M6_TempFault 1 "Error" 0 "Normal" ;
VAL_ 354 M6_BalanceFailure 1 "failure" 0 "normal" ;
VAL_ 338 M5_Heating_OverTemp_Flag 1 "High" 0 "Normal" ;
VAL_ 338 M5_TempFault 1 "Error" 0 "Normal" ;
VAL_ 338 M5_BalanceFailure 1 "failure" 0 "normal" ;
VAL_ 322 M4_Heating_OverTemp_Flag 1 "High" 0 "Normal" ;
VAL_ 322 M4_TempFault 1 "Error" 0 "Normal" ;
VAL_ 322 M4_BalanceFailure 1 "failure" 0 "normal" ;
VAL_ 306 M3_Heating_OverTemp_Flag 1 "High" 0 "Normal" ;
VAL_ 306 M3_TempFault 1 "Error" 0 "Normal" ;
VAL_ 306 M3_BalanceFailure 1 "failure" 0 "normal" ;
VAL_ 290 M2_Heating_OverTemp_Flag 1 "High" 0 "Normal" ;
VAL_ 290 M2_TempFault 1 "Error" 0 "Normal" ;
VAL_ 290 M2_BalanceFailure 1 "failure" 0 "normal" ;
VAL_ 79 Local_Err_BMUTempSensor 3 "EPO" 2 "Alarm" 1 "Warning" 0 "Normal" ;
VAL_ 79 Local_Err_LECUTempSensor 3 "EPO" 2 "Alarm" 1 "Warning" 0 "Normal" ;
VAL_ 79 Local_Err_PackVoltMismatch 3 "EPO" 2 "Alarm" 1 "Warning" 0 "Normal" ;
VAL_ 79 Local_Err_Smoke_Alarm 3 "EPO" 2 "Alarm" 1 "Warning" 0 "Normal" ;
VAL_ 79 Local_Err_FcgConnector 3 "EPO" 2 "Alarm" 1 "Warning" 0 "Normal" ;
VAL_ 79 Local_Err_ChgConnector 3 "EPO" 2 "Alarm" 1 "Warning" 0 "Normal" ;
VAL_ 79 Local_Err_ChargerFail 3 "EPO" 2 "Alarm" 1 "Warning" 0 "Normal" ;
VAL_ 79 Local_Err_ChgCurrMismatch 3 "EPO" 2 "Alarm" 1 "Warning" 0 "Normal" ;
VAL_ 79 Local_BMS_FaultLevel 3 "EPO" 2 "Alarm" 1 "Warning" 0 "Normal" ;
VAL_ 1791 Calib_Volt_NewId_Num 1023 "10串电压" 511 "9串电压" 255 "8串电压" 127 "7串电压" 63 "6串电压" 31 "5串电压" 15 "4串电压" 4095 "12串电压" 2047 "11串电压" 7 "3串电压" 3 "2串电压" 1 "1串电压" 0 "标定锁定" ;
VAL_ 1791 Calib_Tem_Num 255 "8路温度" 127 "7路温度" 63 "6路温度" 31 "5路温度" 15 "4路温度" 7 "3路温度" 3 "2路温度" 1 "1路温度" 0 "标定锁定" ;
VAL_ 1791 Calib_LecuId 15 "15号LECU" 14 "14号LECU" 13 "13号LECU" 12 "12号LECU" 11 "11号LECU" 10 "10号LECU" 9 "9号LECU" 8 "8号LECU" 7 "7号LECU" 6 "6号LECU" 5 "5号LECU" 4 "4号LECU" 3 "3号LECU" 2 "2号LECU" 1 "1号LECU" ;
VAL_ 1791 Calib_Type_CMD 224 "LECU型号" ;
VAL_ 1791 Calib_Volt_ID_CMD 241 "锁定电压路数" 240 "锁定ID" 12 "标定电压路数" 10 "标定ID" ;
VAL_ 257 Local_InnerControl_Balance 1 "执行" 0 "停止" ;
VAL_ 5 gParaTxEnable 170 "enable" 0 "disable" ;
VAL_ 5 gParaReflashEnable 170 "enable" 0 "disable" ;
VAL_ 5 gParaModeCmd 170 "enable" 0 "disable" ;
VAL_ 5 gParaModeAddr 225 "VIN15_17" 224 "VIN12_14" 255 "LaunchTime" 254 "TotalRunTime" 248 "DcA" 247 "ChA" 242 "Integ_SOC" 240 "SOC" ;
VAL_ 6 Local_ClockCMD 10 "Save" 5 "Enable" 0 "Disable" ;
VAL_ 91 Local_proClientCode 5 "上海申沃" 4 "江西百路佳" 3 "上海万象" 2 "南京金龙" 1 "上海申龙" 0 "其它" 11 "上汽" 22 "东风" ;
VAL_ 91 Local_proProjectStage 84 "临时方案" 80 "平台" 79 "其它" 69 "内部试验" 66 "量产" 65 "样件" ;
VAL_ 91 Local_proProductSeries 2 "乘用车BMS" 1 "商用车BMS" 0 "其它BMS" ;
VAL_ 88 Local_CtrChk_PreConnector 3 "Weld" 2 "Fail" 1 "Open" 0 "Close" ;
VAL_ 88 Local_CtrChk_NegConnector 3 "Weld" 2 "Fail" 1 "Open" 0 "Close" ;
VAL_ 88 Local_CtrChk_FcgConnector 3 "Weld" 2 "Fail" 1 "Open" 0 "Close" ;
VAL_ 88 Local_CtrChk_ChgConnector 3 "Weld" 2 "Fail" 1 "Open" 0 "Close" ;
VAL_ 88 Local_CtrChk_PosConnector 3 "Weld" 2 "Fail" 1 "Open" 0 "Close" ;
VAL_ 88 Local_CtrFb_HVIL_Dch 1 "Open" 0 "Close" ;
VAL_ 88 Local_CtrFb_HVIL_Chg 1 "Open" 0 "Close" ;
VAL_ 88 Local_Ctr_IsoPosAd 1 "Close" 0 "Open" ;
VAL_ 88 Local_Ctr_IsoNegAd 1 "Close" 0 "Open" ;
VAL_ 88 Local_Ctr_HVILVcc 1 "Close" 0 "Open" ;
VAL_ 88 Local_CtrFb_PWMOut_L1 1 "Open" 0 "Close" ;
VAL_ 88 Local_CtrFb_PowerL2 1 "Open" 0 "Close" ;
VAL_ 88 Local_CtrFb_PowerL1 1 "Open" 0 "Close" ;
VAL_ 88 Local_CtrFb_Output_L1 1 "Open" 0 "Close" ;
VAL_ 88 Local_CtrFb_Output_H1 1 "Open" 0 "Close" ;
VAL_ 88 Local_Ctr_PWMOut_L1 1 "Close" 0 "Open" ;
VAL_ 88 Local_OlStatus_VCU 0 "Offline" 1 "Online" ;
VAL_ 88 Local_Ctr_PowerL2 1 "Close" 0 "Open" ;
VAL_ 88 Local_Ctr_ChgConnector 1 "Close" 0 "Open" ;
VAL_ 88 Local_OlStatus_IVT 0 "Offline" 1 "Online" ;
VAL_ 88 Local_KeyMode 5 "KEY_ERR" 4 "ACC_MODE" 3 "FCG_MODE" 2 "CHG_MODE" 1 "DCH_MODE" 0 "KEY_OFF" ;
VAL_ 88 Local_OlStatus_LECU 0 "Offline" 1 "Online" ;
VAL_ 88 Local_OlStatus_Insulation 0 "Offline" 1 "Online" ;
VAL_ 88 Local_OlStatus_Fcg 0 "Offline" 1 "Online" ;
VAL_ 88 Local_Status_BMS 15 "sysDchDone_Mode" 8 "sysAccDone_Mode" 5 "sysAccEnter_Mode" 3 "sysStandby_Mode" 100 "sysPowerOff_Mode" 50 "sysFault_Mode" 40 "sysBalance_Mode" 35 "sysFcgDone_Mode" 34 "sysFcgStop_Mode" 33 "sysFcging_Mode" 32 "sysFcgPreCh_Mode" 31 "sysFcgReady_Mode" 30 "sysFcgEnter_Mode" 25 "sysChgDone_Mode" 24 "sysChgStop_Mode" 23 "sysChging_Mode" 22 "sysChgPreCh_Mode" 21 "sysChgReady_Mode " 20 "sysChgEnter_Mode" 14 "sysDchStop_Mode " 13 "sysDching_Mode" 12 "sysDchPreCh_Mode" 11 "sysDchReady_Mode" 10 "sysDchEnter_Mode" 2 "sysSC_Pass" 1 "sysSC_Mode" 0 "sysInit_Mode " ;
VAL_ 88 Local_CtrFb_LecuPower 1 "Open" 0 "Close" ;
VAL_ 88 Local_Ctr_FcgConnector 1 "Close" 0 "Open" ;
VAL_ 88 Local_Ctr_PreChgConnector 1 "Close" 0 "Open" ;
VAL_ 88 Local_Ctr_NegConnector 1 "Close" 0 "Open" ;
VAL_ 88 Local_Ctr_PosConnector 1 "Close" 0 "Open" ;
VAL_ 88 Local_Ctr_HvpAd 1 "Close" 0 "Open" ;
VAL_ 88 Local_Ctr_HvbAd 1 "Close" 0 "Open" ;
VAL_ 88 Local_Ctr_PowerLock 1 "Close" 0 "Open" ;
VAL_ 88 Local_Ctr_LecuPower 1 "Close" 0 "Open" ;
VAL_ 88 Local_Ctr_Output_L1 1 "Close" 0 "Open" ;
VAL_ 88 Local_Ctr_PowerL1 1 "Close" 0 "Open" ;
VAL_ 88 Local_Ctr_Output_H1 1 "Close" 0 "Open" ;
VAL_ 88 Local_Ctr_FQPower 1 "Close" 0 "Open" ;
VAL_ 83 Local_Sck_SelfCheckResult 0 "Pass" 1 "Fail" ;
VAL_ 83 Local_Sck_CurrValue 0 "Pass" 1 "Fail" ;
VAL_ 83 Local_Sck_CurrSensor 0 "Pass" 1 "Fail" ;
VAL_ 83 Local_Sck_PackVolt 0 "Pass" 1 "Fail" ;
VAL_ 83 Local_Sck_Iso 0 "Pass" 1 "Fail" ;
VAL_ 83 Local_Sck_StoVolt 0 "Pass" 1 "Fail" ;
VAL_ 80 Local_Err_TimeSequence 3 "EPO" 2 "Alarm" 1 "Warning" 0 "Normal" ;
VAL_ 80 Local_Err_InertiaSwitchFail 3 "EPO" 2 "Alarm" 1 "Warning" 0 "Normal" ;
VAL_ 80 Local_Err_Hvil_B 3 "EPO" 2 "Alarm" 1 "Warning" 0 "Normal" ;
VAL_ 80 Local_Err_IVTTempHigh 3 "EPO" 2 "Alarm" 1 "Warning" 0 "Normal" ;
VAL_ 80 Local_Err_JumperTempHigh 3 "EPO" 2 "Alarm" 1 "Warning" 0 "Normal" ;
VAL_ 80 Local_Err_StoVolt 3 "EPO" 2 "Alarm" 1 "Warning" 0 "Normal" ;
VAL_ 80 Local_Err_LECU6803 3 "EPO" 2 "Alarm" 1 "Warning" 0 "Normal" ;
VAL_ 80 Local_Err_VcuIsoLow 3 "EPO" 2 "Alarm" 1 "Warning" 0 "Normal" ;
VAL_ 80 Local_Err_ChgCANLost 3 "EPO" 2 "Alarm" 1 "Warning" 0 "Normal" ;
VAL_ 80 Local_Err_BalanceFail 3 "EPO" 2 "Alarm" 1 "Warning" 0 "Normal" ;
VAL_ 80 Local_Err_SelfcheckFail 3 "EPO" 2 "Alarm" 1 "Warning" 0 "Normal" ;
VAL_ 80 Local_Err_PreChargeFail 3 "EPO" 2 "Alarm" 1 "Warning" 0 "Normal" ;
VAL_ 80 Local_Err_PackVoltLow 3 "EPO" 2 "Alarm" 1 "Warning" 0 "Normal" ;
VAL_ 80 Local_Err_PackVoltHigh 3 "EPO" 2 "Alarm" 1 "Warning" 0 "Normal" ;
VAL_ 80 Local_Err_PackSOCLow 3 "EPO" 2 "Alarm" 1 "Warning" 0 "Normal" ;
VAL_ 80 Local_Err_PackIsoLow 3 "EPO" 2 "Alarm" 1 "Warning" 0 "Normal" ;
VAL_ 80 Local_Err_LocalCANFail 3 "EPO" 2 "Alarm" 1 "Warning" 0 "Normal" ;
VAL_ 80 Local_Err_DchCurrHigh 3 "EPO" 2 "Alarm" 1 "Warning" 0 "Normal" ;
VAL_ 80 Local_Err_ChgCurrHigh 3 "EPO" 2 "Alarm" 1 "Warning" 0 "Normal" ;
VAL_ 80 Local_Err_CellVoltLow 3 "EPO" 2 "Alarm" 1 "Warning" 0 "Normal" ;
VAL_ 80 Local_Err_CellVoltHigh 3 "EPO" 2 "Alarm" 1 "Warning" 0 "Normal" ;
VAL_ 80 Local_Err_CellTempLow 3 "EPO" 2 "Alarm" 1 "Warning" 0 "Normal" ;
VAL_ 80 Local_Err_CellTempHigh 3 "EPO" 2 "Alarm" 1 "Warning" 0 "Normal" ;
VAL_ 80 Local_Err_CellTempDiff 3 "EPO" 2 "Alarm" 1 "Warning" 0 "Normal" ;
VAL_ 80 Local_Err_RelayWeld 3 "EPO" 2 "Alarm" 1 "Warning" 0 "Normal" ;
VAL_ 80 Local_Err_PatternChaos 3 "EPO" 2 "Alarm" 1 "Warning" 0 "Normal" ;
VAL_ 80 Local_Err_IsoCANLost 3 "EPO" 2 "Alarm" 1 "Warning" 0 "Normal" ;
VAL_ 80 Local_Err_CurrSensorLost 3 "EPO" 2 "Alarm" 1 "Warning" 0 "Normal" ;
VAL_ 80 Local_Err_FcgCANLost 3 "EPO" 2 "Alarm" 1 "Warning" 0 "Normal" ;
VAL_ 80 Local_Err_CellVoltDiff 3 "EPO" 2 "Alarm" 1 "Warning" 0 "Normal" ;
VAL_ 80 Local_Err_Hvil_A 3 "EPO" 2 "Alarm" 1 "Warning" 0 "Normal" ;
VAL_ 80 Local_Err_SOP 3 "EPO" 2 "Alarm" 1 "Warning" 0 "Normal" ;
VAL_ 521 Lecu_Version1 86 "V" ;
VAL_ 521 Lecu_Version0 76 "L" ;
VAL_ 521 M16_CellBalance24 1 "on" 0 "off" ;
VAL_ 521 M16_CellBalance23 1 "on" 0 "off" ;
VAL_ 521 M16_CellBalance22 1 "on" 0 "off" ;
VAL_ 521 M16_CellBalance21 1 "on" 0 "off" ;
VAL_ 521 M16_CellBalance20 1 "on" 0 "off" ;
VAL_ 521 M16_CellBalance19 1 "on" 0 "off" ;
VAL_ 521 M16_CellBalance18 1 "on" 0 "off" ;
VAL_ 521 M16_CellBalance17 1 "on" 0 "off" ;
VAL_ 521 M16_CellBalance16 1 "on" 0 "off" ;
VAL_ 521 M16_CellBalance15 1 "on" 0 "off" ;
VAL_ 521 M16_CellBalance14 1 "on" 0 "off" ;
VAL_ 521 M16_CellBalance13 1 "on" 0 "off" ;
VAL_ 521 M16_CellBalance9 1 "on" 0 "off" ;
VAL_ 521 M16_CellBalance8 1 "on" 0 "off" ;
VAL_ 521 M16_CellBalance7 1 "on" 0 "off" ;
VAL_ 521 M16_CellBalance6 1 "on" 0 "off" ;
VAL_ 521 M16_CellBalance5 1 "on" 0 "off" ;
VAL_ 521 M16_CellBalance4 1 "on" 0 "off" ;
VAL_ 521 M16_CellBalance3 1 "on" 0 "off" ;
VAL_ 521 M16_CellBalance2 1 "on" 0 "off" ;
VAL_ 521 M16_CellBalance12 1 "on" 0 "off" ;
VAL_ 521 M16_CellBalance11 1 "on" 0 "off" ;
VAL_ 521 M16_CellBalance10 1 "on" 0 "off" ;
VAL_ 521 M16_CellBalance1 1 "on" 0 "off" ;
VAL_ 537 Lecu_Version1 86 "V" ;
VAL_ 537 Lecu_Version0 76 "L" ;
VAL_ 537 M17_CellBalance24 1 "on" 0 "off" ;
VAL_ 537 M17_CellBalance23 1 "on" 0 "off" ;
VAL_ 537 M17_CellBalance22 1 "on" 0 "off" ;
VAL_ 537 M17_CellBalance21 1 "on" 0 "off" ;
VAL_ 537 M17_CellBalance20 1 "on" 0 "off" ;
VAL_ 537 M17_CellBalance19 1 "on" 0 "off" ;
VAL_ 537 M17_CellBalance18 1 "on" 0 "off" ;
VAL_ 537 M17_CellBalance17 1 "on" 0 "off" ;
VAL_ 537 M17_CellBalance16 1 "on" 0 "off" ;
VAL_ 537 M17_CellBalance15 1 "on" 0 "off" ;
VAL_ 537 M17_CellBalance14 1 "on" 0 "off" ;
VAL_ 537 M17_CellBalance13 1 "on" 0 "off" ;
VAL_ 537 M17_CellBalance9 1 "on" 0 "off" ;
VAL_ 537 M17_CellBalance8 1 "on" 0 "off" ;
VAL_ 537 M17_CellBalance7 1 "on" 0 "off" ;
VAL_ 537 M17_CellBalance6 1 "on" 0 "off" ;
VAL_ 537 M17_CellBalance5 1 "on" 0 "off" ;
VAL_ 537 M17_CellBalance4 1 "on" 0 "off" ;
VAL_ 537 M17_CellBalance3 1 "on" 0 "off" ;
VAL_ 537 M17_CellBalance2 1 "on" 0 "off" ;
VAL_ 537 M17_CellBalance12 1 "on" 0 "off" ;
VAL_ 537 M17_CellBalance11 1 "on" 0 "off" ;
VAL_ 537 M17_CellBalance10 1 "on" 0 "off" ;
VAL_ 537 M17_CellBalance1 1 "on" 0 "off" ;
VAL_ 553 Lecu_Version1 86 "V" ;
VAL_ 553 Lecu_Version0 76 "L" ;
VAL_ 553 M18_CellBalance24 1 "on" 0 "off" ;
VAL_ 553 M18_CellBalance23 1 "on" 0 "off" ;
VAL_ 553 M18_CellBalance22 1 "on" 0 "off" ;
VAL_ 553 M18_CellBalance21 1 "on" 0 "off" ;
VAL_ 553 M18_CellBalance20 1 "on" 0 "off" ;
VAL_ 553 M18_CellBalance19 1 "on" 0 "off" ;
VAL_ 553 M18_CellBalance18 1 "on" 0 "off" ;
VAL_ 553 M18_CellBalance17 1 "on" 0 "off" ;
VAL_ 553 M18_CellBalance16 1 "on" 0 "off" ;
VAL_ 553 M18_CellBalance15 1 "on" 0 "off" ;
VAL_ 553 M18_CellBalance14 1 "on" 0 "off" ;
VAL_ 553 M18_CellBalance13 1 "on" 0 "off" ;
VAL_ 553 M18_CellBalance9 1 "on" 0 "off" ;
VAL_ 553 M18_CellBalance8 1 "on" 0 "off" ;
VAL_ 553 M18_CellBalance7 1 "on" 0 "off" ;
VAL_ 553 M18_CellBalance6 1 "on" 0 "off" ;
VAL_ 553 M18_CellBalance5 1 "on" 0 "off" ;
VAL_ 553 M18_CellBalance4 1 "on" 0 "off" ;
VAL_ 553 M18_CellBalance3 1 "on" 0 "off" ;
VAL_ 553 M18_CellBalance2 1 "on" 0 "off" ;
VAL_ 553 M18_CellBalance12 1 "on" 0 "off" ;
VAL_ 553 M18_CellBalance11 1 "on" 0 "off" ;
VAL_ 553 M18_CellBalance10 1 "on" 0 "off" ;
VAL_ 553 M18_CellBalance1 1 "on" 0 "off" ;
VAL_ 569 Lecu_Version1 86 "V" ;
VAL_ 569 Lecu_Version0 76 "L" ;
VAL_ 569 M19_CellBalance24 1 "on" 0 "off" ;
VAL_ 569 M19_CellBalance23 1 "on" 0 "off" ;
VAL_ 569 M19_CellBalance22 1 "on" 0 "off" ;
VAL_ 569 M19_CellBalance21 1 "on" 0 "off" ;
VAL_ 569 M19_CellBalance20 1 "on" 0 "off" ;
VAL_ 569 M19_CellBalance19 1 "on" 0 "off" ;
VAL_ 569 M19_CellBalance18 1 "on" 0 "off" ;
VAL_ 569 M19_CellBalance17 1 "on" 0 "off" ;
VAL_ 569 M19_CellBalance16 1 "on" 0 "off" ;
VAL_ 569 M19_CellBalance15 1 "on" 0 "off" ;
VAL_ 569 M19_CellBalance14 1 "on" 0 "off" ;
VAL_ 569 M19_CellBalance13 1 "on" 0 "off" ;
VAL_ 569 M19_CellBalance9 1 "on" 0 "off" ;
VAL_ 569 M19_CellBalance8 1 "on" 0 "off" ;
VAL_ 569 M19_CellBalance7 1 "on" 0 "off" ;
VAL_ 569 M19_CellBalance6 1 "on" 0 "off" ;
VAL_ 569 M19_CellBalance5 1 "on" 0 "off" ;
VAL_ 569 M19_CellBalance4 1 "on" 0 "off" ;
VAL_ 569 M19_CellBalance3 1 "on" 0 "off" ;
VAL_ 569 M19_CellBalance2 1 "on" 0 "off" ;
VAL_ 569 M19_CellBalance12 1 "on" 0 "off" ;
VAL_ 569 M19_CellBalance11 1 "on" 0 "off" ;
VAL_ 569 M19_CellBalance10 1 "on" 0 "off" ;
VAL_ 569 M19_CellBalance1 1 "on" 0 "off" ;
VAL_ 585 Lecu_Version1 86 "V" ;
VAL_ 585 Lecu_Version0 76 "L" ;
VAL_ 585 M20_CellBalance24 1 "on" 0 "off" ;
VAL_ 585 M20_CellBalance23 1 "on" 0 "off" ;
VAL_ 585 M20_CellBalance22 1 "on" 0 "off" ;
VAL_ 585 M20_CellBalance21 1 "on" 0 "off" ;
VAL_ 585 M20_CellBalance20 1 "on" 0 "off" ;
VAL_ 585 M20_CellBalance19 1 "on" 0 "off" ;
VAL_ 585 M20_CellBalance18 1 "on" 0 "off" ;
VAL_ 585 M20_CellBalance17 1 "on" 0 "off" ;
VAL_ 585 M20_CellBalance16 1 "on" 0 "off" ;
VAL_ 585 M20_CellBalance15 1 "on" 0 "off" ;
VAL_ 585 M20_CellBalance14 1 "on" 0 "off" ;
VAL_ 585 M20_CellBalance13 1 "on" 0 "off" ;
VAL_ 585 M20_CellBalance9 1 "on" 0 "off" ;
VAL_ 585 M20_CellBalance8 1 "on" 0 "off" ;
VAL_ 585 M20_CellBalance7 1 "on" 0 "off" ;
VAL_ 585 M20_CellBalance6 1 "on" 0 "off" ;
VAL_ 585 M20_CellBalance5 1 "on" 0 "off" ;
VAL_ 585 M20_CellBalance4 1 "on" 0 "off" ;
VAL_ 585 M20_CellBalance3 1 "on" 0 "off" ;
VAL_ 585 M20_CellBalance2 1 "on" 0 "off" ;
VAL_ 585 M20_CellBalance12 1 "on" 0 "off" ;
VAL_ 585 M20_CellBalance11 1 "on" 0 "off" ;
VAL_ 585 M20_CellBalance10 1 "on" 0 "off" ;
VAL_ 585 M20_CellBalance1 1 "on" 0 "off" ;
VAL_ 601 Lecu_Version1 86 "V" ;
VAL_ 601 Lecu_Version0 76 "L" ;
VAL_ 601 M21_CellBalance24 1 "on" 0 "off" ;
VAL_ 601 M21_CellBalance23 1 "on" 0 "off" ;
VAL_ 601 M21_CellBalance22 1 "on" 0 "off" ;
VAL_ 601 M21_CellBalance21 1 "on" 0 "off" ;
VAL_ 601 M21_CellBalance20 1 "on" 0 "off" ;
VAL_ 601 M21_CellBalance19 1 "on" 0 "off" ;
VAL_ 601 M21_CellBalance18 1 "on" 0 "off" ;
VAL_ 601 M21_CellBalance17 1 "on" 0 "off" ;
VAL_ 601 M21_CellBalance16 1 "on" 0 "off" ;
VAL_ 601 M21_CellBalance15 1 "on" 0 "off" ;
VAL_ 601 M21_CellBalance14 1 "on" 0 "off" ;
VAL_ 601 M21_CellBalance13 1 "on" 0 "off" ;
VAL_ 601 M21_CellBalance9 1 "on" 0 "off" ;
VAL_ 601 M21_CellBalance8 1 "on" 0 "off" ;
VAL_ 601 M21_CellBalance7 1 "on" 0 "off" ;
VAL_ 601 M21_CellBalance6 1 "on" 0 "off" ;
VAL_ 601 M21_CellBalance5 1 "on" 0 "off" ;
VAL_ 601 M21_CellBalance4 1 "on" 0 "off" ;
VAL_ 601 M21_CellBalance3 1 "on" 0 "off" ;
VAL_ 601 M21_CellBalance2 1 "on" 0 "off" ;
VAL_ 601 M21_CellBalance12 1 "on" 0 "off" ;
VAL_ 601 M21_CellBalance11 1 "on" 0 "off" ;
VAL_ 601 M21_CellBalance10 1 "on" 0 "off" ;
VAL_ 601 M21_CellBalance1 1 "on" 0 "off" ;
VAL_ 617 Lecu_Version1 86 "V" ;
VAL_ 617 Lecu_Version0 76 "L" ;
VAL_ 617 M22_CellBalance24 1 "on" 0 "off" ;
VAL_ 617 M22_CellBalance23 1 "on" 0 "off" ;
VAL_ 617 M22_CellBalance22 1 "on" 0 "off" ;
VAL_ 617 M22_CellBalance21 1 "on" 0 "off" ;
VAL_ 617 M22_CellBalance20 1 "on" 0 "off" ;
VAL_ 617 M22_CellBalance19 1 "on" 0 "off" ;
VAL_ 617 M22_CellBalance18 1 "on" 0 "off" ;
VAL_ 617 M22_CellBalance17 1 "on" 0 "off" ;
VAL_ 617 M22_CellBalance16 1 "on" 0 "off" ;
VAL_ 617 M22_CellBalance15 1 "on" 0 "off" ;
VAL_ 617 M22_CellBalance14 1 "on" 0 "off" ;
VAL_ 617 M22_CellBalance13 1 "on" 0 "off" ;
VAL_ 617 M22_CellBalance9 1 "on" 0 "off" ;
VAL_ 617 M22_CellBalance8 1 "on" 0 "off" ;
VAL_ 617 M22_CellBalance7 1 "on" 0 "off" ;
VAL_ 617 M22_CellBalance6 1 "on" 0 "off" ;
VAL_ 617 M22_CellBalance5 1 "on" 0 "off" ;
VAL_ 617 M22_CellBalance4 1 "on" 0 "off" ;
VAL_ 617 M22_CellBalance3 1 "on" 0 "off" ;
VAL_ 617 M22_CellBalance2 1 "on" 0 "off" ;
VAL_ 617 M22_CellBalance12 1 "on" 0 "off" ;
VAL_ 617 M22_CellBalance11 1 "on" 0 "off" ;
VAL_ 617 M22_CellBalance10 1 "on" 0 "off" ;
VAL_ 617 M22_CellBalance1 1 "on" 0 "off" ;
